VERSION "ZCUD_CANFD3"

NS_ :

BS_:

BU_: ASDM ETC HVFM SRS3 SUM XCM ZCUD ZCUT

BO_ 85 ZcudZCUDCANFD3Fr01: 64 ZCUD
 SG_ EscSt_UB : 192|1@0+ (1,0) [0|1] "" Vector__XXX
 SG_ EscStChks : 191|8@0+ (1,0) [0|255] "Unitless" Vector__XXX
 SG_ EscStCntr : 199|4@0+ (1,0) [0|15] "Unitless" Vector__XXX
 SG_ EscStEscSt : 195|3@0+ (1,0) [0|7] "" Vector__XXX
 SG_ GearLvrIndcn : 43|3@0+ (1,0) [0|7] "" Vector__XXX
 SG_ GearLvrIndcn_UB : 40|1@0+ (1,0) [0|1] "" Vector__XXX
 SG_ GVMCPrpsnTqDistReq_UB : 475|1@0+ (1,0) [0|1] "" XCM
 SG_ GVMCPrpsnTqDistReqChks : 471|8@0+ (1,0) [0|255] "Unitless" XCM
 SG_ GVMCPrpsnTqDistReqCntr : 479|4@0+ (1,0) [0|15] "Unitless" XCM
 SG_ GVMCPrpsnTqDistReqCtrlMod : 456|1@0+ (1,0) [0|1] "" XCM
 SG_ GVMCPrpsnTqDistReqDistReq : 455|15@0+ (0.00390625,0) [0|100] "%" XCM
 SG_ GVMCSteerWhlAgReqFrnt_UB : 276|1@0+ (1,0) [0|1] "" Vector__XXX
 SG_ GVMCSteerWhlAgReqFrntChks : 258|8@0+ (1,0) [0|255] "Unitless" Vector__XXX
 SG_ GVMCSteerWhlAgReqFrntCntr : 266|4@0+ (1,0) [0|15] "Unitless" Vector__XXX
 SG_ GVMCSteerWhlAgReqFrntSteerWhlAgCtrl : 239|15@0- (9.765625E-4,0) [-14.5|14.5] "rad" Vector__XXX
 SG_ GVMCSteerWhlAgReqFrntSteerWhlCtrlSts : 278|2@0+ (1,0) [0|3] "" Vector__XXX
 SG_ GVMCSteerWhlAgReqFrntSteerWhlTqCtrl : 240|14@0- (0.00390625,0) [-30|30] "NewtonMeter" Vector__XXX
 SG_ GVMCVehCtrlrSts_UB : 363|1@0+ (1,0) [0|1] "" XCM
 SG_ GVMCVehCtrlrStsChks : 351|8@0+ (1,0) [0|255] "Unitless" XCM
 SG_ GVMCVehCtrlrStsCntr : 367|4@0+ (1,0) [0|15] "Unitless" XCM
 SG_ GVMCVehCtrlrStsCtrlrSts : 359|8@0+ (1,0) [0|255] "" XCM
 SG_ GVMCVehVAct_UB : 125|1@0+ (1,0) [0|1] "" XCM
 SG_ GVMCVehVActLatAct : 95|16@0+ (0.00391,-30) [-30|34.05753] "m/s" XCM
 SG_ GVMCVehVActLgtAct : 111|16@0+ (0.00391,-30) [-30|34.05753] "m/s" XCM
 SG_ GVMCVehVActQf : 127|2@0+ (1,0) [0|3] "" XCM
 SG_ GVMCVehYawRateTar : 287|32@0+ (1,-10) [-10|10] "rad/s" XCM
 SG_ GVMCVehYawRateTar_UB : 123|1@0+ (1,0) [0|1] "" XCM
 SG_ GVMCYawRateCOGAct_UB : 181|1@0+ (1,0) [0|1] "" XCM
 SG_ GVMCYawRateCOGActAct : 167|16@0+ (2.4E-4,-6) [-6|9.7284] "rad/s" XCM
 SG_ GVMCYawRateCOGActQf : 183|2@0+ (1,0) [0|3] "" XCM
 SG_ LatCtrlReqSafe_UB : 336|1@0+ (1,0) [0|1] "" Vector__XXX
 SG_ LatCtrlReqSafeChks : 321|8@0+ (1,0) [0|255] "Unitless" Vector__XXX
 SG_ LatCtrlReqSafeCntr : 329|4@0+ (1,0) [0|15] "Unitless" Vector__XXX
 SG_ LatCtrlReqSafeLatCtrlModReq : 341|4@0+ (1,0) [0|15] "" Vector__XXX
 SG_ LatCtrlReqSafeSteerTqReq : 319|14@0- (0.00390625,0) [-30|30] "NewtonMeter" Vector__XXX
 SG_ LatCtrlReqSafeSteerWhlHptcWarnReq : 337|1@0+ (1,0) [0|1] "" Vector__XXX
 SG_ SteerWhlSnsr_UB : 44|1@0+ (1,0) [0|1] "" Vector__XXX
 SG_ SteerWhlSnsrAg : 7|15@0- (9.765625E-4,0) [-14.5|14.5] "rad" Vector__XXX
 SG_ SteerWhlSnsrAgSpd : 8|14@0- (0.0078125,0) [-50|50] "rad/s" Vector__XXX
 SG_ SteerWhlSnsrChks : 26|8@0+ (1,0) [0|255] "Unitless" Vector__XXX
 SG_ SteerWhlSnsrCntr : 34|4@0+ (1,0) [0|15] "Unitless" Vector__XXX
 SG_ SteerWhlSnsrQf : 46|2@0+ (1,0) [0|3] "" Vector__XXX
 SG_ VehModMngtGlbSafe1_UB : 80|1@0+ (1,0) [0|1] "" HVFM,SUM
 SG_ VehModMngtGlbSafe1CarModSts1 : 87|3@0+ (1,0) [0|7] "" HVFM,SUM
 SG_ VehModMngtGlbSafe1CarModSubtypWdCarModSubtyp : 84|3@0+ (1,0) [0|7] "Unitless" HVFM,SUM
 SG_ VehModMngtGlbSafe1Chks : 55|8@0+ (1,0) [0|255] "Unitless" HVFM,SUM
 SG_ VehModMngtGlbSafe1Cntr : 63|4@0+ (1,0) [0|15] "Unitless" HVFM,SUM
 SG_ VehModMngtGlbSafe1EgyLvlElecMai : 59|4@0+ (1,0) [0|15] "Unitless" HVFM,SUM
 SG_ VehModMngtGlbSafe1EgyLvlElecSubtyp : 71|4@0+ (1,0) [0|15] "Unitless" HVFM,SUM
 SG_ VehModMngtGlbSafe1FltEgyCnsWdSts : 81|1@0+ (1,0) [0|1] "" HVFM,SUM
 SG_ VehModMngtGlbSafe1PwrLvlElecMai : 67|4@0+ (1,0) [0|15] "Unitless" HVFM,SUM
 SG_ VehModMngtGlbSafe1PwrLvlElecSubtyp : 79|4@0+ (1,0) [0|15] "Unitless" HVFM,SUM
 SG_ VehModMngtGlbSafe1UsgModSts : 75|4@0+ (1,0) [0|15] "" HVFM,SUM
 SG_ VehMtnSt_UB : 208|1@0+ (1,0) [0|1] "" ZCUT
 SG_ VehMtnStChks : 207|8@0+ (1,0) [0|255] "Unitless" ZCUT
 SG_ VehMtnStCntr : 215|4@0+ (1,0) [0|15] "Unitless" ZCUT
 SG_ VehMtnStVehMtnSt : 211|3@0+ (1,0) [0|7] "" ZCUT
 SG_ VehSpdLgt_UB : 154|1@0+ (1,0) [0|1] "" HVFM,SUM,ZCUT
 SG_ VehSpdLgtA : 135|15@0+ (0.00391,0) [0|125.0027] "m/s" HVFM,SUM,ZCUT
 SG_ VehSpdLgtChks : 136|8@0+ (1,0) [0|255] "Unitless" HVFM,SUM,ZCUT
 SG_ VehSpdLgtCntr : 144|4@0+ (1,0) [0|15] "Unitless" HVFM,SUM,ZCUT
 SG_ VehSpdLgtQf : 156|2@0+ (1,0) [0|3] "" HVFM,SUM,ZCUT
 SG_ WhlFastSpdSafe_UB : 442|1@0+ (1,0) [0|1] "" Vector__XXX
 SG_ WhlFastSpdSafeA : 423|15@0+ (0.00391,0) [0|125.0027] "m/s" Vector__XXX
 SG_ WhlFastSpdSafeChks : 424|8@0+ (1,0) [0|255] "Unitless" Vector__XXX
 SG_ WhlFastSpdSafeCntr : 432|4@0+ (1,0) [0|15] "Unitless" Vector__XXX
 SG_ WhlFastSpdSafeQF : 444|2@0+ (1,0) [0|3] "" Vector__XXX
 SG_ WhlRotToothCntr_UB : 411|1@0+ (1,0) [0|1] "" Vector__XXX
 SG_ WhlRotToothCntrChks : 375|8@0+ (1,0) [0|255] "Unitless" Vector__XXX
 SG_ WhlRotToothCntrCntr : 415|4@0+ (1,0) [0|15] "Unitless" Vector__XXX
 SG_ WhlRotToothCntrFrntLe : 383|8@0+ (1,0) [0|255] "Unitless" Vector__XXX
 SG_ WhlRotToothCntrFrntRi : 391|8@0+ (1,0) [0|255] "Unitless" Vector__XXX
 SG_ WhlRotToothCntrReLe : 399|8@0+ (1,0) [0|255] "Unitless" Vector__XXX
 SG_ WhlRotToothCntrReRi : 407|8@0+ (1,0) [0|255] "Unitless" Vector__XXX
 SG_ YawRateReqdByDrvr : 223|16@0- (2.44140625E-4,0) [-5|5] "rad/s" Vector__XXX
 SG_ YawRateReqdByDrvr_UB : 124|1@0+ (1,0) [0|1] "" Vector__XXX

BO_ 339 ZcudZCUDCANFD3Fr02: 64 ZCUD
 SG_ DrvrGearShiftDirReq1_UB : 46|1@0+ (1,0) [0|1] "" Vector__XXX
 SG_ DrvrGearShiftDirReq1Chks : 31|8@0+ (1,0) [0|255] "Unitless" Vector__XXX
 SG_ DrvrGearShiftDirReq1Cntr : 39|4@0+ (1,0) [0|15] "Unitless" Vector__XXX
 SG_ DrvrGearShiftDirReq1DwnDwnTipAut : 35|1@0+ (1,0) [0|1] "" Vector__XXX
 SG_ DrvrGearShiftDirReq1DwnTipAut : 34|1@0+ (1,0) [0|1] "" Vector__XXX
 SG_ DrvrGearShiftDirReq1PosnAut : 33|1@0+ (1,0) [0|1] "" Vector__XXX
 SG_ DrvrGearShiftDirReq1UpTipAut : 32|1@0+ (1,0) [0|1] "" Vector__XXX
 SG_ DrvrGearShiftDirReq1UpUpTipAut : 47|1@0+ (1,0) [0|1] "" Vector__XXX
 SG_ DrvrGearShiftDirReq2_UB : 60|1@0+ (1,0) [0|1] "" Vector__XXX
 SG_ DrvrGearShiftDirReq2Chks : 45|8@0+ (1,0) [0|255] "Unitless" Vector__XXX
 SG_ DrvrGearShiftDirReq2Cntr : 53|4@0+ (1,0) [0|15] "Unitless" Vector__XXX
 SG_ DrvrGearShiftDirReq2DwnDwnTipAut : 49|1@0+ (1,0) [0|1] "" Vector__XXX
 SG_ DrvrGearShiftDirReq2DwnTipAut : 48|1@0+ (1,0) [0|1] "" Vector__XXX
 SG_ DrvrGearShiftDirReq2PosnAut : 63|1@0+ (1,0) [0|1] "" Vector__XXX
 SG_ DrvrGearShiftDirReq2UpTipAut : 62|1@0+ (1,0) [0|1] "" Vector__XXX
 SG_ DrvrGearShiftDirReq2UpUpTipAut : 61|1@0+ (1,0) [0|1] "" Vector__XXX
 SG_ RWASteerLockReq_UB : 189|1@0+ (1,0) [0|1] "" Vector__XXX
 SG_ RWASteerLockReqCommand : 191|2@0+ (1,0) [0|3] "" Vector__XXX
 SG_ RWASteerLockReqSteerLockDataReq0 : 135|8@0+ (1,0) [0|255] "Unitless" Vector__XXX
 SG_ RWASteerLockReqSteerLockDataReq1 : 143|8@0+ (1,0) [0|255] "Unitless" Vector__XXX
 SG_ RWASteerLockReqSteerLockDataReq2 : 151|8@0+ (1,0) [0|255] "Unitless" Vector__XXX
 SG_ RWASteerLockReqSteerLockDataReq3 : 159|8@0+ (1,0) [0|255] "Unitless" Vector__XXX
 SG_ RWASteerLockReqSteerLockDataReq4 : 167|8@0+ (1,0) [0|255] "Unitless" Vector__XXX
 SG_ RWASteerLockReqSteerLockDataReq5 : 175|8@0+ (1,0) [0|255] "Unitless" Vector__XXX
 SG_ RWASteerLockReqSteerLockDataReq6 : 183|8@0+ (1,0) [0|255] "Unitless" Vector__XXX
 SG_ SteerEmergCtrlSwt : 127|1@0+ (1,0) [0|1] "" Vector__XXX
 SG_ SteerEmergCtrlSwt_UB : 126|1@0+ (1,0) [0|1] "" Vector__XXX
 SG_ SteerRatModReq : 101|5@0+ (1,0) [0|31] "" Vector__XXX
 SG_ SteerRatModReq_UB : 96|1@0+ (1,0) [0|1] "" Vector__XXX
 SG_ SteerSetg_UB : 80|1@0+ (1,0) [0|1] "" Vector__XXX
 SG_ SteerSetgPen : 74|4@0+ (1,0) [0|15] "" Vector__XXX
 SG_ SteerSetgSteerAsscLvl : 86|3@0+ (1,0) [0|7] "" Vector__XXX
 SG_ SteerSetgSteerMod : 83|3@0+ (1,0) [0|7] "" Vector__XXX
 SG_ SuspCmprSpd : 95|9@0+ (1,0) [0|511] "rpm" SUM
 SG_ SuspCmprSpd_UB : 102|1@0+ (1,0) [0|1] "" SUM
 SG_ SuspDistbnVlvCtrlSts_UB : 113|1@0+ (1,0) [0|1] "" SUM
 SG_ SuspDistbnVlvCtrlStsChks : 11|8@0+ (1,0) [0|255] "Unitless" SUM
 SG_ SuspDistbnVlvCtrlStsCntr : 19|4@0+ (1,0) [0|15] "Unitless" SUM
 SG_ SuspDistbnVlvCtrlStsSuspDistbnVlvCtrlSts : 7|12@0+ (1,0) [0|4095] "Unitless" SUM
 SG_ SuspStfnVlvCtrlSts_UB : 122|1@0+ (1,0) [0|1] "" SUM
 SG_ SuspStfnVlvCtrlStsFL : 111|2@0+ (1,0) [0|3] "" SUM
 SG_ SuspStfnVlvCtrlStsFR : 109|2@0+ (1,0) [0|3] "" SUM
 SG_ SuspStfnVlvCtrlStsRL : 107|2@0+ (1,0) [0|3] "" SUM
 SG_ SuspStfnVlvCtrlStsRR : 105|2@0+ (1,0) [0|3] "" SUM
 SG_ ZCAirSuspCtrlSts_UB : 201|1@0+ (1,0) [0|1] "" SUM
 SG_ ZCAirSuspCtrlStsChks : 199|8@0+ (1,0) [0|255] "Unitless" SUM
 SG_ ZCAirSuspCtrlStsCntr : 207|4@0+ (1,0) [0|15] "Unitless" SUM
 SG_ ZCAirSuspCtrlStsZCAirSuspCtrlSts : 203|2@0+ (1,0) [0|3] "" SUM

BO_ 289 ZcudZCUDCANFD3Fr03: 64 ZCUD
 SG_ BBWPullOverReq : 67|1@0+ (1,0) [0|1] "" ASDM
 SG_ BBWPullOverReq_UB : 66|1@0+ (1,0) [0|1] "" ASDM
 SG_ BrkPedlPsd_UB : 68|1@0+ (1,0) [0|1] "" Vector__XXX
 SG_ BrkPedlPsdBrkPedlNotPsdSafe : 49|1@0+ (1,0) [0|1] "" Vector__XXX
 SG_ BrkPedlPsdBrkPedlPsd : 48|1@0+ (1,0) [0|1] "" Vector__XXX
 SG_ BrkPedlPsdChks : 47|8@0+ (1,0) [0|255] "Unitless" Vector__XXX
 SG_ BrkPedlPsdCntr : 55|4@0+ (1,0) [0|15] "Unitless" Vector__XXX
 SG_ BrkPedlPsdQf : 51|2@0+ (1,0) [0|3] "" Vector__XXX
 SG_ ChassisObstclCrsModIncn : 34|2@0+ (1,0) [0|3] "" ZCUT
 SG_ ChassisObstclCrsModIncn_UB : 32|1@0+ (1,0) [0|1] "" ZCUT
 SG_ HeiLimModIncn : 71|2@0+ (1,0) [0|3] "" ZCUT
 SG_ HeiLimModIncn_UB : 69|1@0+ (1,0) [0|1] "" ZCUT
 SG_ PTALgtLimnlnd : 79|12@0+ (0.01,-12) [-12|12] "m/s^2" ASDM
 SG_ PTALgtLimnlnd_UB : 83|1@0+ (1,0) [0|1] "" ASDM

BO_ 1173 ZcudZCUDCANFD3Fr05: 64 ZCUD
 SG_ BkpOfDstTrvld : 63|21@0+ (1,0) [0|2000000] "km" HVFM,SUM
 SG_ BkpOfDstTrvld_UB : 74|1@0+ (1,0) [0|1] "" HVFM,SUM
 SG_ CarTiGlb : 7|32@0+ (0.1,0) [0|429496729.5] "s" HVFM,SUM
 SG_ CarTiGlb_UB : 39|1@0+ (1,0) [0|1] "" HVFM,SUM
 SG_ TiAndDateIndcn_UB : 73|1@0+ (1,0) [0|1] "" HVFM,SUM
 SG_ TiAndDateIndcnDataValid : 175|1@0+ (1,0) [0|1] "" HVFM,SUM
 SG_ TiAndDateIndcnDay : 196|5@0+ (1,0) [1|31] "Days" HVFM,SUM
 SG_ TiAndDateIndcnHr1 : 204|5@0+ (1,0) [0|23] "hours" HVFM,SUM
 SG_ TiAndDateIndcnMins1 : 181|6@0+ (1,0) [0|59] "Mins" HVFM,SUM
 SG_ TiAndDateIndcnMth1 : 211|4@0+ (1,0) [1|12] "Month" HVFM,SUM
 SG_ TiAndDateIndcnSec1 : 189|6@0+ (1,0) [0|59] "s" HVFM,SUM
 SG_ TiAndDateIndcnYr1 : 174|7@0+ (1,0) [0|99] "Year" HVFM,SUM
 SG_ VehBattU_UB : 229|1@0+ (1,0) [0|1] "" HVFM,SUM
 SG_ VehBattUSysU : 223|8@0+ (0.1,0) [0|25] "Volt" HVFM,SUM
 SG_ VehBattUSysUQf : 231|2@0+ (1,0) [0|3] "" HVFM,SUM

BO_ 569 ZcudZCUDCANFD3Fr06: 64 ZCUD
 SG_ BattIRaw : 95|16@0+ (0.015625,-512) [-512|511.984375] "A" Vector__XXX
 SG_ BattIRaw_UB : 128|1@0+ (1,0) [0|1] "" Vector__XXX
 SG_ BattRemainTimeToEmpty : 111|15@0+ (0.1,0) [0|3076.7] "Mins" Vector__XXX
 SG_ BattRemainTimeToEmpty_UB : 112|1@0+ (1,0) [0|1] "" Vector__XXX
 SG_ DrvModReq : 127|5@0+ (1,0) [0|31] "" Vector__XXX
 SG_ DrvModReq_UB : 122|1@0+ (1,0) [0|1] "" Vector__XXX
 SG_ DrvrSeatSnsrSts : 143|2@0+ (1,0) [0|3] "" Vector__XXX
 SG_ DrvrSeatSnsrSts_UB : 141|1@0+ (1,0) [0|1] "" Vector__XXX
 SG_ DrvrSeatSts : 140|2@0+ (1,0) [0|3] "" Vector__XXX
 SG_ DrvrSeatSts_UB : 138|1@0+ (1,0) [0|1] "" Vector__XXX
 SG_ IAMSMod : 121|1@0+ (1,0) [0|1] "" ZCUT
 SG_ IAMSMod_UB : 120|1@0+ (1,0) [0|1] "" ZCUT
 SG_ LockgCenSts_UB : 152|1@0+ (1,0) [0|1] "" Vector__XXX
 SG_ LockgCenStsLockSt : 155|2@0+ (1,0) [0|3] "" Vector__XXX
 SG_ LockgCenStsTrigSrc : 159|4@0+ (1,0) [0|15] "" Vector__XXX
 SG_ LockgCenStsUpdEve : 153|1@0+ (1,0) [0|1] "" Vector__XXX
 SG_ PtTqAtWhlFrntAct_UB : 56|1@0+ (1,0) [0|1] "" Vector__XXX
 SG_ PtTqAtWhlFrntActChks : 55|8@0+ (1,0) [0|255] "Unitless" Vector__XXX
 SG_ PtTqAtWhlFrntActCntr : 63|4@0+ (1,0) [0|15] "Unitless" Vector__XXX
 SG_ PtTqAtWhlFrntActPtTqAtAxleFrntAct : 7|16@0- (1,0) [-20000|20000] "NewtonMeter" Vector__XXX
 SG_ PtTqAtWhlFrntActPtTqAtWhlFrntLeAct : 23|16@0- (1,0) [-20000|20000] "NewtonMeter" Vector__XXX
 SG_ PtTqAtWhlFrntActPtTqAtWhlFrntRiAct : 39|16@0- (1,0) [-20000|20000] "NewtonMeter" Vector__XXX
 SG_ PtTqAtWhlFrntActPtTqAtWhlsFrntQly : 59|3@0+ (1,0) [0|7] "" Vector__XXX
 SG_ PVMCSteerAst : 135|3@0+ (1,0) [0|7] "" Vector__XXX
 SG_ PVMCSteerAst_UB : 132|1@0+ (1,0) [0|1] "" Vector__XXX

BO_ 625 ZcudZCUDCANFD3Fr07: 64 ZCUD
 SG_ AmbTRaw_UB : 18|1@0+ (1,0) [0|1] "" Vector__XXX
 SG_ AmbTRawAmbTVal : 15|11@0+ (0.1,-70) [-70|134.7] "degC" Vector__XXX
 SG_ AmbTRawQly : 20|2@0+ (1,0) [0|3] "" Vector__XXX
 SG_ DstEstimdToEmptyForDrvgElec : 31|11@0+ (1,0) [0|2047] "KiloMtr" ASDM
 SG_ DstEstimdToEmptyForDrvgElec_UB : 36|1@0+ (1,0) [0|1] "" ASDM
 SG_ DstEstimdToEmptyForDrvgElecPredTyp2 : 35|11@0+ (1,0) [0|2047] "KiloMtr" ASDM
 SG_ DstEstimdToEmptyForDrvgElecPredTyp2_UB : 40|1@0+ (1,0) [0|1] "" ASDM
 SG_ DstEstimdToEmptyForDynElec : 55|11@0+ (1,0) [0|2047] "KiloMtr" ASDM
 SG_ DstEstimdToEmptyForDynElec_UB : 60|1@0+ (1,0) [0|1] "" ASDM
 SG_ DstToEmptyIndcdDstToEmpty1 : 71|13@0+ (1,0) [0|8191] "KiloMtr" ASDM
 SG_ DstToEmptyIndcdDstToEmpty1_UB : 74|1@0+ (1,0) [0|1] "" ASDM
 SG_ DstToEmptyIndcdDstToEmpty2 : 87|13@0+ (1,0) [0|8191] "KiloMtr" ASDM
 SG_ DstToEmptyIndcdDstToEmpty2_UB : 90|1@0+ (1,0) [0|1] "" ASDM
 SG_ DstToEmptyIndcdDstToEmpty3 : 103|13@0+ (1,0) [0|8191] "KiloMtr" ASDM
 SG_ DstToEmptyIndcdDstToEmpty3_UB : 106|1@0+ (1,0) [0|1] "" ASDM

BO_ 131 ZcudZCUDCANFD3Fr08: 16 ZCUD
 SG_ DPAAgReqGroup1_UB : 97|1@0+ (1,0) [0|1] "" XCM
 SG_ DPAAgReqGroup1Chks : 93|8@0+ (1,0) [0|255] "Unitless" XCM
 SG_ DPAAgReqGroup1Cntr : 101|4@0+ (1,0) [0|15] "Unitless" XCM
 SG_ DPAAgReqGroup1RtonAgReq : 55|14@0+ (0.05,-360) [-360|459.15] "Deg" XCM
 SG_ DPAAgReqGroup1TrgtAg : 57|14@0+ (0.05,-360) [-360|459.15] "Deg" XCM
 SG_ DPAAgReqGroup1VehAtaRtonlAg : 75|14@0+ (0.05,-360) [-360|459.15] "Deg" XCM
 SG_ DPAAgReqGroup_UB : 96|1@0+ (1,0) [0|1] "" XCM
 SG_ DPAAgReqGroupChks : 47|8@0+ (1,0) [0|255] "Unitless" XCM
 SG_ DPAAgReqGroupCntr : 35|4@0+ (1,0) [0|15] "Unitless" XCM
 SG_ DPAAgReqGroupRtonAgReq : 7|12@0+ (0.1,0) [0|360] "Deg" XCM
 SG_ DPAAgReqGroupTrgtAg : 11|12@0+ (0.1,0) [0|360] "Deg" XCM
 SG_ DPAAgReqGroupVehAtaRtonlAg : 31|12@0+ (0.1,0) [0|360] "Deg" XCM

BO_ 102 ZcudZCUDCANFD3Fr09: 64 ZCUD
 SG_ AbsCtrlActv_UB : 138|1@0+ (1,0) [0|1] "" ZCUT
 SG_ AbsCtrlActvChks : 135|8@0+ (1,0) [0|255] "Unitless" ZCUT
 SG_ AbsCtrlActvCntr : 143|4@0+ (1,0) [0|15] "Unitless" ZCUT
 SG_ AbsCtrlActvCtrlSts1 : 139|1@0+ (1,0) [0|1] "" ZCUT
 SG_ BrkTracCtrlActv : 66|1@0+ (1,0) [0|1] "" Vector__XXX
 SG_ BrkTracCtrlActv_UB : 65|1@0+ (1,0) [0|1] "" Vector__XXX
 SG_ GVMCPrpsnTqDistbnReqAtAxleRe_UB : 328|1@0+ (1,0) [0|1] "" XCM
 SG_ GVMCPrpsnTqDistbnReqAtAxleReChks : 325|8@0+ (1,0) [0|255] "Unitless" XCM
 SG_ GVMCPrpsnTqDistbnReqAtAxleReCntr : 333|4@0+ (1,0) [0|15] "Unitless" XCM
 SG_ GVMCPrpsnTqDistbnReqAtAxleReCtrlMod : 329|1@0+ (1,0) [0|1] "" XCM
 SG_ GVMCPrpsnTqDistbnReqAtAxleReDistReq : 311|18@0+ (0.01,-1000) [-1000|1621.43] "%" XCM
 SG_ GVMCSuspDampgCtrlReq_UB : 67|1@0+ (1,0) [0|1] "" ZCUT
 SG_ GVMCSuspDampgCtrlReqGVMCDampgCtrlReqFL : 7|16@0- (1,0) [-20000|20000] "N" ZCUT
 SG_ GVMCSuspDampgCtrlReqGVMCDampgCtrlReqFR : 23|16@0- (1,0) [-20000|20000] "N" ZCUT
 SG_ GVMCSuspDampgCtrlReqGVMCDampgCtrlReqRL : 39|16@0- (1,0) [-20000|20000] "N" ZCUT
 SG_ GVMCSuspDampgCtrlReqGVMCDampgCtrlReqRR : 55|16@0- (1,0) [-20000|20000] "N" ZCUT
 SG_ GVMCSuspDampgCtrlReqGVMCSuspDampgCtrlMod : 71|2@0+ (1,0) [0|3] "" ZCUT
 SG_ GVMCSuspDampgCtrlReqGVMCSuspDampgModReq : 69|2@0+ (1,0) [0|3] "" ZCUT
 SG_ PVMCSuspHeiCtrlReq_UB : 406|1@0+ (1,0) [0|1] "" ZCUT
 SG_ PVMCSuspHeiCtrlReqGVMCSuspPosnCtrlMod : 392|2@0+ (1,0) [0|3] "" ZCUT
 SG_ PVMCSuspHeiCtrlReqGVMCSuspPosnFLReq : 343|15@0- (6.2E-5,0) [-0.999998|1.00006] "m" ZCUT
 SG_ PVMCSuspHeiCtrlReqGVMCSuspPosnFRReq : 344|15@0- (6.2E-5,0) [-0.999998|1.00006] "m" ZCUT
 SG_ PVMCSuspHeiCtrlReqGVMCSuspPosnModReq : 395|3@0+ (1,0) [0|7] "" ZCUT
 SG_ PVMCSuspHeiCtrlReqGVMCSuspPosnRLReq : 361|15@0- (6.2E-5,0) [-0.999998|1.00006] "m" ZCUT
 SG_ PVMCSuspHeiCtrlReqGVMCSuspPosnRRReq : 378|15@0- (6.2E-5,0) [-0.999998|1.00006] "m" ZCUT
 SG_ PVMCVehCtrlSts2_UB : 124|1@0+ (1,0) [0|1] "" XCM,ZCUT
 SG_ PVMCVehCtrlSts2ActrTarFctSts : 83|3@0+ (1,0) [0|7] "" XCM,ZCUT
 SG_ PVMCVehCtrlSts2BbWBackUpFctSts : 97|3@0+ (1,0) [0|7] "" XCM,ZCUT
 SG_ PVMCVehCtrlSts2BrkDiscClngFctSts : 107|3@0+ (1,0) [0|7] "" XCM,ZCUT
 SG_ PVMCVehCtrlSts2BrkTqDeltaFctSts : 114|3@0+ (1,0) [0|7] "" XCM,ZCUT
 SG_ PVMCVehCtrlSts2Chks : 79|8@0+ (1,0) [0|255] "Unitless" XCM,ZCUT
 SG_ PVMCVehCtrlSts2Cntr : 87|4@0+ (1,0) [0|15] "Unitless" XCM,ZCUT
 SG_ PVMCVehCtrlSts2CrabMovgFctSts : 80|3@0+ (1,0) [0|7] "" XCM,ZCUT
 SG_ PVMCVehCtrlSts2DecelReqActrSts : 90|3@0+ (1,0) [0|7] "" XCM,ZCUT
 SG_ PVMCVehCtrlSts2FloatingDrvgFctSts : 103|3@0+ (1,0) [0|7] "" XCM,ZCUT
 SG_ PVMCVehCtrlSts2LowSpdStrFctSts : 100|3@0+ (1,0) [0|7] "" XCM,ZCUT
 SG_ PVMCVehCtrlSts2SbWBackUpLatFctSts : 93|3@0+ (1,0) [0|7] "" XCM,ZCUT
 SG_ PVMCVehCtrlSts2SbWBackUpLgtFctSts : 104|3@0+ (1,0) [0|7] "" XCM,ZCUT
 SG_ PVMCVehCtrlSts2TankTurnFctSts : 117|3@0+ (1,0) [0|7] "" XCM,ZCUT
 SG_ PVMCVehCtrlSts2VDSWFctSts : 110|3@0+ (1,0) [0|7] "" XCM,ZCUT
 SG_ PVMCVehCtrlSts2ViolentModFctSts : 127|3@0+ (1,0) [0|7] "" XCM,ZCUT
 SG_ VehArbtSpdMax : 247|8@0+ (0.4,0) [0|102] "m/s" ASDM
 SG_ VehArbtSpdMax_UB : 64|1@0+ (1,0) [0|1] "" ASDM
 SG_ VehSpdLimSrc : 255|4@0+ (1,0) [0|15] "" ASDM
 SG_ VehSpdLimSrc_UB : 251|1@0+ (1,0) [0|1] "" ASDM
 SG_ WhlSpdCircumlFrnt_UB : 185|1@0+ (1,0) [0|1] "" Vector__XXX
 SG_ WhlSpdCircumlFrntChks : 169|8@0+ (1,0) [0|255] "Unitless" Vector__XXX
 SG_ WhlSpdCircumlFrntCntr : 177|4@0+ (1,0) [0|15] "Unitless" Vector__XXX
 SG_ WhlSpdCircumlFrntLe : 151|15@0+ (0.00391,0) [0|125.0027] "m/s" Vector__XXX
 SG_ WhlSpdCircumlFrntLeQf : 189|2@0+ (1,0) [0|3] "" Vector__XXX
 SG_ WhlSpdCircumlFrntRiQf : 187|2@0+ (1,0) [0|3] "" Vector__XXX
 SG_ WhlSpdCircumlFrntWhlSpdCircumlFrntRi : 152|15@0+ (0.00391,0) [0|125.0027] "m/s" Vector__XXX
 SG_ WhlSpdCircumlRe_UB : 233|1@0+ (1,0) [0|1] "" Vector__XXX
 SG_ WhlSpdCircumlReChks : 217|8@0+ (1,0) [0|255] "Unitless" Vector__XXX
 SG_ WhlSpdCircumlReCntr : 225|4@0+ (1,0) [0|15] "Unitless" Vector__XXX
 SG_ WhlSpdCircumlReLe : 199|15@0+ (0.00391,0) [0|125.0027] "m/s" Vector__XXX
 SG_ WhlSpdCircumlReLeQf : 237|2@0+ (1,0) [0|3] "" Vector__XXX
 SG_ WhlSpdCircumlReRi : 200|15@0+ (0.00391,0) [0|125.0027] "m/s" Vector__XXX
 SG_ WhlSpdCircumlReRiQf : 235|2@0+ (1,0) [0|3] "" Vector__XXX

BO_ 549 ZcudZCUDCANFD3Fr10: 64 ZCUD
 SG_ VehCfgPrm_UB : 363|1@0+ (1,0) [0|1] "" HVFM,SUM
 SG_ VehCfgPrmBlkIDBytePosn1 : 7|8@0+ (1,0) [0|255] "Unitless" HVFM,SUM
 SG_ VehCfgPrmCCPBytePosn2 : 15|8@0+ (1,0) [0|255] "Unitless" HVFM,SUM
 SG_ VehCfgPrmCCPBytePosn3 : 23|8@0+ (1,0) [0|255] "Unitless" HVFM,SUM
 SG_ VehCfgPrmCCPBytePosn4 : 31|8@0+ (1,0) [0|255] "Unitless" HVFM,SUM
 SG_ VehCfgPrmCCPBytePosn5 : 39|8@0+ (1,0) [0|255] "Unitless" HVFM,SUM
 SG_ VehCfgPrmCCPBytePosn6 : 47|8@0+ (1,0) [0|255] "Unitless" HVFM,SUM
 SG_ VehCfgPrmCCPBytePosn7 : 55|8@0+ (1,0) [0|255] "Unitless" HVFM,SUM
 SG_ VehCfgPrmCCPBytePosn8 : 63|8@0+ (1,0) [0|255] "Unitless" HVFM,SUM
 SG_ VehCfgPrmExt2_UB : 361|1@0+ (1,0) [0|1] "" HVFM,SUM
 SG_ VehCfgPrmExt2BlkIDBytePosn1 : 135|8@0+ (1,0) [0|255] "Unitless" HVFM,SUM
 SG_ VehCfgPrmExt2CCPBytePosn2 : 143|8@0+ (1,0) [0|255] "Unitless" HVFM,SUM
 SG_ VehCfgPrmExt2CCPBytePosn3 : 151|8@0+ (1,0) [0|255] "Unitless" HVFM,SUM
 SG_ VehCfgPrmExt2CCPBytePosn4 : 159|8@0+ (1,0) [0|255] "Unitless" HVFM,SUM
 SG_ VehCfgPrmExt2CCPBytePosn5 : 167|8@0+ (1,0) [0|255] "Unitless" HVFM,SUM
 SG_ VehCfgPrmExt2CCPBytePosn6 : 175|8@0+ (1,0) [0|255] "Unitless" HVFM,SUM
 SG_ VehCfgPrmExt2CCPBytePosn7 : 183|8@0+ (1,0) [0|255] "Unitless" HVFM,SUM
 SG_ VehCfgPrmExt2CCPBytePosn8 : 191|8@0+ (1,0) [0|255] "Unitless" HVFM,SUM
 SG_ VehCfgPrmExt_UB : 362|1@0+ (1,0) [0|1] "" HVFM,SUM
 SG_ VehCfgPrmExtBlkIDBytePosn1 : 71|8@0+ (1,0) [0|255] "Unitless" HVFM,SUM
 SG_ VehCfgPrmExtCCPBytePosn2 : 79|8@0+ (1,0) [0|255] "Unitless" HVFM,SUM
 SG_ VehCfgPrmExtCCPBytePosn3 : 87|8@0+ (1,0) [0|255] "Unitless" HVFM,SUM
 SG_ VehCfgPrmExtCCPBytePosn4 : 95|8@0+ (1,0) [0|255] "Unitless" HVFM,SUM
 SG_ VehCfgPrmExtCCPBytePosn5 : 103|8@0+ (1,0) [0|255] "Unitless" HVFM,SUM
 SG_ VehCfgPrmExtCCPBytePosn6 : 111|8@0+ (1,0) [0|255] "Unitless" HVFM,SUM
 SG_ VehCfgPrmExtCCPBytePosn7 : 119|8@0+ (1,0) [0|255] "Unitless" HVFM,SUM
 SG_ VehCfgPrmExtCCPBytePosn8 : 127|8@0+ (1,0) [0|255] "Unitless" HVFM,SUM

BO_ 752 ZcudZCUDCANFD3Fr12: 64 ZCUD
 SG_ CmptmtTFrnt_UB : 9|1@0+ (1,0) [0|1] "" Vector__XXX
 SG_ CmptmtTFrntCmptmtTFrnt : 7|11@0+ (0.1,-60) [-60|125] "degC" Vector__XXX
 SG_ CmptmtTFrntFanForCmptmtTRunng : 10|1@0+ (1,0) [0|1] "" Vector__XXX
 SG_ CmptmtTFrntQf : 12|2@0+ (1,0) [0|3] "" Vector__XXX
 SG_ LiBattInPWLock : 23|1@0+ (1,0) [0|1] "" Vector__XXX
 SG_ LiBattInPWLock_UB : 22|1@0+ (1,0) [0|1] "" Vector__XXX
 SG_ RlyPwrDistbnCmd1WdIgnRlyCmd : 31|1@0+ (1,0) [0|1] "" Vector__XXX
 SG_ RlyPwrDistbnCmd1WdIgnRlyCmd_UB : 30|1@0+ (1,0) [0|1] "" Vector__XXX
 SG_ ULoWarnLvPwrErr_UB : 43|1@0+ (1,0) [0|1] "" Vector__XXX
 SG_ ULoWarnLvPwrErrChks : 29|8@0+ (1,0) [0|255] "Unitless" Vector__XXX
 SG_ ULoWarnLvPwrErrCntr : 37|4@0+ (1,0) [0|15] "Unitless" Vector__XXX
 SG_ ULoWarnLvPwrErrLVPwrSplyErrSts : 33|4@0+ (1,0) [0|15] "" Vector__XXX
 SG_ ULoWarnLvPwrErrULoWarn : 45|2@0+ (1,0) [0|3] "" Vector__XXX

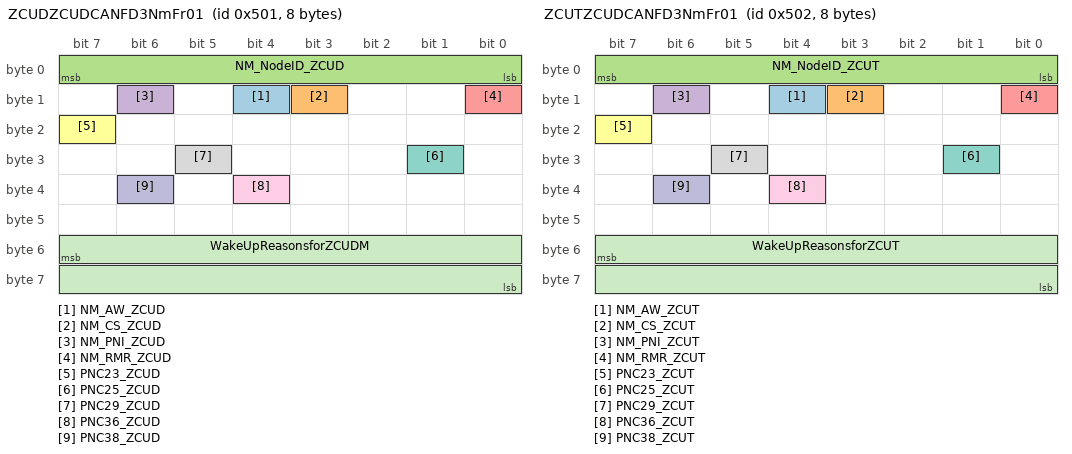
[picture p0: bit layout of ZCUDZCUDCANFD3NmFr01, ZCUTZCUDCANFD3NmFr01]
BO_ 1281 ZCUDZCUDCANFD3NmFr01: 8 ZCUD
 SG_ NM_AW_ZCUD : 12|1@0+ (1,0) [0|0] "" XCM
 SG_ NM_CS_ZCUD : 11|1@0+ (1,0) [0|0] "" XCM
 SG_ NM_NodeID_ZCUD : 7|8@0+ (1,0) [0|0] "" XCM
 SG_ NM_PNI_ZCUD : 14|1@0+ (1,0) [0|0] "" XCM
 SG_ NM_RMR_ZCUD : 8|1@0+ (1,0) [0|0] "" XCM
 SG_ PNC23_ZCUD : 23|1@0+ (1,0) [0|0] "" XCM
 SG_ PNC25_ZCUD : 25|1@0+ (1,0) [0|0] "" XCM
 SG_ PNC29_ZCUD : 29|1@0+ (1,0) [0|0] "" XCM
 SG_ PNC36_ZCUD : 36|1@0+ (1,0) [0|0] "" XCM
 SG_ PNC38_ZCUD : 38|1@0+ (1,0) [0|0] "" XCM
 SG_ WakeUpReasonsforZCUDM : 55|16@0+ (1,0) [0|65535] "" Vector__XXX

BO_ 1345 ZcudZCUDCANFD3VFCVectorFr: 8 ZCUD
 SG_ VFCVectorZCUDMBlockID : 7|2@0+ (1,0) [0|3] "Unitless" Vector__XXX
 SG_ VFCVectorZCUDMVFCid0 : 5|1@0+ (1,0) [0|1] "" Vector__XXX
 SG_ VFCVectorZCUDMVFCid1 : 4|1@0+ (1,0) [0|1] "" Vector__XXX
 SG_ VFCVectorZCUDMVFCid10 : 11|1@0+ (1,0) [0|1] "" Vector__XXX
 SG_ VFCVectorZCUDMVFCid11 : 10|1@0+ (1,0) [0|1] "" Vector__XXX
 SG_ VFCVectorZCUDMVFCid12 : 9|1@0+ (1,0) [0|1] "" Vector__XXX
 SG_ VFCVectorZCUDMVFCid13 : 8|1@0+ (1,0) [0|1] "" Vector__XXX
 SG_ VFCVectorZCUDMVFCid14 : 23|1@0+ (1,0) [0|1] "" Vector__XXX
 SG_ VFCVectorZCUDMVFCid15 : 22|1@0+ (1,0) [0|1] "" Vector__XXX
 SG_ VFCVectorZCUDMVFCid16 : 21|1@0+ (1,0) [0|1] "" Vector__XXX
 SG_ VFCVectorZCUDMVFCid17 : 20|1@0+ (1,0) [0|1] "" Vector__XXX
 SG_ VFCVectorZCUDMVFCid18 : 19|1@0+ (1,0) [0|1] "" Vector__XXX
 SG_ VFCVectorZCUDMVFCid19 : 18|1@0+ (1,0) [0|1] "" Vector__XXX
 SG_ VFCVectorZCUDMVFCid2 : 3|1@0+ (1,0) [0|1] "" Vector__XXX
 SG_ VFCVectorZCUDMVFCid20 : 17|1@0+ (1,0) [0|1] "" Vector__XXX
 SG_ VFCVectorZCUDMVFCid21 : 16|1@0+ (1,0) [0|1] "" Vector__XXX
 SG_ VFCVectorZCUDMVFCid22 : 31|1@0+ (1,0) [0|1] "" Vector__XXX
 SG_ VFCVectorZCUDMVFCid23 : 30|1@0+ (1,0) [0|1] "" Vector__XXX
 SG_ VFCVectorZCUDMVFCid24 : 29|1@0+ (1,0) [0|1] "" Vector__XXX
 SG_ VFCVectorZCUDMVFCid25 : 28|1@0+ (1,0) [0|1] "" Vector__XXX
 SG_ VFCVectorZCUDMVFCid26 : 27|1@0+ (1,0) [0|1] "" Vector__XXX
 SG_ VFCVectorZCUDMVFCid27 : 26|1@0+ (1,0) [0|1] "" Vector__XXX
 SG_ VFCVectorZCUDMVFCid28 : 25|1@0+ (1,0) [0|1] "" Vector__XXX
 SG_ VFCVectorZCUDMVFCid29 : 24|1@0+ (1,0) [0|1] "" Vector__XXX
 SG_ VFCVectorZCUDMVFCid3 : 2|1@0+ (1,0) [0|1] "" Vector__XXX
 SG_ VFCVectorZCUDMVFCid30 : 39|1@0+ (1,0) [0|1] "" Vector__XXX
 SG_ VFCVectorZCUDMVFCid31 : 38|1@0+ (1,0) [0|1] "" Vector__XXX
 SG_ VFCVectorZCUDMVFCid32 : 37|1@0+ (1,0) [0|1] "" Vector__XXX
 SG_ VFCVectorZCUDMVFCid33 : 36|1@0+ (1,0) [0|1] "" Vector__XXX
 SG_ VFCVectorZCUDMVFCid34 : 35|1@0+ (1,0) [0|1] "" Vector__XXX
 SG_ VFCVectorZCUDMVFCid35 : 34|1@0+ (1,0) [0|1] "" Vector__XXX
 SG_ VFCVectorZCUDMVFCid36 : 33|1@0+ (1,0) [0|1] "" Vector__XXX
 SG_ VFCVectorZCUDMVFCid37 : 32|1@0+ (1,0) [0|1] "" Vector__XXX
 SG_ VFCVectorZCUDMVFCid38 : 47|1@0+ (1,0) [0|1] "" Vector__XXX
 SG_ VFCVectorZCUDMVFCid39 : 46|1@0+ (1,0) [0|1] "" Vector__XXX
 SG_ VFCVectorZCUDMVFCid4 : 1|1@0+ (1,0) [0|1] "" Vector__XXX
 SG_ VFCVectorZCUDMVFCid40 : 45|1@0+ (1,0) [0|1] "" Vector__XXX
 SG_ VFCVectorZCUDMVFCid41 : 44|1@0+ (1,0) [0|1] "" Vector__XXX
 SG_ VFCVectorZCUDMVFCid42 : 43|1@0+ (1,0) [0|1] "" Vector__XXX
 SG_ VFCVectorZCUDMVFCid43 : 42|1@0+ (1,0) [0|1] "" Vector__XXX
 SG_ VFCVectorZCUDMVFCid44 : 41|1@0+ (1,0) [0|1] "" Vector__XXX
 SG_ VFCVectorZCUDMVFCid45 : 40|1@0+ (1,0) [0|1] "" Vector__XXX
 SG_ VFCVectorZCUDMVFCid46 : 55|1@0+ (1,0) [0|1] "" Vector__XXX
 SG_ VFCVectorZCUDMVFCid47 : 54|1@0+ (1,0) [0|1] "" Vector__XXX
 SG_ VFCVectorZCUDMVFCid48 : 53|1@0+ (1,0) [0|1] "" Vector__XXX
 SG_ VFCVectorZCUDMVFCid49 : 52|1@0+ (1,0) [0|1] "" Vector__XXX
 SG_ VFCVectorZCUDMVFCid5 : 0|1@0+ (1,0) [0|1] "" Vector__XXX
 SG_ VFCVectorZCUDMVFCid50 : 51|1@0+ (1,0) [0|1] "" Vector__XXX
 SG_ VFCVectorZCUDMVFCid51 : 50|1@0+ (1,0) [0|1] "" Vector__XXX
 SG_ VFCVectorZCUDMVFCid52 : 49|1@0+ (1,0) [0|1] "" Vector__XXX
 SG_ VFCVectorZCUDMVFCid53 : 48|1@0+ (1,0) [0|1] "" Vector__XXX
 SG_ VFCVectorZCUDMVFCid54 : 63|1@0+ (1,0) [0|1] "" Vector__XXX
 SG_ VFCVectorZCUDMVFCid55 : 62|1@0+ (1,0) [0|1] "" Vector__XXX
 SG_ VFCVectorZCUDMVFCid56 : 61|1@0+ (1,0) [0|1] "" Vector__XXX
 SG_ VFCVectorZCUDMVFCid57 : 60|1@0+ (1,0) [0|1] "" Vector__XXX
 SG_ VFCVectorZCUDMVFCid58 : 59|1@0+ (1,0) [0|1] "" Vector__XXX
 SG_ VFCVectorZCUDMVFCid59 : 58|1@0+ (1,0) [0|1] "" Vector__XXX
 SG_ VFCVectorZCUDMVFCid6 : 15|1@0+ (1,0) [0|1] "" Vector__XXX
 SG_ VFCVectorZCUDMVFCid60 : 57|1@0+ (1,0) [0|1] "" Vector__XXX
 SG_ VFCVectorZCUDMVFCid61 : 56|1@0+ (1,0) [0|1] "" Vector__XXX
 SG_ VFCVectorZCUDMVFCid7 : 14|1@0+ (1,0) [0|1] "" Vector__XXX
 SG_ VFCVectorZCUDMVFCid8 : 13|1@0+ (1,0) [0|1] "" Vector__XXX
 SG_ VFCVectorZCUDMVFCid9 : 12|1@0+ (1,0) [0|1] "" Vector__XXX

BO_ 535 ZCUTZCUDCANFD3Fr01: 64 ZCUT
 SG_ CDCModlndcnForFAS : 7|3@0+ (1,0) [0|7] "" ZCUD
 SG_ CDCModlndcnForFAS_UB : 4|1@0+ (1,0) [0|1] "" ZCUD
 SG_ FASActFAry_UB : 42|1@0+ (1,0) [0|1] "" XCM
 SG_ FASActFAryFL : 71|16@0- (1,0) [-32768|32767] "N" XCM
 SG_ FASActFAryFR : 87|16@0- (1,0) [-32768|32767] "N" XCM
 SG_ FASActFAryRL : 103|16@0- (1,0) [-32768|32767] "N" XCM
 SG_ FASActFAryRR : 119|16@0- (1,0) [-32768|32767] "N" XCM
 SG_ FASChassisObstclCrsModIncn : 3|2@0+ (1,0) [0|3] "" ZCUD
 SG_ FASChassisObstclCrsModIncn_UB : 1|1@0+ (1,0) [0|1] "" ZCUD
 SG_ FASDrvModPrsnlAdjmt_UB : 141|1@0+ (1,0) [0|1] "" ZCUD
 SG_ FASDrvModPrsnlAdjmtDamprCmftSts : 135|1@0+ (1,0) [0|1] "" ZCUD
 SG_ FASDrvModPrsnlAdjmtDamprHardSts : 134|1@0+ (1,0) [0|1] "" ZCUD
 SG_ FASDrvModPrsnlAdjmtDamprMedSts : 133|1@0+ (1,0) [0|1] "" ZCUD
 SG_ FASDrvModPrsnlAdjmtDamprSts_Resv1 : 132|1@0+ (1,0) [0|1] "" ZCUD
 SG_ FASDrvModPrsnlAdjmtDamprSts_Resv2 : 131|1@0+ (1,0) [0|1] "" ZCUD
 SG_ FASDrvModPrsnlAdjmtSuspLvlHL1Sts : 130|1@0+ (1,0) [0|1] "" ZCUD
 SG_ FASDrvModPrsnlAdjmtSuspLvlHL2Sts : 129|1@0+ (1,0) [0|1] "" ZCUD
 SG_ FASDrvModPrsnlAdjmtSuspLvlLL1Sts : 128|1@0+ (1,0) [0|1] "" ZCUD
 SG_ FASDrvModPrsnlAdjmtSuspLvlLL2Sts : 143|1@0+ (1,0) [0|1] "" ZCUD
 SG_ FASDrvModPrsnlAdjmtSuspLvlNRHSts : 142|1@0+ (1,0) [0|1] "" ZCUD
 SG_ FASEasyLoadModlndcn : 15|3@0+ (1,0) [0|7] "" ZCUD
 SG_ FASEasyLoadModlndcn_UB : 12|1@0+ (1,0) [0|1] "" ZCUD
 SG_ FASHeiLimModIncn : 11|2@0+ (1,0) [0|3] "" ZCUD
 SG_ FASHeiLimModIncn_UB : 9|1@0+ (1,0) [0|1] "" ZCUD
 SG_ FASLvlgDirMovmtindcr : 23|2@0+ (1,0) [0|3] "" ZCUD
 SG_ FASLvlgDirMovmtindcr_UB : 21|1@0+ (1,0) [0|1] "" ZCUD
 SG_ FASLvlgFctAvl : 17|1@0+ (1,0) [0|1] "" ZCUD
 SG_ FASLvlgFctAvl_UB : 16|1@0+ (1,0) [0|1] "" ZCUD
 SG_ FASLvlgFctSts : 20|2@0+ (1,0) [0|3] "" ZCUD
 SG_ FASLvlgFctSts_UB : 18|1@0+ (1,0) [0|1] "" ZCUD
 SG_ FullActvSuspFailrSts_UB : 46|1@0+ (1,0) [0|1] "" ZCUD
 SG_ FullActvSuspFailrStsSuspFailrSts : 35|3@0+ (1,0) [0|7] "" ZCUD
 SG_ FullActvSuspFailrStsSuspFailrStsChks : 31|8@0+ (1,0) [0|255] "Unitless" ZCUD
 SG_ FullActvSuspFailrStsSuspFailrStsCntr : 39|4@0+ (1,0) [0|15] "Unitless" ZCUD
 SG_ FullActvSuspFailrStsSuspFailrStsTypQf : 32|2@0+ (1,0) [0|3] "" ZCUD
 SG_ FullActvSuspHeilvlindcn : 45|3@0+ (1,0) [0|7] "" ZCUD
 SG_ FullActvSuspHeilvlindcn_UB : 8|1@0+ (1,0) [0|1] "" ZCUD
 SG_ FullActvSuspStabyCritFailrDetd_UB : 0|1@0+ (1,0) [0|1] "" ZCUD
 SG_ FullActvSuspStabyCritFailrDetdChks : 55|8@0+ (1,0) [0|255] "Unitless" ZCUD
 SG_ FullActvSuspStabyCritFailrDetdCntr : 63|4@0+ (1,0) [0|15] "Unitless" ZCUD
 SG_ FullActvSuspStabyCritFailrDetdSts : 59|1@0+ (1,0) [0|1] "" ZCUD

BO_ 101 ZCUTZCUDCANFD3Fr02: 64 ZCUT
 SG_ FASBodyHei : 7|15@0- (6.2E-5,0) [-0.999998|1.00006] "m" ZCUD
 SG_ FASBodyHei_UB : 8|1@0+ (1,0) [0|1] "" ZCUD
 SG_ FullActvSuspPosnVertLe_UB : 96|1@0+ (1,0) [0|1] "" ZCUD
 SG_ FullActvSuspPosnVertLeChks : 71|8@0+ (1,0) [0|255] "Unitless" ZCUD
 SG_ FullActvSuspPosnVertLeFrnt : 79|15@0- (6.2E-5,0) [-0.999998|1.00006] "m" ZCUD
 SG_ FullActvSuspPosnVertLeFrntQf : 59|2@0+ (1,0) [0|3] "" ZCUD
 SG_ FullActvSuspPosnVertLeRe : 95|15@0- (6.2E-5,0) [-0.999998|1.00006] "m" ZCUD
 SG_ FullActvSuspPosnVertLeReQf : 57|2@0+ (1,0) [0|3] "" ZCUD
 SG_ FullActvSuspPosnVertRi_UB : 23|1@0+ (1,0) [0|1] "" ZCUD
 SG_ FullActvSuspPosnVertRiChks : 39|8@0+ (1,0) [0|255] "Unitless" ZCUD
 SG_ FullActvSuspPosnVertRiFrnt : 22|15@0- (6.2E-5,0) [-0.999998|1.00006] "m" ZCUD
 SG_ FullActvSuspPosnVertRiFrntQf : 63|2@0+ (1,0) [0|3] "" ZCUD
 SG_ FullActvSuspPosnVertRiRe : 47|15@0- (6.2E-5,0) [-0.999998|1.00006] "m" ZCUD
 SG_ FullActvSuspPosnVertRiReQf : 61|2@0+ (1,0) [0|3] "" ZCUD
 SG_ ZCUTForceMaxFrntLe : 111|16@0- (1,0) [-20000|20000] "N" ZCUD
 SG_ ZCUTForceMaxFrntLe_UB : 232|1@0+ (1,0) [0|1] "" ZCUD
 SG_ ZCUTForceMaxFrntRi : 127|16@0- (1,0) [-20000|20000] "N" ZCUD
 SG_ ZCUTForceMaxFrntRi_UB : 233|1@0+ (1,0) [0|1] "" ZCUD
 SG_ ZCUTForceMaxReLe : 143|16@0- (1,0) [-20000|20000] "N" ZCUD
 SG_ ZCUTForceMaxReLe_UB : 234|1@0+ (1,0) [0|1] "" ZCUD
 SG_ ZCUTForceMaxReRi : 159|16@0- (1,0) [-20000|20000] "N" ZCUD
 SG_ ZCUTForceMaxReRi_UB : 235|1@0+ (1,0) [0|1] "" ZCUD
 SG_ ZCUTForceRealFrntLe : 175|16@0- (1,0) [-20000|20000] "N" ZCUD
 SG_ ZCUTForceRealFrntLe_UB : 236|1@0+ (1,0) [0|1] "" ZCUD
 SG_ ZCUTForceRealFrntRi : 191|16@0- (1,0) [-20000|20000] "N" ZCUD
 SG_ ZCUTForceRealFrntRi_UB : 237|1@0+ (1,0) [0|1] "" ZCUD
 SG_ ZCUTForceRealReLe : 207|16@0- (1,0) [-20000|20000] "N" ZCUD
 SG_ ZCUTForceRealReLe_UB : 238|1@0+ (1,0) [0|1] "" ZCUD
 SG_ ZCUTForceRealReRi : 223|16@0- (1,0) [-20000|20000] "N" ZCUD
 SG_ ZCUTForceRealReRi_UB : 241|1@0+ (1,0) [0|1] "" ZCUD
 SG_ ZCUTToVMCAvl : 239|1@0+ (1,0) [0|1] "" ZCUD
 SG_ ZCUTToVMCAvl_UB : 240|1@0+ (1,0) [0|1] "" ZCUD

BO_ 266 ZCUTZCUDCANFD3Fr03: 64 ZCUT
 SG_ FasCritPwrReq : 7|1@0+ (1,0) [0|1] "" XCM
 SG_ FasCritPwrReq_UB : 6|1@0+ (1,0) [0|1] "" XCM
 SG_ FasPwrAct : 141|9@0+ (100,0) [0|51100] "W" XCM
 SG_ FasPwrAct_UB : 148|1@0+ (1,0) [0|1] "" XCM
 SG_ FasPwrReq : 147|9@0+ (100,0) [0|51100] "W" XCM
 SG_ FasPwrReq_UB : 154|1@0+ (1,0) [0|1] "" XCM

BO_ 1282 ZCUTZCUDCANFD3NmFr01: 8 ZCUT
 SG_ NM_AW_ZCUT : 12|1@0+ (1,0) [0|0] "" ZCUD
 SG_ NM_CS_ZCUT : 11|1@0+ (1,0) [0|0] "" ZCUD
 SG_ NM_NodeID_ZCUT : 7|8@0+ (1,0) [0|0] "" ZCUD
 SG_ NM_PNI_ZCUT : 14|1@0+ (1,0) [0|0] "" ZCUD
 SG_ NM_RMR_ZCUT : 8|1@0+ (1,0) [0|0] "" ZCUD
 SG_ PNC23_ZCUT : 23|1@0+ (1,0) [0|0] "" ZCUD
 SG_ PNC25_ZCUT : 25|1@0+ (1,0) [0|0] "" ZCUD
 SG_ PNC29_ZCUT : 29|1@0+ (1,0) [0|0] "" ZCUD
 SG_ PNC36_ZCUT : 36|1@0+ (1,0) [0|0] "" ZCUD
 SG_ PNC38_ZCUT : 38|1@0+ (1,0) [0|0] "" ZCUD
 SG_ WakeUpReasonsforZCUT : 55|16@0+ (1,0) [0|65535] "" Vector__XXX

BO_ 1346 ZcutZCUDCANFD3VFCVectorFr: 8 ZCUT
 SG_ VFCVectorZCUTBlockID : 7|2@0+ (1,0) [0|3] "Unitless" Vector__XXX
 SG_ VFCVectorZCUTVFCid0 : 5|1@0+ (1,0) [0|1] "" Vector__XXX
 SG_ VFCVectorZCUTVFCid1 : 4|1@0+ (1,0) [0|1] "" Vector__XXX
 SG_ VFCVectorZCUTVFCid10 : 11|1@0+ (1,0) [0|1] "" Vector__XXX
 SG_ VFCVectorZCUTVFCid11 : 10|1@0+ (1,0) [0|1] "" Vector__XXX
 SG_ VFCVectorZCUTVFCid12 : 9|1@0+ (1,0) [0|1] "" Vector__XXX
 SG_ VFCVectorZCUTVFCid13 : 8|1@0+ (1,0) [0|1] "" Vector__XXX
 SG_ VFCVectorZCUTVFCid14 : 23|1@0+ (1,0) [0|1] "" Vector__XXX
 SG_ VFCVectorZCUTVFCid15 : 22|1@0+ (1,0) [0|1] "" Vector__XXX
 SG_ VFCVectorZCUTVFCid16 : 21|1@0+ (1,0) [0|1] "" Vector__XXX
 SG_ VFCVectorZCUTVFCid17 : 20|1@0+ (1,0) [0|1] "" Vector__XXX
 SG_ VFCVectorZCUTVFCid18 : 19|1@0+ (1,0) [0|1] "" Vector__XXX
 SG_ VFCVectorZCUTVFCid19 : 18|1@0+ (1,0) [0|1] "" Vector__XXX
 SG_ VFCVectorZCUTVFCid2 : 3|1@0+ (1,0) [0|1] "" Vector__XXX
 SG_ VFCVectorZCUTVFCid20 : 17|1@0+ (1,0) [0|1] "" Vector__XXX
 SG_ VFCVectorZCUTVFCid21 : 16|1@0+ (1,0) [0|1] "" Vector__XXX
 SG_ VFCVectorZCUTVFCid22 : 31|1@0+ (1,0) [0|1] "" Vector__XXX
 SG_ VFCVectorZCUTVFCid23 : 30|1@0+ (1,0) [0|1] "" Vector__XXX
 SG_ VFCVectorZCUTVFCid24 : 29|1@0+ (1,0) [0|1] "" Vector__XXX
 SG_ VFCVectorZCUTVFCid25 : 28|1@0+ (1,0) [0|1] "" Vector__XXX
 SG_ VFCVectorZCUTVFCid26 : 27|1@0+ (1,0) [0|1] "" Vector__XXX
 SG_ VFCVectorZCUTVFCid27 : 26|1@0+ (1,0) [0|1] "" Vector__XXX
 SG_ VFCVectorZCUTVFCid28 : 25|1@0+ (1,0) [0|1] "" Vector__XXX
 SG_ VFCVectorZCUTVFCid29 : 24|1@0+ (1,0) [0|1] "" Vector__XXX
 SG_ VFCVectorZCUTVFCid3 : 2|1@0+ (1,0) [0|1] "" Vector__XXX
 SG_ VFCVectorZCUTVFCid30 : 39|1@0+ (1,0) [0|1] "" Vector__XXX
 SG_ VFCVectorZCUTVFCid31 : 38|1@0+ (1,0) [0|1] "" Vector__XXX
 SG_ VFCVectorZCUTVFCid32 : 37|1@0+ (1,0) [0|1] "" Vector__XXX
 SG_ VFCVectorZCUTVFCid33 : 36|1@0+ (1,0) [0|1] "" Vector__XXX
 SG_ VFCVectorZCUTVFCid34 : 35|1@0+ (1,0) [0|1] "" Vector__XXX
 SG_ VFCVectorZCUTVFCid35 : 34|1@0+ (1,0) [0|1] "" Vector__XXX
 SG_ VFCVectorZCUTVFCid36 : 33|1@0+ (1,0) [0|1] "" Vector__XXX
 SG_ VFCVectorZCUTVFCid37 : 32|1@0+ (1,0) [0|1] "" Vector__XXX
 SG_ VFCVectorZCUTVFCid38 : 47|1@0+ (1,0) [0|1] "" Vector__XXX
 SG_ VFCVectorZCUTVFCid39 : 46|1@0+ (1,0) [0|1] "" Vector__XXX
 SG_ VFCVectorZCUTVFCid4 : 1|1@0+ (1,0) [0|1] "" Vector__XXX
 SG_ VFCVectorZCUTVFCid40 : 45|1@0+ (1,0) [0|1] "" Vector__XXX
 SG_ VFCVectorZCUTVFCid41 : 44|1@0+ (1,0) [0|1] "" Vector__XXX
 SG_ VFCVectorZCUTVFCid42 : 43|1@0+ (1,0) [0|1] "" Vector__XXX
 SG_ VFCVectorZCUTVFCid43 : 42|1@0+ (1,0) [0|1] "" Vector__XXX
 SG_ VFCVectorZCUTVFCid44 : 41|1@0+ (1,0) [0|1] "" Vector__XXX
 SG_ VFCVectorZCUTVFCid45 : 40|1@0+ (1,0) [0|1] "" Vector__XXX
 SG_ VFCVectorZCUTVFCid46 : 55|1@0+ (1,0) [0|1] "" Vector__XXX
 SG_ VFCVectorZCUTVFCid47 : 54|1@0+ (1,0) [0|1] "" Vector__XXX
 SG_ VFCVectorZCUTVFCid48 : 53|1@0+ (1,0) [0|1] "" Vector__XXX
 SG_ VFCVectorZCUTVFCid49 : 52|1@0+ (1,0) [0|1] "" Vector__XXX
 SG_ VFCVectorZCUTVFCid5 : 0|1@0+ (1,0) [0|1] "" Vector__XXX
 SG_ VFCVectorZCUTVFCid50 : 51|1@0+ (1,0) [0|1] "" Vector__XXX
 SG_ VFCVectorZCUTVFCid51 : 50|1@0+ (1,0) [0|1] "" Vector__XXX
 SG_ VFCVectorZCUTVFCid52 : 49|1@0+ (1,0) [0|1] "" Vector__XXX
 SG_ VFCVectorZCUTVFCid53 : 48|1@0+ (1,0) [0|1] "" Vector__XXX
 SG_ VFCVectorZCUTVFCid54 : 63|1@0+ (1,0) [0|1] "" Vector__XXX
 SG_ VFCVectorZCUTVFCid55 : 62|1@0+ (1,0) [0|1] "" Vector__XXX
 SG_ VFCVectorZCUTVFCid56 : 61|1@0+ (1,0) [0|1] "" Vector__XXX
 SG_ VFCVectorZCUTVFCid57 : 60|1@0+ (1,0) [0|1] "" Vector__XXX
 SG_ VFCVectorZCUTVFCid58 : 59|1@0+ (1,0) [0|1] "" Vector__XXX
 SG_ VFCVectorZCUTVFCid59 : 58|1@0+ (1,0) [0|1] "" Vector__XXX
 SG_ VFCVectorZCUTVFCid6 : 15|1@0+ (1,0) [0|1] "" Vector__XXX
 SG_ VFCVectorZCUTVFCid60 : 57|1@0+ (1,0) [0|1] "" Vector__XXX
 SG_ VFCVectorZCUTVFCid61 : 56|1@0+ (1,0) [0|1] "" Vector__XXX
 SG_ VFCVectorZCUTVFCid7 : 14|1@0+ (1,0) [0|1] "" Vector__XXX
 SG_ VFCVectorZCUTVFCid8 : 13|1@0+ (1,0) [0|1] "" Vector__XXX
 SG_ VFCVectorZCUTVFCid9 : 12|1@0+ (1,0) [0|1] "" Vector__XXX

CM_ SG_ 85 EscStChks "Information on activation/ deactivation of Electronic Stability Control (ESC) Checksum for Esc state";
CM_ SG_ 85 EscStCntr "Information on activation/ deactivation of Electronic Stability Control (ESC) Counter for Esc state";
CM_ SG_ 85 EscStEscSt "Information on activation/ deactivation of Electronic Stability Control (ESC) Esc state information for Esc ON, Esc OFF or Esc Sport";
CM_ SG_ 85 GearLvrIndcn "Gear lever indication (drivetrain position) to the driver. If drivetrain position is not possible to decide signal is set to undefined. Valid for automatic vehicles.
";
CM_ SG_ 85 GVMCPrpsnTqDistReqChks "GVMC front and rear axle propulsion torque distribution request chks";
CM_ SG_ 85 GVMCPrpsnTqDistReqCntr "GVMC front and rear axle propulsion torque distribution request cntr";
CM_ SG_ 85 GVMCPrpsnTqDistReqCtrlMod "Front and rear torque distribution control mode";
CM_ SG_ 85 GVMCPrpsnTqDistReqDistReq "GVMC front and rear axle propulsion torque distribution request";
CM_ SG_ 85 GVMCSteerWhlAgReqFrntChks "check sum";
CM_ SG_ 85 GVMCSteerWhlAgReqFrntCntr "rolling conunter";
CM_ SG_ 85 GVMCSteerWhlAgReqFrntSteerWhlAgCtrl "steer angle control";
CM_ SG_ 85 GVMCSteerWhlAgReqFrntSteerWhlCtrlSts "steer control status";
CM_ SG_ 85 GVMCSteerWhlAgReqFrntSteerWhlTqCtrl "steer torque control";
CM_ SG_ 85 GVMCVehCtrlrStsChks "GVMC vehicle controler Status Chks";
CM_ SG_ 85 GVMCVehCtrlrStsCntr "GVMC vehicle controler Status Cntr";
CM_ SG_ 85 GVMCVehCtrlrStsCtrlrSts "GVMC vehicle control status";
CM_ SG_ 85 GVMCVehVActLatAct "GVMC vehicle lateral vilocity act";
CM_ SG_ 85 GVMCVehVActLgtAct "GVMC vehicle longitudinal vilocity act";
CM_ SG_ 85 GVMCVehVActQf "GVMC vehicle vilocity act QF";
CM_ SG_ 85 GVMCVehYawRateTar "vehicle yawrate target";
CM_ SG_ 85 GVMCYawRateCOGActAct "GVMC vehicle  yawrate COG act";
CM_ SG_ 85 GVMCYawRateCOGActQf "GVMC vehicle  yawrate COG act QF";
CM_ SG_ 85 LatCtrlReqSafeChks "Lateral Control Mode Request Chks";
CM_ SG_ 85 LatCtrlReqSafeCntr "Lateral Control Mode Request Cntr";
CM_ SG_ 85 LatCtrlReqSafeLatCtrlModReq "Lateral Control Mode Request";
CM_ SG_ 85 LatCtrlReqSafeSteerTqReq "Steering Torque Request";
CM_ SG_ 85 LatCtrlReqSafeSteerWhlHptcWarnReq "Steering Wheel Haptic Warning Request";
CM_ SG_ 85 SteerWhlSnsrAg "Actual steering wheel angle from the actual centre position of the steering wheel. ";
CM_ SG_ 85 SteerWhlSnsrAgSpd "Actual steering wheel angle from the actual centre position of the steering wheel. Steering angle speed with steering wheel rotation direction.  ";
CM_ SG_ 85 SteerWhlSnsrChks "Checksum for steering wheel sensor data.";
CM_ SG_ 85 SteerWhlSnsrCntr "Counter value for steering wheel sensor data.";
CM_ SG_ 85 SteerWhlSnsrQf "Qf for steering wheel sensor information";
CM_ SG_ 85 VehModMngtGlbSafe1CarModSts1 "CarMode Status";
CM_ SG_ 85 VehModMngtGlbSafe1CarModSubtypWdCarModSubtyp "CarMode substate status";
CM_ SG_ 85 VehModMngtGlbSafe1Chks "Checksum";
CM_ SG_ 85 VehModMngtGlbSafe1Cntr "Counter";
CM_ SG_ 85 VehModMngtGlbSafe1EgyLvlElecMai "Main energy level in the vehicle.";
CM_ SG_ 85 VehModMngtGlbSafe1EgyLvlElecSubtyp "Substate of the energy level in the vehicle.";
CM_ SG_ 85 VehModMngtGlbSafe1FltEgyCnsWdSts "High quiescent current detected by CEM via BMS.";
CM_ SG_ 85 VehModMngtGlbSafe1PwrLvlElecMai "Main Power level in the vehicle.";
CM_ SG_ 85 VehModMngtGlbSafe1PwrLvlElecSubtyp "Substate of the power level in the vehicle.";
CM_ SG_ 85 VehModMngtGlbSafe1UsgModSts "UsageMode Status";
CM_ SG_ 85 VehMtnStChks "Vehicle motion state information based on wheel speed sensors. Provides information about vehicle stand still and vehicle rolling direction. Checksum for vehicle motion state";
CM_ SG_ 85 VehMtnStCntr "Vehicle motion state information based on wheel speed sensors. Provides information about vehicle stand still and vehicle rolling direction. Counter for vehicle motion state";
CM_ SG_ 85 VehMtnStVehMtnSt "Vehicle motion state information based on wheel speed sensors. Provides information about vehicle stand still and vehicle rolling direction. Vehicle motion state";
CM_ SG_ 85 VehSpdLgtA "Vehicle speed longitudinal based on wheel speed sensors and longitudinal acceleration.";
CM_ SG_ 85 VehSpdLgtChks "Checksum";
CM_ SG_ 85 VehSpdLgtCntr "Counter";
CM_ SG_ 85 VehSpdLgtQf "Quality factor for vehicle speed as measured by wheel speed sensors and longitudinal acceleration.";
CM_ SG_ 85 WhlFastSpdSafeA "Vehicle speed longitudinal based on wheel speed sensors and longitudinal acceleration.";
CM_ SG_ 85 WhlFastSpdSafeChks "checksum";
CM_ SG_ 85 WhlFastSpdSafeCntr "counter";
CM_ SG_ 85 WhlFastSpdSafeQF "Quality factor for vehicle speed as measured by wheel speed sensors and longitudinal acceleration.";
CM_ SG_ 85 WhlRotToothCntrChks "check sum";
CM_ SG_ 85 WhlRotToothCntrCntr "counter";
CM_ SG_ 85 WhlRotToothCntrFrntLe "Wheel rotation ticks for each individual wheel. Wheel rotation impuls counter front left. For one complete wheel revolution the counter will increase by 96 (with 48 magnetic pole-pairs).";
CM_ SG_ 85 WhlRotToothCntrFrntRi "Wheel rotation ticks for each individual wheel. Wheel rotation impuls counter front right. For one complete wheel revolution the counter will increase by 96 (with 48 magnetic pole-pairs).";
CM_ SG_ 85 WhlRotToothCntrReLe "Wheel rotation ticks for each individual wheel. Wheel rotation impuls counter rear left. For one complete wheel revolution the counter will increase by 96 (with 48 magnetic pole-pairs).";
CM_ SG_ 85 WhlRotToothCntrReRi "Wheel rotation ticks for each individual wheel. Wheel rotation impuls counter rear right. For one complete wheel revolution the counter will increase by 96 (with 48 magnetic pole-pairs).";
CM_ SG_ 85 YawRateReqdByDrvr "When the vehicle is making a left turn this signal is supposed to show positive numbers. Unfiltered and offset compensated plausibility check";
CM_ SG_ 339 DrvrGearShiftDirReq1Chks "8 bit checksum";
CM_ SG_ 339 DrvrGearShiftDirReq1Cntr "4 bit counter used in checksum calculation. N=E (modulo 16)";
CM_ SG_ 339 DrvrGearShiftDirReq1DwnDwnTipAut "Gear shifter downdown tip in automatic gate";
CM_ SG_ 339 DrvrGearShiftDirReq1DwnTipAut "Gear shifter down tip in automatic gate";
CM_ SG_ 339 DrvrGearShiftDirReq1PosnAut "Gear shifter in automatic gate position";
CM_ SG_ 339 DrvrGearShiftDirReq1UpTipAut "Gear shifter up tip in automatic gate";
CM_ SG_ 339 DrvrGearShiftDirReq1UpUpTipAut "Gear shifter upup tip in automatic gate";
CM_ SG_ 339 DrvrGearShiftDirReq2Chks "8 bit checksum";
CM_ SG_ 339 DrvrGearShiftDirReq2Cntr "4 bit counter used in checksum calculation. N=E (modulo 16)";
CM_ SG_ 339 DrvrGearShiftDirReq2DwnDwnTipAut "Gear shifter downdown tip in automatic gate";
CM_ SG_ 339 DrvrGearShiftDirReq2DwnTipAut "Gear shifter down tip in automatic gate";
CM_ SG_ 339 DrvrGearShiftDirReq2PosnAut "Gear shifter in automatic gate position";
CM_ SG_ 339 DrvrGearShiftDirReq2UpTipAut "Gear shifter up tip in automatic gate";
CM_ SG_ 339 DrvrGearShiftDirReq2UpUpTipAut "Gear shifter upup tip in automatic gate";
CM_ SG_ 339 RWASteerLockReqCommand "Command to lock or unlock RWA";
CM_ SG_ 339 RWASteerLockReqSteerLockDataReq0 "7 bytes response ";
CM_ SG_ 339 RWASteerLockReqSteerLockDataReq1 "7 bytes response ";
CM_ SG_ 339 RWASteerLockReqSteerLockDataReq2 "7 bytes response ";
CM_ SG_ 339 RWASteerLockReqSteerLockDataReq3 "7 bytes response ";
CM_ SG_ 339 RWASteerLockReqSteerLockDataReq4 "7 bytes response ";
CM_ SG_ 339 RWASteerLockReqSteerLockDataReq5 "7 bytes response ";
CM_ SG_ 339 RWASteerLockReqSteerLockDataReq6 "7 bytes response ";
CM_ SG_ 339 SteerEmergCtrlSwt "Emergency Steering Column Replacement Switch";
CM_ SG_ 339 SteerRatModReq "change settings for Steering ratio";
CM_ SG_ 339 SteerSetgPen "IdPen";
CM_ SG_ 339 SteerSetgSteerAsscLvl "Steer Assistance Level";
CM_ SG_ 339 SteerSetgSteerMod "Steer Mode";
CM_ SG_ 339 SuspCmprSpd "Compressor speed";
CM_ SG_ 339 SuspDistbnVlvCtrlStsChks "checksum";
CM_ SG_ 339 SuspDistbnVlvCtrlStsCntr "conter";
CM_ SG_ 339 SuspDistbnVlvCtrlStsSuspDistbnVlvCtrlSts "valve status";
CM_ SG_ 339 SuspStfnVlvCtrlStsFL "suspension stiffness";
CM_ SG_ 339 SuspStfnVlvCtrlStsFR "suspension stiffness";
CM_ SG_ 339 SuspStfnVlvCtrlStsRL "suspension stiffness";
CM_ SG_ 339 SuspStfnVlvCtrlStsRR "suspension stiffness";
CM_ SG_ 339 ZCAirSuspCtrlStsChks "checksum";
CM_ SG_ 339 ZCAirSuspCtrlStsCntr "conter";
CM_ SG_ 339 ZCAirSuspCtrlStsZCAirSuspCtrlSts "control status";
CM_ SG_ 289 BBWPullOverReq "BBW Pull Over Request";
CM_ SG_ 289 BrkPedlPsdBrkPedlNotPsdSafe "Set to 1 if brake pedal is not pressed, otherwise 0";
CM_ SG_ 289 BrkPedlPsdBrkPedlPsd "Set to 1 if brake pedal is pressed, otherwise 0";
CM_ SG_ 289 BrkPedlPsdChks "Checksum";
CM_ SG_ 289 BrkPedlPsdCntr "Counter";
CM_ SG_ 289 BrkPedlPsdQf "Quality factor";
CM_ SG_ 289 ChassisObstclCrsModIncn "chassis obstacle crossing function mode indication";
CM_ SG_ 289 HeiLimModIncn "height limit active adjust function mode indication";
CM_ SG_ 289 PTALgtLimnlnd "The acceleration of power torque conversion";
CM_ SG_ 1173 BkpOfDstTrvld "total traveled distance.";
CM_ SG_ 1173 CarTiGlb "Presents a tiime value that shall be used by all ECUs to time-stamp diagnsotic trouble codes (DTC) according to the requirements for Global DTC snapshot data.";
CM_ SG_ 1173 TiAndDateIndcnDataValid "Current time (Hr, Min and Sec) and date (Year, Months and days) data for indication. See requirement for more information about the signals. Signal qualifier, No means values should be ignored.";
CM_ SG_ 1173 TiAndDateIndcnDay "Current time (Hr, Min and Sec) and date (Year, Months and days) data for indication. See requirement for more information about the signals. Day";
CM_ SG_ 1173 TiAndDateIndcnHr1 "Current time (Hr, Min and Sec) and date (Year, Months and days) data for indication. See requirement for more information about the signals. Hour";
CM_ SG_ 1173 TiAndDateIndcnMins1 "Current time (Hr, Min and Sec) and date (Year, Months and days) data for indication. See requirement for more information about the signals. Minutes";
CM_ SG_ 1173 TiAndDateIndcnMth1 "Current time (Hr, Min and Sec) and date (Year, Months and days) data for indication. See requirement for more information about the signals. Month, 1-12";
CM_ SG_ 1173 TiAndDateIndcnSec1 "Current time (Hr, Min and Sec) and date (Year, Months and days) data for indication. See requirement for more information about the signals. Seconds";
CM_ SG_ 1173 TiAndDateIndcnYr1 "Current time (Hr, Min and Sec) and date (Year, Months and days) data for indication. See requirement for more information about the signals. Year, 0-99";
CM_ SG_ 1173 VehBattUSysU "Vehicle System Voltage At 12V side";
CM_ SG_ 1173 VehBattUSysUQf "Present vehicle voltage measured by CEM with QF";
CM_ SG_ 569 BattIRaw "Battery Current From BMS";
CM_ SG_ 569 BattRemainTimeToEmpty "Battery remaining discharge time";
CM_ SG_ 569 DrvModReq "Drive mode";
CM_ SG_ 569 DrvrSeatSnsrSts "Informs if there is a fault on the driver seat sensor is detected through electrical measurements, or plausibility judgement. NotOk means sensor is judged as faulty. Di means that the sensor is not configured.";
CM_ SG_ 569 DrvrSeatSts "Describes if an occupant is detected in the driver seat.";
CM_ SG_ 569 IAMSMod "Intelligen tAnti Motion Sickness Mode";
CM_ SG_ 569 LockgCenStsLockSt "Signal LockgCenSts provides central locking status to other subsystems.
Signal is a record with three items
- LockSt (Lock State)
- TrigSrc (Trig Source)
- UpdEve (Will be set to TRUE during one second at each new central locking or unlocking event)";
CM_ SG_ 569 LockgCenStsTrigSrc "Signal LockgCenSts provides central locking status to other subsystems.
Signal is a record with three items
- LockSt (Lock State)
- TrigSrc (Trig Source)
- UpdEve (Will be set to TRUE during one second at each new central locking or unlocking event)";
CM_ SG_ 569 LockgCenStsUpdEve "Signal LockgCenSts provides central locking status to other subsystems.
Signal is a record with three items
- LockSt (Lock State)
- TrigSrc (Trig Source)
- UpdEve (Will be set to TRUE during one second at each new central locking or unlocking event)";
CM_ SG_ 569 PtTqAtWhlFrntActChks "checksum";
CM_ SG_ 569 PtTqAtWhlFrntActCntr "counter";
CM_ SG_ 569 PtTqAtWhlFrntActPtTqAtAxleFrntAct "Actual torque delivered by the powertrain to the front axle";
CM_ SG_ 569 PtTqAtWhlFrntActPtTqAtWhlFrntLeAct "Actual torque delivered by the powertrain to the front left wheel.";
CM_ SG_ 569 PtTqAtWhlFrntActPtTqAtWhlFrntRiAct "Actual torque delivered by the powertrain to the front right wheel.";
CM_ SG_ 569 PtTqAtWhlFrntActPtTqAtWhlsFrntQly "quality factor";
CM_ SG_ 569 PVMCSteerAst "PVMC Steering assist";
CM_ SG_ 625 AmbTRawAmbTVal "Unfiltered ambient temp raw data in deg C. Ambient temp value";
CM_ SG_ 625 AmbTRawQly "Unfiltered ambient temp raw data in deg C. Quality Factor of the ambient temp";
CM_ SG_ 625 DstEstimdToEmptyForDrvgElec "DstEstimdToEmptyForDrvgElec";
CM_ SG_ 625 DstEstimdToEmptyForDrvgElecPredTyp2 "DstEstimdToEmptyForDrvgElecPredTyp2";
CM_ SG_ 625 DstEstimdToEmptyForDynElec "DstEstimdToEmptyForDrvgElecWLTC";
CM_ SG_ 625 DstToEmptyIndcdDstToEmpty1 "Indicated distance to Empty (D.T.E.) with indicated unit Distance To Empty";
CM_ SG_ 625 DstToEmptyIndcdDstToEmpty2 "Indicated standard distance to Empty.(SDTE)

This value is equal to the amount of fuel left in the tank divided by the declared fuel consumption";
CM_ SG_ 625 DstToEmptyIndcdDstToEmpty3 "Indicated dynamic distance to Empty.";
CM_ SG_ 131 DPAAgReqGroup1Chks "CRC";
CM_ SG_ 131 DPAAgReqGroup1Cntr "conuter";
CM_ SG_ 131 DPAAgReqGroup1RtonAgReq "DPA Rotation Angle request";
CM_ SG_ 131 DPAAgReqGroup1TrgtAg "DPA Target Angle";
CM_ SG_ 131 DPAAgReqGroup1VehAtaRtonlAg "Actual rotation Angle of the vehicle";
CM_ SG_ 131 DPAAgReqGroupChks "CRC,to check the signal,For E2E Protection";
CM_ SG_ 131 DPAAgReqGroupCntr "counter,For E2E Protection";
CM_ SG_ 131 DPAAgReqGroupRtonAgReq "DPA Rotation Angle request";
CM_ SG_ 131 DPAAgReqGroupTrgtAg "DPA Target Angle";
CM_ SG_ 131 DPAAgReqGroupVehAtaRtonlAg "Actual rotation Angle of the vehicle";
CM_ SG_ 102 AbsCtrlActvChks "checksum";
CM_ SG_ 102 AbsCtrlActvCntr "counter";
CM_ SG_ 102 AbsCtrlActvCtrlSts1 "Anti Blocking Systems (ABS) control is active (at least one wheel)
0 = No wheel is in Anti Blocking Systems (ABS) control
1 = At least one wheel is in Anti Blocking Systems (ABS) control";
CM_ SG_ 102 BrkTracCtrlActv "Indicates InCtrl if brake traction control (TC) is active on at least one wheel.";
CM_ SG_ 102 GVMCPrpsnTqDistbnReqAtAxleReChks "checksum";
CM_ SG_ 102 GVMCPrpsnTqDistbnReqAtAxleReCntr "counter";
CM_ SG_ 102 GVMCPrpsnTqDistbnReqAtAxleReCtrlMod "control mode";
CM_ SG_ 102 GVMCPrpsnTqDistbnReqAtAxleReDistReq "distribution request";
CM_ SG_ 102 GVMCSuspDampgCtrlReqGVMCDampgCtrlReqFL "GVMC Suspension damping control request front left";
CM_ SG_ 102 GVMCSuspDampgCtrlReqGVMCDampgCtrlReqFR "GVMC Suspension damping control request front right";
CM_ SG_ 102 GVMCSuspDampgCtrlReqGVMCDampgCtrlReqRL "GVMC Suspension damping control request rear left";
CM_ SG_ 102 GVMCSuspDampgCtrlReqGVMCDampgCtrlReqRR "GVMC Suspension damping control request rear right";
CM_ SG_ 102 GVMCSuspDampgCtrlReqGVMCSuspDampgCtrlMod "GVMC suspension damping control mode";
CM_ SG_ 102 GVMCSuspDampgCtrlReqGVMCSuspDampgModReq "GVMC suspension damping mode request";
CM_ SG_ 102 PVMCSuspHeiCtrlReqGVMCSuspPosnCtrlMod "GVMC suspension height control mode";
CM_ SG_ 102 PVMCSuspHeiCtrlReqGVMCSuspPosnFLReq "GVMC supension height request FL";
CM_ SG_ 102 PVMCSuspHeiCtrlReqGVMCSuspPosnFRReq "GVMC supension height request FR";
CM_ SG_ 102 PVMCSuspHeiCtrlReqGVMCSuspPosnModReq "GVMC suspension height mode request";
CM_ SG_ 102 PVMCSuspHeiCtrlReqGVMCSuspPosnRLReq "GVMC supension height request RL";
CM_ SG_ 102 PVMCSuspHeiCtrlReqGVMCSuspPosnRRReq "GVMC supension height request RR";
CM_ SG_ 102 PVMCVehCtrlSts2ActrTarFctSts "actuator target funtion status";
CM_ SG_ 102 PVMCVehCtrlSts2BbWBackUpFctSts "Bbw back up funtion status";
CM_ SG_ 102 PVMCVehCtrlSts2BrkDiscClngFctSts "brake disc cleaning funtion status";
CM_ SG_ 102 PVMCVehCtrlSts2BrkTqDeltaFctSts "brake torque delta function status";
CM_ SG_ 102 PVMCVehCtrlSts2Chks "checksum";
CM_ SG_ 102 PVMCVehCtrlSts2Cntr "rollingcounter";
CM_ SG_ 102 PVMCVehCtrlSts2CrabMovgFctSts "crab move function status";
CM_ SG_ 102 PVMCVehCtrlSts2DecelReqActrSts "deceleration request actuator status";
CM_ SG_ 102 PVMCVehCtrlSts2FloatingDrvgFctSts "floating drive funtion status";
CM_ SG_ 102 PVMCVehCtrlSts2LowSpdStrFctSts "low speed function status";
CM_ SG_ 102 PVMCVehCtrlSts2SbWBackUpLatFctSts "sbw lateral back up funtion status";
CM_ SG_ 102 PVMCVehCtrlSts2SbWBackUpLgtFctSts "sbw longitudinal back up funtion status";
CM_ SG_ 102 PVMCVehCtrlSts2TankTurnFctSts "tank turn funtion status";
CM_ SG_ 102 PVMCVehCtrlSts2VDSWFctSts "VDSW funtion status";
CM_ SG_ 102 PVMCVehCtrlSts2ViolentModFctSts "violent mode funtion status";
CM_ SG_ 102 VehArbtSpdMax "Speed limit request after arbitration";
CM_ SG_ 102 VehSpdLimSrc "Speed limit request source";
CM_ SG_ 102 WhlSpdCircumlFrntChks "Individual wheel speed from front wheel speed sensors. Checksum";
CM_ SG_ 102 WhlSpdCircumlFrntCntr "Individual wheel speed from front wheel speed sensors. Counter";
CM_ SG_ 102 WhlSpdCircumlFrntLe "Individual wheel speed from front wheel speed sensors. Wheel speed from front left wheel speed sensor using nominal value of wheel radius.";
CM_ SG_ 102 WhlSpdCircumlFrntLeQf "Individual wheel speed from front wheel speed sensors. Qf for wheel speed sensor";
CM_ SG_ 102 WhlSpdCircumlFrntRiQf "Individual wheel speed from front wheel speed sensors. Qf for wheel speed sensor";
CM_ SG_ 102 WhlSpdCircumlFrntWhlSpdCircumlFrntRi "Individual wheel speed from front wheel speed sensors. Wheel speed from front right wheel speed sensor using nominal value of wheel radius";
CM_ SG_ 102 WhlSpdCircumlReChks "Individual wheel speed from rear wheel speed sensors. Checksum";
CM_ SG_ 102 WhlSpdCircumlReCntr "Individual wheel speed from rear wheel speed sensors. Counter";
CM_ SG_ 102 WhlSpdCircumlReLe "Individual wheel speed from rear wheel speed sensors. Wheel speed from rear left wheel speed sensor using nominal value of wheel radius.";
CM_ SG_ 102 WhlSpdCircumlReLeQf "Individual wheel speed from rear wheel speed sensors. Qf for wheel speed sensor";
CM_ SG_ 102 WhlSpdCircumlReRi "Individual wheel speed from rear wheel speed sensors. Wheel speed from rear right wheel speed sensor using nominal value of wheel radius.";
CM_ SG_ 102 WhlSpdCircumlReRiQf "Individual wheel speed from rear wheel speed sensors. Qf for wheel speed sensor";
CM_ SG_ 549 VehCfgPrmBlkIDBytePosn1 "signal block counter.";
CM_ SG_ 549 VehCfgPrmCCPBytePosn2 " (BlockID-1)*7 + 1. ";
CM_ SG_ 549 VehCfgPrmCCPBytePosn3 " (BlockID-1)*7 + 2. ";
CM_ SG_ 549 VehCfgPrmCCPBytePosn4 " (BlockID-1)*7 + 3. ";
CM_ SG_ 549 VehCfgPrmCCPBytePosn5 " (BlockID-1)*7 + 4. ";
CM_ SG_ 549 VehCfgPrmCCPBytePosn6 " (BlockID-1)*7 + 5. ";
CM_ SG_ 549 VehCfgPrmCCPBytePosn7 " (BlockID-1)*7 + 6. ";
CM_ SG_ 549 VehCfgPrmCCPBytePosn8 " (BlockID-1)*7 + 7. ";
CM_ SG_ 549 VehCfgPrmExt2BlkIDBytePosn1 "CarConfigExtended2 BlockID";
CM_ SG_ 549 VehCfgPrmExt2CCPBytePosn2 "CarConfigExtended2 BytePos2";
CM_ SG_ 549 VehCfgPrmExt2CCPBytePosn3 "CarConfigExtended2 BytePos3";
CM_ SG_ 549 VehCfgPrmExt2CCPBytePosn4 "CarConfigExtended2 BytePos4";
CM_ SG_ 549 VehCfgPrmExt2CCPBytePosn5 "CarConfigExtended2 BytePos5";
CM_ SG_ 549 VehCfgPrmExt2CCPBytePosn6 "CarConfigExtended2 BytePos6";
CM_ SG_ 549 VehCfgPrmExt2CCPBytePosn7 "CarConfigExtended2 BytePos7";
CM_ SG_ 549 VehCfgPrmExt2CCPBytePosn8 "CarConfigExtended2 BytePos8";
CM_ SG_ 549 VehCfgPrmExtBlkIDBytePosn1 "CarConfigExtended BlockID";
CM_ SG_ 549 VehCfgPrmExtCCPBytePosn2 "CarConfigExtended BytePos2";
CM_ SG_ 549 VehCfgPrmExtCCPBytePosn3 "CarConfigExtended BytePos3";
CM_ SG_ 549 VehCfgPrmExtCCPBytePosn4 "CarConfigExtended BytePos4";
CM_ SG_ 549 VehCfgPrmExtCCPBytePosn5 "CarConfigExtended BytePos5";
CM_ SG_ 549 VehCfgPrmExtCCPBytePosn6 "CarConfigExtended BytePos6";
CM_ SG_ 549 VehCfgPrmExtCCPBytePosn7 "CarConfigExtended BytePos7";
CM_ SG_ 549 VehCfgPrmExtCCPBytePosn8 "CarConfigExtended BytePos8";
CM_ SG_ 752 CmptmtTFrntCmptmtTFrnt "Measured temperature in compartment. ";
CM_ SG_ 752 CmptmtTFrntFanForCmptmtTRunng "Fan for component temperature requirement.";
CM_ SG_ 752 CmptmtTFrntQf "Component temperature sensor signal quality.";
CM_ SG_ 752 LiBattInPWLock "Li-ion battery power locking enable signal
When BMS2 sends BattFltStsPrim=15,set LiBattInPWLock=1, indicating that the Li-ion battery power is about to be locked, and LiBattInPWLock=0, indicating that the lithium battery power is not locked.

";
CM_ SG_ 752 RlyPwrDistbnCmd1WdIgnRlyCmd "Ignition relay status";
CM_ SG_ 752 ULoWarnLvPwrErrChks "Checksum";
CM_ SG_ 752 ULoWarnLvPwrErrCntr "Counter";
CM_ SG_ 752 ULoWarnLvPwrErrLVPwrSplyErrSts "Low voltage power supply error status";
CM_ SG_ 752 ULoWarnLvPwrErrULoWarn "ULoWarn for LVEEM";
CM_ SG_ 1281 WakeUpReasonsforZCUDM "WakeUpReasons";
CM_ SG_ 1345 VFCVectorZCUDMBlockID "BlockID";
CM_ SG_ 1345 VFCVectorZCUDMVFCid0 "SettingsComfort";
CM_ SG_ 1345 VFCVectorZCUDMVFCid1 "ParkingDrivingClimatization";
CM_ SG_ 1345 VFCVectorZCUDMVFCid10 "ExteriorLighting";
CM_ SG_ 1345 VFCVectorZCUDMVFCid11 "VFC11";
CM_ SG_ 1345 VFCVectorZCUDMVFCid12 "Alarm";
CM_ SG_ 1345 VFCVectorZCUDMVFCid13 "VFC13";
CM_ SG_ 1345 VFCVectorZCUDMVFCid14 "InteriorLighting";
CM_ SG_ 1345 VFCVectorZCUDMVFCid15 "VFC15";
CM_ SG_ 1345 VFCVectorZCUDMVFCid16 "Locking";
CM_ SG_ 1345 VFCVectorZCUDMVFCid17 "RemoteKeyFunctionality";
CM_ SG_ 1345 VFCVectorZCUDMVFCid18 "PropulsionStart";
CM_ SG_ 1345 VFCVectorZCUDMVFCid19 "VFC19";
CM_ SG_ 1345 VFCVectorZCUDMVFCid2 "PostClimatisation";
CM_ SG_ 1345 VFCVectorZCUDMVFCid20 "VFC20";
CM_ SG_ 1345 VFCVectorZCUDMVFCid21 "PowerClosures";
CM_ SG_ 1345 VFCVectorZCUDMVFCid22 "VehicleDriving";
CM_ SG_ 1345 VFCVectorZCUDMVFCid23 "VFC23";
CM_ SG_ 1345 VFCVectorZCUDMVFCid24 "SettingsProfile";
CM_ SG_ 1345 VFCVectorZCUDMVFCid25 "SeatComfortFunctions";
CM_ SG_ 1345 VFCVectorZCUDMVFCid26 "Brake";
CM_ SG_ 1345 VFCVectorZCUDMVFCid27 "InfotainmentPoll";
CM_ SG_ 1345 VFCVectorZCUDMVFCid28 "HVEnergyStorage";
CM_ SG_ 1345 VFCVectorZCUDMVFCid29 "VFC29";
CM_ SG_ 1345 VFCVectorZCUDMVFCid3 "PowertrainParkingClimatization";
CM_ SG_ 1345 VFCVectorZCUDMVFCid30 "TelematicsConnectivity";
CM_ SG_ 1345 VFCVectorZCUDMVFCid31 "VFC31";
CM_ SG_ 1345 VFCVectorZCUDMVFCid32 "VFC32";
CM_ SG_ 1345 VFCVectorZCUDMVFCid33 "Diagnostics";
CM_ SG_ 1345 VFCVectorZCUDMVFCid34 "VehicleModeManagement";
CM_ SG_ 1345 VFCVectorZCUDMVFCid35 "TrailerCaravanFunctions";
CM_ SG_ 1345 VFCVectorZCUDMVFCid36 "Immobilizer";
CM_ SG_ 1345 VFCVectorZCUDMVFCid37 "Windows";
CM_ SG_ 1345 VFCVectorZCUDMVFCid38 "Visibility";
CM_ SG_ 1345 VFCVectorZCUDMVFCid39 "VFC39";
CM_ SG_ 1345 VFCVectorZCUDMVFCid4 "VFC4";
CM_ SG_ 1345 VFCVectorZCUDMVFCid40 "VFC40";
CM_ SG_ 1345 VFCVectorZCUDMVFCid41 "InfotainmentPush";
CM_ SG_ 1345 VFCVectorZCUDMVFCid42 "ChargingHV";
CM_ SG_ 1345 VFCVectorZCUDMVFCid43 "BodyPreClimatisation";
CM_ SG_ 1345 VFCVectorZCUDMVFCid44 "Crash";
CM_ SG_ 1345 VFCVectorZCUDMVFCid45 "GlobalShortDuration";
CM_ SG_ 1345 VFCVectorZCUDMVFCid46 "ExteriorLightsHazard";
CM_ SG_ 1345 VFCVectorZCUDMVFCid47 "VFC47";
CM_ SG_ 1345 VFCVectorZCUDMVFCid48 "DoorOpenWarning";
CM_ SG_ 1345 VFCVectorZCUDMVFCid49 "ChargingLVInit";
CM_ SG_ 1345 VFCVectorZCUDMVFCid5 "VFC5";
CM_ SG_ 1345 VFCVectorZCUDMVFCid50 "VFC50";
CM_ SG_ 1345 VFCVectorZCUDMVFCid51 "VFC51";
CM_ SG_ 1345 VFCVectorZCUDMVFCid52 "HVBatteryThermalEventWarning";
CM_ SG_ 1345 VFCVectorZCUDMVFCid53 "VisualAssist";
CM_ SG_ 1345 VFCVectorZCUDMVFCid54 "PassiveSafety";
CM_ SG_ 1345 VFCVectorZCUDMVFCid55 "LifeDetection";
CM_ SG_ 1345 VFCVectorZCUDMVFCid56 "BackboneFlexray";
CM_ SG_ 1345 VFCVectorZCUDMVFCid57 "Functionmarket";
CM_ SG_ 1345 VFCVectorZCUDMVFCid58 "VFCid58";
CM_ SG_ 1345 VFCVectorZCUDMVFCid59 "VFCid59";
CM_ SG_ 1345 VFCVectorZCUDMVFCid6 "SettingsVehicle";
CM_ SG_ 1345 VFCVectorZCUDMVFCid60 "VFCid60";
CM_ SG_ 1345 VFCVectorZCUDMVFCid61 "VFCid61";
CM_ SG_ 1345 VFCVectorZCUDMVFCid7 "VFC7";
CM_ SG_ 1345 VFCVectorZCUDMVFCid8 "VFC8";
CM_ SG_ 1345 VFCVectorZCUDMVFCid9 "IPWakeup";
CM_ SG_ 535 CDCModlndcnForFAS "CDC mode status";
CM_ SG_ 535 FASActFAryFL "FL active force";
CM_ SG_ 535 FASActFAryFR "FR active force";
CM_ SG_ 535 FASActFAryRL "RL active force";
CM_ SG_ 535 FASActFAryRR "RR active force";
CM_ SG_ 535 FASChassisObstclCrsModIncn "chassis obstacle crossing function mode indication";
CM_ SG_ 535 FASDrvModPrsnlAdjmtDamprCmftSts "can the current setting be selected";
CM_ SG_ 535 FASDrvModPrsnlAdjmtDamprHardSts "can the current setting be selected";
CM_ SG_ 535 FASDrvModPrsnlAdjmtDamprMedSts "can the current setting be selected";
CM_ SG_ 535 FASDrvModPrsnlAdjmtDamprSts_Resv1 "can the current setting be selected";
CM_ SG_ 535 FASDrvModPrsnlAdjmtDamprSts_Resv2 "can the current setting be selected";
CM_ SG_ 535 FASDrvModPrsnlAdjmtSuspLvlHL1Sts "can the current setting be selected";
CM_ SG_ 535 FASDrvModPrsnlAdjmtSuspLvlHL2Sts "can the current setting be selected";
CM_ SG_ 535 FASDrvModPrsnlAdjmtSuspLvlLL1Sts "can the current setting be selected";
CM_ SG_ 535 FASDrvModPrsnlAdjmtSuspLvlLL2Sts "can the current setting be selected";
CM_ SG_ 535 FASDrvModPrsnlAdjmtSuspLvlNRHSts "can the current setting be selected";
CM_ SG_ 535 FASEasyLoadModlndcn "Easy Load Mold Indication";
CM_ SG_ 535 FASHeiLimModIncn "height limit active adjust function mode indication.";
CM_ SG_ 535 FASLvlgDirMovmtindcr "This signal is used for indicating the movement direction in the air suspension during its change.";
CM_ SG_ 535 FASLvlgFctAvl "One KeyLeveling function availability";
CM_ SG_ 535 FASLvlgFctSts "One KeyLeveling function staus";
CM_ SG_ 535 FullActvSuspFailrStsSuspFailrSts "This DATA-Element is used by the air suspension to inform that a severe error is present in the system, Error type.";
CM_ SG_ 535 FullActvSuspFailrStsSuspFailrStsChks "This DATA-Element is used by the air suspension to inform that a severe error is present in the system,Checksum";
CM_ SG_ 535 FullActvSuspFailrStsSuspFailrStsCntr "This DATA-Element is used by the air suspension to inform that a severe error is present in the system,Counter";
CM_ SG_ 535 FullActvSuspFailrStsSuspFailrStsTypQf "This DATA-Element is used by the air suspension to inform that a severe error is present in the system,Quality Factor";
CM_ SG_ 535 FullActvSuspHeilvlindcn "This signal specifies which height the body has reached.";
CM_ SG_ 535 FullActvSuspStabyCritFailrDetdChks "This DATA-Element is used to inform that a stability problem has occur in the wheel suspension.Checksum";
CM_ SG_ 535 FullActvSuspStabyCritFailrDetdCntr "This DATA-Element is used to inform that a stability problem has occur in the wheel suspension.Couter";
CM_ SG_ 535 FullActvSuspStabyCritFailrDetdSts "This DATA-Element is used to inform that a stability problem has occur in the wheel suspension.";
CM_ SG_ 101 FASBodyHei "Body height is a calculated average value from the four level sensors at each wheel.";
CM_ SG_ 101 FullActvSuspPosnVertLeChks "External CAN signal to inform the right body height include both front and rear) with ASIL-A leve(A CRC is added).Checksum on height information and Qf for front and rear";
CM_ SG_ 101 FullActvSuspPosnVertLeFrnt "External CAN signal to inform the right body height include both front and rear) with ASIL-A leve(A CRC is added). Height information from left front";
CM_ SG_ 101 FullActvSuspPosnVertLeFrntQf "External CAN signal to inform the right body height include both front and rear) with ASIL-A leve(A CRC is added).Qf on height information from left front";
CM_ SG_ 101 FullActvSuspPosnVertLeRe "External CAN signal to inform the right body height include both front and rear) with ASIL-A leve(A CRC is added). Height information from left rear";
CM_ SG_ 101 FullActvSuspPosnVertLeReQf "External CAN signal to inform the right body height include both front and rear) with ASIL-A leve(A CRC is added).Qf on height information from left rear";
CM_ SG_ 101 FullActvSuspPosnVertRiChks "External CAN signal to inform the right body height include both front and rear) with ASIL-A leve(A CRC is added).Checksum on height information and Qf for front and rear";
CM_ SG_ 101 FullActvSuspPosnVertRiFrnt "External CAN signal to inform the right body height include both front and rear) with ASIL-A leve(A CRC is added). Height information from right front";
CM_ SG_ 101 FullActvSuspPosnVertRiFrntQf "External CAN signal to inform the right body height include both front and rear) with ASIL-A leve(A CRC is added).Qf on height information from right front";
CM_ SG_ 101 FullActvSuspPosnVertRiRe "External CAN signal to inform the right body height include both front and rear) with ASIL-A leve(A CRC is added). Height information from right rear";
CM_ SG_ 101 FullActvSuspPosnVertRiReQf "External CAN signal to inform the right body height include both front and rear) with ASIL-A leve(A CRC is added).Qf on height information from right rear";
CM_ SG_ 101 ZCUTForceMaxFrntLe "FAS FL corner maximum damping force";
CM_ SG_ 101 ZCUTForceMaxFrntRi "FAS FR corner maximum damping force";
CM_ SG_ 101 ZCUTForceMaxReLe "FAS RL corner maximum damping force";
CM_ SG_ 101 ZCUTForceMaxReRi "FAS RR corner maximum damping force";
CM_ SG_ 101 ZCUTForceRealFrntLe "FAS FL corner current damping force";
CM_ SG_ 101 ZCUTForceRealFrntRi "FAS FR corner current damping force";
CM_ SG_ 101 ZCUTForceRealReLe "FAS RL corner current damping force";
CM_ SG_ 101 ZCUTForceRealReRi "FAS RR corner current damping force";
CM_ SG_ 101 ZCUTToVMCAvl "FAS handshake status";
CM_ SG_ 266 FasCritPwrReq "critical function power request";
CM_ SG_ 266 FasPwrAct "fas actual power feedback";
CM_ SG_ 266 FasPwrReq "normal function power request";
CM_ SG_ 1282 WakeUpReasonsforZCUT "ECUWakeupReasons";
CM_ SG_ 1346 VFCVectorZCUTBlockID "BlockID";
CM_ SG_ 1346 VFCVectorZCUTVFCid0 "SettingsComfort";
CM_ SG_ 1346 VFCVectorZCUTVFCid1 "ParkingDrivingClimatization";
CM_ SG_ 1346 VFCVectorZCUTVFCid10 "ExteriorLighting";
CM_ SG_ 1346 VFCVectorZCUTVFCid11 "VFC11";
CM_ SG_ 1346 VFCVectorZCUTVFCid12 "Alarm";
CM_ SG_ 1346 VFCVectorZCUTVFCid13 "VFC13";
CM_ SG_ 1346 VFCVectorZCUTVFCid14 "InteriorLighting";
CM_ SG_ 1346 VFCVectorZCUTVFCid15 "VFC15";
CM_ SG_ 1346 VFCVectorZCUTVFCid16 "Locking";
CM_ SG_ 1346 VFCVectorZCUTVFCid17 "RemoteKeyFunctionality";
CM_ SG_ 1346 VFCVectorZCUTVFCid18 "PropulsionStart";
CM_ SG_ 1346 VFCVectorZCUTVFCid19 "VFC19";
CM_ SG_ 1346 VFCVectorZCUTVFCid2 "PostClimatisation";
CM_ SG_ 1346 VFCVectorZCUTVFCid20 "VFC20";
CM_ SG_ 1346 VFCVectorZCUTVFCid21 "PowerClosures";
CM_ SG_ 1346 VFCVectorZCUTVFCid22 "VehicleDriving";
CM_ SG_ 1346 VFCVectorZCUTVFCid23 "VFC23";
CM_ SG_ 1346 VFCVectorZCUTVFCid24 "SettingsProfile";
CM_ SG_ 1346 VFCVectorZCUTVFCid25 "SeatComfortFunctions";
CM_ SG_ 1346 VFCVectorZCUTVFCid26 "Brake";
CM_ SG_ 1346 VFCVectorZCUTVFCid27 "InfotainmentPoll";
CM_ SG_ 1346 VFCVectorZCUTVFCid28 "HVEnergyStorage";
CM_ SG_ 1346 VFCVectorZCUTVFCid29 "VFC29";
CM_ SG_ 1346 VFCVectorZCUTVFCid3 "PowertrainParkingClimatization";
CM_ SG_ 1346 VFCVectorZCUTVFCid30 "TelematicsConnectivity";
CM_ SG_ 1346 VFCVectorZCUTVFCid31 "VFC31";
CM_ SG_ 1346 VFCVectorZCUTVFCid32 "VFC32";
CM_ SG_ 1346 VFCVectorZCUTVFCid33 "Diagnostics";
CM_ SG_ 1346 VFCVectorZCUTVFCid34 "VehicleModeManagement";
CM_ SG_ 1346 VFCVectorZCUTVFCid35 "TrailerCaravanFunctions";
CM_ SG_ 1346 VFCVectorZCUTVFCid36 "Immobilizer";
CM_ SG_ 1346 VFCVectorZCUTVFCid37 "Windows";
CM_ SG_ 1346 VFCVectorZCUTVFCid38 "Visibility";
CM_ SG_ 1346 VFCVectorZCUTVFCid39 "VFC39";
CM_ SG_ 1346 VFCVectorZCUTVFCid4 "VFC4";
CM_ SG_ 1346 VFCVectorZCUTVFCid40 "VFC40";
CM_ SG_ 1346 VFCVectorZCUTVFCid41 "InfotainmentPush";
CM_ SG_ 1346 VFCVectorZCUTVFCid42 "ChargingHV";
CM_ SG_ 1346 VFCVectorZCUTVFCid43 "BodyPreClimatisation";
CM_ SG_ 1346 VFCVectorZCUTVFCid44 "Crash";
CM_ SG_ 1346 VFCVectorZCUTVFCid45 "GlobalShortDuration";
CM_ SG_ 1346 VFCVectorZCUTVFCid46 "ExteriorLightsHazard";
CM_ SG_ 1346 VFCVectorZCUTVFCid47 "VFC47";
CM_ SG_ 1346 VFCVectorZCUTVFCid48 "DoorOpenWarning";
CM_ SG_ 1346 VFCVectorZCUTVFCid49 "ChargingLVInit";
CM_ SG_ 1346 VFCVectorZCUTVFCid5 "VFC5";
CM_ SG_ 1346 VFCVectorZCUTVFCid50 "VFC50";
CM_ SG_ 1346 VFCVectorZCUTVFCid51 "VFC51";
CM_ SG_ 1346 VFCVectorZCUTVFCid52 "HVBatteryThermalEventWarning";
CM_ SG_ 1346 VFCVectorZCUTVFCid53 "VisualAssist";
CM_ SG_ 1346 VFCVectorZCUTVFCid54 "PassiveSafety";
CM_ SG_ 1346 VFCVectorZCUTVFCid55 "LifeDetection";
CM_ SG_ 1346 VFCVectorZCUTVFCid56 "BackboneFlexray";
CM_ SG_ 1346 VFCVectorZCUTVFCid57 "Functionmarket";
CM_ SG_ 1346 VFCVectorZCUTVFCid58 "VFCid58";
CM_ SG_ 1346 VFCVectorZCUTVFCid59 "VFCid59";
CM_ SG_ 1346 VFCVectorZCUTVFCid6 "SettingsVehicle";
CM_ SG_ 1346 VFCVectorZCUTVFCid60 "VFCid60";
CM_ SG_ 1346 VFCVectorZCUTVFCid61 "VFCid61";
CM_ SG_ 1346 VFCVectorZCUTVFCid7 "VFC7";
CM_ SG_ 1346 VFCVectorZCUTVFCid8 "VFC8";
CM_ SG_ 1346 VFCVectorZCUTVFCid9 "IPWakeup";
BA_DEF_ BO_ "NmAsrMessage" ENUM "No","Yes";
BA_DEF_ BO_ "GenMsgStartDelayTime" INT 0 65536;
BA_DEF_ BO_ "GenMsgSendType" ENUM "cyclic","spontaneous","not-used","not-used","not-used","cyclicAndSpontaneous","not-used","cyclicIfActive","NoMsgSendType";
BA_DEF_ BO_ "GenMsgILSupport" ENUM "No","Yes";
BA_DEF_ BO_ "GenMsgDelayTime" INT 0 65536;
BA_DEF_ BO_ "GenMsgCycleTime" INT 0 65536;
BA_DEF_ BO_ "CANFD_BRS" ENUM "0","1";
BA_DEF_ BO_ "VFrameFormat" ENUM "StandardCAN","ExtendedCAN","reserved","J1939PG","reserved","reserved","reserved","reserved","reserved","reserved","reserved","reserved","reserved","reserved","StandardCAN_FD","ExtendedCAN_FD";
BA_DEF_ SG_ "GenSigStartValue" HEX 0 80000000;
BA_DEF_ SG_ "GenSigSendType" ENUM "Cyclic","OnWrite","OnWriteWithRepetition","OnChange","OnChangeWithRepetition","IfActive","IfActiveWithRepetition","NoSigSendType";
BA_DEF_ SG_ "GenSigFuncType" ENUM "NoFunction","n/a","n/a","n/a","n/a","n/a","n/a","n/a","n/a","n/a","n/a","n/a","n/a","n/a","n/a","CHK","CNTR","n/a","n/a","n/a","CNTR_AR_01","CRC_AR_01_BOTH","CRC_AR_01_ALT","CRC_AR_01_LOW","CRC_AR_01_NIBBLE","CNTR_AR_04","CRC_AR_04A","CNTR_AR_05","CRC_AR_05";
BA_DEF_ SG_ "GenSigDataID" STRING ;
BA_DEF_DEF_ "NmAsrMessage" "No";
BA_DEF_DEF_ "GenMsgStartDelayTime" 0;
BA_DEF_DEF_ "GenMsgSendType" "NoMsgSendType";
BA_DEF_DEF_ "GenMsgILSupport" "Yes";
BA_DEF_DEF_ "GenMsgDelayTime" 0;
BA_DEF_DEF_ "GenMsgCycleTime" 0;
BA_DEF_DEF_ "CANFD_BRS" "1";
BA_DEF_DEF_ "VFrameFormat" "J1939PG";
BA_DEF_DEF_ "GenSigStartValue" 0;
BA_DEF_DEF_ "GenSigSendType" "NoSigSendType";
BA_DEF_DEF_ "GenSigFuncType" "NoFunction";
BA_DEF_DEF_ "GenSigDataID" "";
BA_ "GenMsgCycleTime" BO_ 85 10;
BA_ "GenMsgSendType" BO_ 85 0;
BA_ "VFrameFormat" BO_ 85 14;
BA_ "GenMsgCycleTime" BO_ 339 50;
BA_ "GenMsgSendType" BO_ 339 0;
BA_ "VFrameFormat" BO_ 339 14;
BA_ "GenMsgCycleTime" BO_ 289 30;
BA_ "GenMsgSendType" BO_ 289 0;
BA_ "VFrameFormat" BO_ 289 14;
BA_ "GenMsgCycleTime" BO_ 1173 1000;
BA_ "GenMsgSendType" BO_ 1173 0;
BA_ "VFrameFormat" BO_ 1173 14;
BA_ "GenMsgCycleTime" BO_ 569 100;
BA_ "GenMsgSendType" BO_ 569 0;
BA_ "VFrameFormat" BO_ 569 14;
BA_ "GenMsgCycleTime" BO_ 625 200;
BA_ "GenMsgSendType" BO_ 625 0;
BA_ "VFrameFormat" BO_ 625 14;
BA_ "GenMsgDelayTime" BO_ 131 5;
BA_ "GenMsgSendType" BO_ 131 1;
BA_ "VFrameFormat" BO_ 131 14;
BA_ "GenMsgCycleTime" BO_ 102 10;
BA_ "GenMsgSendType" BO_ 102 0;
BA_ "VFrameFormat" BO_ 102 14;
BA_ "GenMsgDelayTime" BO_ 549 80;
BA_ "GenMsgSendType" BO_ 549 1;
BA_ "VFrameFormat" BO_ 549 14;
BA_ "GenMsgCycleTime" BO_ 752 150;
BA_ "GenMsgSendType" BO_ 752 0;
BA_ "VFrameFormat" BO_ 752 14;
BA_ "GenMsgDelayTime" BO_ 1281 20;
BA_ "NmAsrMessage" BO_ 1281 1;
BA_ "GenMsgILSupport" BO_ 1281 0;
BA_ "GenMsgSendType" BO_ 1281 1;
BA_ "VFrameFormat" BO_ 1281 0;
BA_ "GenMsgCycleTime" BO_ 1345 1000;
BA_ "GenMsgSendType" BO_ 1345 0;
BA_ "VFrameFormat" BO_ 1345 0;
BA_ "GenMsgCycleTime" BO_ 535 80;
BA_ "GenMsgSendType" BO_ 535 0;
BA_ "VFrameFormat" BO_ 535 14;
BA_ "GenMsgCycleTime" BO_ 101 10;
BA_ "GenMsgSendType" BO_ 101 0;
BA_ "VFrameFormat" BO_ 101 14;
BA_ "GenMsgCycleTime" BO_ 266 20;
BA_ "GenMsgSendType" BO_ 266 0;
BA_ "VFrameFormat" BO_ 266 14;
BA_ "GenMsgDelayTime" BO_ 1282 20;
BA_ "NmAsrMessage" BO_ 1282 1;
BA_ "GenMsgILSupport" BO_ 1282 0;
BA_ "GenMsgSendType" BO_ 1282 1;
BA_ "VFrameFormat" BO_ 1282 0;
BA_ "GenMsgCycleTime" BO_ 1346 1000;
BA_ "GenMsgSendType" BO_ 1346 0;
BA_ "VFrameFormat" BO_ 1346 0;
BA_ "GenSigDataID" SG_ 85 EscStChks "0x7F";
BA_ "GenSigFuncType" SG_ 85 EscStChks 15;
BA_ "GenSigSendType" SG_ 85 EscStChks 0;
BA_ "GenSigFuncType" SG_ 85 EscStCntr 16;
BA_ "GenSigSendType" SG_ 85 EscStCntr 0;
BA_ "GenSigStartValue" SG_ 85 EscStEscSt 1;
BA_ "GenSigSendType" SG_ 85 EscStEscSt 0;
BA_ "GenSigStartValue" SG_ 85 GearLvrIndcn 7;
BA_ "GenSigSendType" SG_ 85 GearLvrIndcn 0;
BA_ "GenSigDataID" SG_ 85 GVMCPrpsnTqDistReqChks "0x1A7A";
BA_ "GenSigFuncType" SG_ 85 GVMCPrpsnTqDistReqChks 15;
BA_ "GenSigSendType" SG_ 85 GVMCPrpsnTqDistReqChks 0;
BA_ "GenSigFuncType" SG_ 85 GVMCPrpsnTqDistReqCntr 16;
BA_ "GenSigSendType" SG_ 85 GVMCPrpsnTqDistReqCntr 0;
BA_ "GenSigSendType" SG_ 85 GVMCPrpsnTqDistReqCtrlMod 0;
BA_ "GenSigStartValue" SG_ 85 GVMCPrpsnTqDistReqDistReq 12800;
BA_ "GenSigSendType" SG_ 85 GVMCPrpsnTqDistReqDistReq 0;
BA_ "GenSigDataID" SG_ 85 GVMCSteerWhlAgReqFrntChks "0x1A7E";
BA_ "GenSigFuncType" SG_ 85 GVMCSteerWhlAgReqFrntChks 15;
BA_ "GenSigSendType" SG_ 85 GVMCSteerWhlAgReqFrntChks 0;
BA_ "GenSigFuncType" SG_ 85 GVMCSteerWhlAgReqFrntCntr 16;
BA_ "GenSigSendType" SG_ 85 GVMCSteerWhlAgReqFrntCntr 0;
BA_ "GenSigSendType" SG_ 85 GVMCSteerWhlAgReqFrntSteerWhlAgCtrl 0;
BA_ "GenSigSendType" SG_ 85 GVMCSteerWhlAgReqFrntSteerWhlCtrlSts 0;
BA_ "GenSigSendType" SG_ 85 GVMCSteerWhlAgReqFrntSteerWhlTqCtrl 0;
BA_ "GenSigDataID" SG_ 85 GVMCVehCtrlrStsChks "0x1A79";
BA_ "GenSigFuncType" SG_ 85 GVMCVehCtrlrStsChks 15;
BA_ "GenSigSendType" SG_ 85 GVMCVehCtrlrStsChks 0;
BA_ "GenSigFuncType" SG_ 85 GVMCVehCtrlrStsCntr 16;
BA_ "GenSigSendType" SG_ 85 GVMCVehCtrlrStsCntr 0;
BA_ "GenSigSendType" SG_ 85 GVMCVehCtrlrStsCtrlrSts 0;
BA_ "GenSigStartValue" SG_ 85 GVMCVehVActLatAct 7672.634271;
BA_ "GenSigSendType" SG_ 85 GVMCVehVActLatAct 0;
BA_ "GenSigStartValue" SG_ 85 GVMCVehVActLgtAct 7672.634271;
BA_ "GenSigSendType" SG_ 85 GVMCVehVActLgtAct 0;
BA_ "GenSigStartValue" SG_ 85 GVMCVehVActQf 1;
BA_ "GenSigSendType" SG_ 85 GVMCVehVActQf 0;
BA_ "GenSigStartValue" SG_ 85 GVMCVehYawRateTar 10;
BA_ "GenSigSendType" SG_ 85 GVMCVehYawRateTar 0;
BA_ "GenSigStartValue" SG_ 85 GVMCYawRateCOGActAct 25000;
BA_ "GenSigSendType" SG_ 85 GVMCYawRateCOGActAct 0;
BA_ "GenSigStartValue" SG_ 85 GVMCYawRateCOGActQf 1;
BA_ "GenSigSendType" SG_ 85 GVMCYawRateCOGActQf 0;
BA_ "GenSigStartValue" SG_ 85 LatCtrlReqSafeChks 255;
BA_ "GenSigDataID" SG_ 85 LatCtrlReqSafeChks "0x30";
BA_ "GenSigFuncType" SG_ 85 LatCtrlReqSafeChks 15;
BA_ "GenSigSendType" SG_ 85 LatCtrlReqSafeChks 0;
BA_ "GenSigFuncType" SG_ 85 LatCtrlReqSafeCntr 16;
BA_ "GenSigSendType" SG_ 85 LatCtrlReqSafeCntr 0;
BA_ "GenSigSendType" SG_ 85 LatCtrlReqSafeLatCtrlModReq 0;
BA_ "GenSigSendType" SG_ 85 LatCtrlReqSafeSteerTqReq 0;
BA_ "GenSigSendType" SG_ 85 LatCtrlReqSafeSteerWhlHptcWarnReq 0;
BA_ "GenSigSendType" SG_ 85 SteerWhlSnsrAg 0;
BA_ "GenSigSendType" SG_ 85 SteerWhlSnsrAgSpd 0;
BA_ "GenSigDataID" SG_ 85 SteerWhlSnsrChks "0x33";
BA_ "GenSigFuncType" SG_ 85 SteerWhlSnsrChks 15;
BA_ "GenSigSendType" SG_ 85 SteerWhlSnsrChks 0;
BA_ "GenSigFuncType" SG_ 85 SteerWhlSnsrCntr 16;
BA_ "GenSigSendType" SG_ 85 SteerWhlSnsrCntr 0;
BA_ "GenSigStartValue" SG_ 85 SteerWhlSnsrQf 1;
BA_ "GenSigSendType" SG_ 85 SteerWhlSnsrQf 0;
BA_ "GenSigSendType" SG_ 85 VehModMngtGlbSafe1CarModSts1 0;
BA_ "GenSigSendType" SG_ 85 VehModMngtGlbSafe1CarModSubtypWdCarModSubtyp 0;
BA_ "GenSigDataID" SG_ 85 VehModMngtGlbSafe1Chks "0x74";
BA_ "GenSigFuncType" SG_ 85 VehModMngtGlbSafe1Chks 15;
BA_ "GenSigSendType" SG_ 85 VehModMngtGlbSafe1Chks 0;
BA_ "GenSigFuncType" SG_ 85 VehModMngtGlbSafe1Cntr 16;
BA_ "GenSigSendType" SG_ 85 VehModMngtGlbSafe1Cntr 0;
BA_ "GenSigSendType" SG_ 85 VehModMngtGlbSafe1EgyLvlElecMai 0;
BA_ "GenSigSendType" SG_ 85 VehModMngtGlbSafe1EgyLvlElecSubtyp 0;
BA_ "GenSigSendType" SG_ 85 VehModMngtGlbSafe1FltEgyCnsWdSts 0;
BA_ "GenSigSendType" SG_ 85 VehModMngtGlbSafe1PwrLvlElecMai 0;
BA_ "GenSigSendType" SG_ 85 VehModMngtGlbSafe1PwrLvlElecSubtyp 0;
BA_ "GenSigStartValue" SG_ 85 VehModMngtGlbSafe1UsgModSts 1;
BA_ "GenSigSendType" SG_ 85 VehModMngtGlbSafe1UsgModSts 0;
BA_ "GenSigDataID" SG_ 85 VehMtnStChks "0x36";
BA_ "GenSigFuncType" SG_ 85 VehMtnStChks 15;
BA_ "GenSigSendType" SG_ 85 VehMtnStChks 0;
BA_ "GenSigFuncType" SG_ 85 VehMtnStCntr 16;
BA_ "GenSigSendType" SG_ 85 VehMtnStCntr 0;
BA_ "GenSigSendType" SG_ 85 VehMtnStVehMtnSt 0;
BA_ "GenSigSendType" SG_ 85 VehSpdLgtA 0;
BA_ "GenSigDataID" SG_ 85 VehSpdLgtChks "0x37";
BA_ "GenSigFuncType" SG_ 85 VehSpdLgtChks 15;
BA_ "GenSigSendType" SG_ 85 VehSpdLgtChks 0;
BA_ "GenSigFuncType" SG_ 85 VehSpdLgtCntr 16;
BA_ "GenSigSendType" SG_ 85 VehSpdLgtCntr 0;
BA_ "GenSigStartValue" SG_ 85 VehSpdLgtQf 1;
BA_ "GenSigSendType" SG_ 85 VehSpdLgtQf 0;
BA_ "GenSigSendType" SG_ 85 WhlFastSpdSafeA 0;
BA_ "GenSigDataID" SG_ 85 WhlFastSpdSafeChks "0x1972";
BA_ "GenSigFuncType" SG_ 85 WhlFastSpdSafeChks 15;
BA_ "GenSigSendType" SG_ 85 WhlFastSpdSafeChks 0;
BA_ "GenSigFuncType" SG_ 85 WhlFastSpdSafeCntr 16;
BA_ "GenSigSendType" SG_ 85 WhlFastSpdSafeCntr 0;
BA_ "GenSigStartValue" SG_ 85 WhlFastSpdSafeQF 1;
BA_ "GenSigSendType" SG_ 85 WhlFastSpdSafeQF 0;
BA_ "GenSigDataID" SG_ 85 WhlRotToothCntrChks "0x19C8";
BA_ "GenSigFuncType" SG_ 85 WhlRotToothCntrChks 15;
BA_ "GenSigSendType" SG_ 85 WhlRotToothCntrChks 0;
BA_ "GenSigFuncType" SG_ 85 WhlRotToothCntrCntr 16;
BA_ "GenSigSendType" SG_ 85 WhlRotToothCntrCntr 0;
BA_ "GenSigSendType" SG_ 85 WhlRotToothCntrFrntLe 0;
BA_ "GenSigSendType" SG_ 85 WhlRotToothCntrFrntRi 0;
BA_ "GenSigSendType" SG_ 85 WhlRotToothCntrReLe 0;
BA_ "GenSigSendType" SG_ 85 WhlRotToothCntrReRi 0;
BA_ "GenSigSendType" SG_ 85 YawRateReqdByDrvr 0;
BA_ "GenSigDataID" SG_ 339 DrvrGearShiftDirReq1Chks "0x39";
BA_ "GenSigFuncType" SG_ 339 DrvrGearShiftDirReq1Chks 15;
BA_ "GenSigSendType" SG_ 339 DrvrGearShiftDirReq1Chks 0;
BA_ "GenSigFuncType" SG_ 339 DrvrGearShiftDirReq1Cntr 16;
BA_ "GenSigSendType" SG_ 339 DrvrGearShiftDirReq1Cntr 0;
BA_ "GenSigSendType" SG_ 339 DrvrGearShiftDirReq1DwnDwnTipAut 0;
BA_ "GenSigSendType" SG_ 339 DrvrGearShiftDirReq1DwnTipAut 0;
BA_ "GenSigSendType" SG_ 339 DrvrGearShiftDirReq1PosnAut 0;
BA_ "GenSigSendType" SG_ 339 DrvrGearShiftDirReq1UpTipAut 0;
BA_ "GenSigSendType" SG_ 339 DrvrGearShiftDirReq1UpUpTipAut 0;
BA_ "GenSigDataID" SG_ 339 DrvrGearShiftDirReq2Chks "0x62";
BA_ "GenSigFuncType" SG_ 339 DrvrGearShiftDirReq2Chks 15;
BA_ "GenSigSendType" SG_ 339 DrvrGearShiftDirReq2Chks 0;
BA_ "GenSigFuncType" SG_ 339 DrvrGearShiftDirReq2Cntr 16;
BA_ "GenSigSendType" SG_ 339 DrvrGearShiftDirReq2Cntr 0;
BA_ "GenSigSendType" SG_ 339 DrvrGearShiftDirReq2DwnDwnTipAut 0;
BA_ "GenSigSendType" SG_ 339 DrvrGearShiftDirReq2DwnTipAut 0;
BA_ "GenSigSendType" SG_ 339 DrvrGearShiftDirReq2PosnAut 0;
BA_ "GenSigSendType" SG_ 339 DrvrGearShiftDirReq2UpTipAut 0;
BA_ "GenSigSendType" SG_ 339 DrvrGearShiftDirReq2UpUpTipAut 0;
BA_ "GenSigSendType" SG_ 339 RWASteerLockReqCommand 0;
BA_ "GenSigSendType" SG_ 339 RWASteerLockReqSteerLockDataReq0 0;
BA_ "GenSigSendType" SG_ 339 RWASteerLockReqSteerLockDataReq1 0;
BA_ "GenSigSendType" SG_ 339 RWASteerLockReqSteerLockDataReq2 0;
BA_ "GenSigSendType" SG_ 339 RWASteerLockReqSteerLockDataReq3 0;
BA_ "GenSigSendType" SG_ 339 RWASteerLockReqSteerLockDataReq4 0;
BA_ "GenSigSendType" SG_ 339 RWASteerLockReqSteerLockDataReq5 0;
BA_ "GenSigSendType" SG_ 339 RWASteerLockReqSteerLockDataReq6 0;
BA_ "GenSigSendType" SG_ 339 SteerEmergCtrlSwt 0;
BA_ "GenSigSendType" SG_ 339 SteerRatModReq 0;
BA_ "GenSigSendType" SG_ 339 SteerSetgPen 0;
BA_ "GenSigSendType" SG_ 339 SteerSetgSteerAsscLvl 0;
BA_ "GenSigSendType" SG_ 339 SteerSetgSteerMod 0;
BA_ "GenSigSendType" SG_ 339 SuspCmprSpd 0;
BA_ "GenSigDataID" SG_ 339 SuspDistbnVlvCtrlStsChks "0x26EA";
BA_ "GenSigFuncType" SG_ 339 SuspDistbnVlvCtrlStsChks 15;
BA_ "GenSigSendType" SG_ 339 SuspDistbnVlvCtrlStsChks 0;
BA_ "GenSigFuncType" SG_ 339 SuspDistbnVlvCtrlStsCntr 16;
BA_ "GenSigSendType" SG_ 339 SuspDistbnVlvCtrlStsCntr 0;
BA_ "GenSigSendType" SG_ 339 SuspDistbnVlvCtrlStsSuspDistbnVlvCtrlSts 0;
BA_ "GenSigSendType" SG_ 339 SuspStfnVlvCtrlStsFL 0;
BA_ "GenSigSendType" SG_ 339 SuspStfnVlvCtrlStsFR 0;
BA_ "GenSigSendType" SG_ 339 SuspStfnVlvCtrlStsRL 0;
BA_ "GenSigSendType" SG_ 339 SuspStfnVlvCtrlStsRR 0;
BA_ "GenSigDataID" SG_ 339 ZCAirSuspCtrlStsChks "0x26EB";
BA_ "GenSigFuncType" SG_ 339 ZCAirSuspCtrlStsChks 15;
BA_ "GenSigSendType" SG_ 339 ZCAirSuspCtrlStsChks 0;
BA_ "GenSigFuncType" SG_ 339 ZCAirSuspCtrlStsCntr 16;
BA_ "GenSigSendType" SG_ 339 ZCAirSuspCtrlStsCntr 0;
BA_ "GenSigSendType" SG_ 339 ZCAirSuspCtrlStsZCAirSuspCtrlSts 0;
BA_ "GenSigSendType" SG_ 289 BBWPullOverReq 0;
BA_ "GenSigSendType" SG_ 289 BrkPedlPsdBrkPedlNotPsdSafe 0;
BA_ "GenSigSendType" SG_ 289 BrkPedlPsdBrkPedlPsd 0;
BA_ "GenSigDataID" SG_ 289 BrkPedlPsdChks "0x38";
BA_ "GenSigFuncType" SG_ 289 BrkPedlPsdChks 15;
BA_ "GenSigSendType" SG_ 289 BrkPedlPsdChks 0;
BA_ "GenSigFuncType" SG_ 289 BrkPedlPsdCntr 16;
BA_ "GenSigSendType" SG_ 289 BrkPedlPsdCntr 0;
BA_ "GenSigSendType" SG_ 289 BrkPedlPsdQf 0;
BA_ "GenSigSendType" SG_ 289 ChassisObstclCrsModIncn 0;
BA_ "GenSigSendType" SG_ 289 HeiLimModIncn 0;
BA_ "GenSigStartValue" SG_ 289 PTALgtLimnlnd 1200;
BA_ "GenSigSendType" SG_ 289 PTALgtLimnlnd 0;
BA_ "GenSigSendType" SG_ 1173 BkpOfDstTrvld 0;
BA_ "GenSigSendType" SG_ 1173 CarTiGlb 0;
BA_ "GenSigSendType" SG_ 1173 TiAndDateIndcnDataValid 0;
BA_ "GenSigStartValue" SG_ 1173 TiAndDateIndcnDay 1;
BA_ "GenSigSendType" SG_ 1173 TiAndDateIndcnDay 0;
BA_ "GenSigSendType" SG_ 1173 TiAndDateIndcnHr1 0;
BA_ "GenSigSendType" SG_ 1173 TiAndDateIndcnMins1 0;
BA_ "GenSigStartValue" SG_ 1173 TiAndDateIndcnMth1 1;
BA_ "GenSigSendType" SG_ 1173 TiAndDateIndcnMth1 0;
BA_ "GenSigSendType" SG_ 1173 TiAndDateIndcnSec1 0;
BA_ "GenSigSendType" SG_ 1173 TiAndDateIndcnYr1 0;
BA_ "GenSigSendType" SG_ 1173 VehBattUSysU 0;
BA_ "GenSigStartValue" SG_ 1173 VehBattUSysUQf 1;
BA_ "GenSigSendType" SG_ 1173 VehBattUSysUQf 0;
BA_ "GenSigStartValue" SG_ 569 BattIRaw 32768;
BA_ "GenSigSendType" SG_ 569 BattIRaw 0;
BA_ "GenSigSendType" SG_ 569 BattRemainTimeToEmpty 0;
BA_ "GenSigSendType" SG_ 569 DrvModReq 0;
BA_ "GenSigSendType" SG_ 569 DrvrSeatSnsrSts 0;
BA_ "GenSigStartValue" SG_ 569 DrvrSeatSts 1;
BA_ "GenSigSendType" SG_ 569 DrvrSeatSts 0;
BA_ "GenSigSendType" SG_ 569 IAMSMod 0;
BA_ "GenSigSendType" SG_ 569 LockgCenStsLockSt 0;
BA_ "GenSigSendType" SG_ 569 LockgCenStsTrigSrc 0;
BA_ "GenSigSendType" SG_ 569 LockgCenStsUpdEve 0;
BA_ "GenSigDataID" SG_ 569 PtTqAtWhlFrntActChks "0x4E";
BA_ "GenSigFuncType" SG_ 569 PtTqAtWhlFrntActChks 15;
BA_ "GenSigSendType" SG_ 569 PtTqAtWhlFrntActChks 0;
BA_ "GenSigFuncType" SG_ 569 PtTqAtWhlFrntActCntr 16;
BA_ "GenSigSendType" SG_ 569 PtTqAtWhlFrntActCntr 0;
BA_ "GenSigSendType" SG_ 569 PtTqAtWhlFrntActPtTqAtAxleFrntAct 0;
BA_ "GenSigSendType" SG_ 569 PtTqAtWhlFrntActPtTqAtWhlFrntLeAct 0;
BA_ "GenSigSendType" SG_ 569 PtTqAtWhlFrntActPtTqAtWhlFrntRiAct 0;
BA_ "GenSigSendType" SG_ 569 PtTqAtWhlFrntActPtTqAtWhlsFrntQly 0;
BA_ "GenSigSendType" SG_ 569 PVMCSteerAst 0;
BA_ "GenSigStartValue" SG_ 625 AmbTRawAmbTVal 700;
BA_ "GenSigSendType" SG_ 625 AmbTRawAmbTVal 0;
BA_ "GenSigSendType" SG_ 625 AmbTRawQly 0;
BA_ "GenSigSendType" SG_ 625 DstEstimdToEmptyForDrvgElec 0;
BA_ "GenSigSendType" SG_ 625 DstEstimdToEmptyForDrvgElecPredTyp2 0;
BA_ "GenSigSendType" SG_ 625 DstEstimdToEmptyForDynElec 0;
BA_ "GenSigSendType" SG_ 625 DstToEmptyIndcdDstToEmpty1 0;
BA_ "GenSigSendType" SG_ 625 DstToEmptyIndcdDstToEmpty2 0;
BA_ "GenSigSendType" SG_ 625 DstToEmptyIndcdDstToEmpty3 0;
BA_ "GenSigStartValue" SG_ 131 DPAAgReqGroup1RtonAgReq 7200;
BA_ "GenSigStartValue" SG_ 131 DPAAgReqGroup1TrgtAg 7200;
BA_ "GenSigStartValue" SG_ 131 DPAAgReqGroup1VehAtaRtonlAg 7200;
BA_ "GenSigDataID" SG_ 131 DPAAgReqGroupChks "0xEEA";
BA_ "GenSigFuncType" SG_ 131 DPAAgReqGroupChks 15;
BA_ "GenSigFuncType" SG_ 131 DPAAgReqGroupCntr 16;
BA_ "GenSigDataID" SG_ 102 AbsCtrlActvChks "0xD06";
BA_ "GenSigFuncType" SG_ 102 AbsCtrlActvChks 15;
BA_ "GenSigSendType" SG_ 102 AbsCtrlActvChks 0;
BA_ "GenSigFuncType" SG_ 102 AbsCtrlActvCntr 16;
BA_ "GenSigSendType" SG_ 102 AbsCtrlActvCntr 0;
BA_ "GenSigSendType" SG_ 102 AbsCtrlActvCtrlSts1 0;
BA_ "GenSigSendType" SG_ 102 BrkTracCtrlActv 0;
BA_ "GenSigDataID" SG_ 102 GVMCPrpsnTqDistbnReqAtAxleReChks "0x1A7B";
BA_ "GenSigFuncType" SG_ 102 GVMCPrpsnTqDistbnReqAtAxleReChks 15;
BA_ "GenSigSendType" SG_ 102 GVMCPrpsnTqDistbnReqAtAxleReChks 0;
BA_ "GenSigFuncType" SG_ 102 GVMCPrpsnTqDistbnReqAtAxleReCntr 16;
BA_ "GenSigSendType" SG_ 102 GVMCPrpsnTqDistbnReqAtAxleReCntr 0;
BA_ "GenSigSendType" SG_ 102 GVMCPrpsnTqDistbnReqAtAxleReCtrlMod 0;
BA_ "GenSigStartValue" SG_ 102 GVMCPrpsnTqDistbnReqAtAxleReDistReq 100000;
BA_ "GenSigSendType" SG_ 102 GVMCPrpsnTqDistbnReqAtAxleReDistReq 0;
BA_ "GenSigSendType" SG_ 102 GVMCSuspDampgCtrlReqGVMCDampgCtrlReqFL 0;
BA_ "GenSigSendType" SG_ 102 GVMCSuspDampgCtrlReqGVMCDampgCtrlReqFR 0;
BA_ "GenSigSendType" SG_ 102 GVMCSuspDampgCtrlReqGVMCDampgCtrlReqRL 0;
BA_ "GenSigSendType" SG_ 102 GVMCSuspDampgCtrlReqGVMCDampgCtrlReqRR 0;
BA_ "GenSigSendType" SG_ 102 GVMCSuspDampgCtrlReqGVMCSuspDampgCtrlMod 0;
BA_ "GenSigSendType" SG_ 102 GVMCSuspDampgCtrlReqGVMCSuspDampgModReq 0;
BA_ "GenSigSendType" SG_ 102 PVMCSuspHeiCtrlReqGVMCSuspPosnCtrlMod 0;
BA_ "GenSigSendType" SG_ 102 PVMCSuspHeiCtrlReqGVMCSuspPosnFLReq 0;
BA_ "GenSigSendType" SG_ 102 PVMCSuspHeiCtrlReqGVMCSuspPosnFRReq 0;
BA_ "GenSigSendType" SG_ 102 PVMCSuspHeiCtrlReqGVMCSuspPosnModReq 0;
BA_ "GenSigSendType" SG_ 102 PVMCSuspHeiCtrlReqGVMCSuspPosnRLReq 0;
BA_ "GenSigSendType" SG_ 102 PVMCSuspHeiCtrlReqGVMCSuspPosnRRReq 0;
BA_ "GenSigSendType" SG_ 102 PVMCVehCtrlSts2ActrTarFctSts 0;
BA_ "GenSigSendType" SG_ 102 PVMCVehCtrlSts2BbWBackUpFctSts 0;
BA_ "GenSigSendType" SG_ 102 PVMCVehCtrlSts2BrkDiscClngFctSts 0;
BA_ "GenSigSendType" SG_ 102 PVMCVehCtrlSts2BrkTqDeltaFctSts 0;
BA_ "GenSigDataID" SG_ 102 PVMCVehCtrlSts2Chks "0x1ACA";
BA_ "GenSigFuncType" SG_ 102 PVMCVehCtrlSts2Chks 15;
BA_ "GenSigSendType" SG_ 102 PVMCVehCtrlSts2Chks 0;
BA_ "GenSigFuncType" SG_ 102 PVMCVehCtrlSts2Cntr 16;
BA_ "GenSigSendType" SG_ 102 PVMCVehCtrlSts2Cntr 0;
BA_ "GenSigSendType" SG_ 102 PVMCVehCtrlSts2CrabMovgFctSts 0;
BA_ "GenSigSendType" SG_ 102 PVMCVehCtrlSts2DecelReqActrSts 0;
BA_ "GenSigSendType" SG_ 102 PVMCVehCtrlSts2FloatingDrvgFctSts 0;
BA_ "GenSigSendType" SG_ 102 PVMCVehCtrlSts2LowSpdStrFctSts 0;
BA_ "GenSigSendType" SG_ 102 PVMCVehCtrlSts2SbWBackUpLatFctSts 0;
BA_ "GenSigSendType" SG_ 102 PVMCVehCtrlSts2SbWBackUpLgtFctSts 0;
BA_ "GenSigSendType" SG_ 102 PVMCVehCtrlSts2TankTurnFctSts 0;
BA_ "GenSigSendType" SG_ 102 PVMCVehCtrlSts2VDSWFctSts 0;
BA_ "GenSigSendType" SG_ 102 PVMCVehCtrlSts2ViolentModFctSts 0;
BA_ "GenSigSendType" SG_ 102 VehArbtSpdMax 0;
BA_ "GenSigSendType" SG_ 102 VehSpdLimSrc 0;
BA_ "GenSigDataID" SG_ 102 WhlSpdCircumlFrntChks "0x6F";
BA_ "GenSigFuncType" SG_ 102 WhlSpdCircumlFrntChks 15;
BA_ "GenSigSendType" SG_ 102 WhlSpdCircumlFrntChks 0;
BA_ "GenSigFuncType" SG_ 102 WhlSpdCircumlFrntCntr 16;
BA_ "GenSigSendType" SG_ 102 WhlSpdCircumlFrntCntr 0;
BA_ "GenSigSendType" SG_ 102 WhlSpdCircumlFrntLe 0;
BA_ "GenSigStartValue" SG_ 102 WhlSpdCircumlFrntLeQf 1;
BA_ "GenSigSendType" SG_ 102 WhlSpdCircumlFrntLeQf 0;
BA_ "GenSigStartValue" SG_ 102 WhlSpdCircumlFrntRiQf 1;
BA_ "GenSigSendType" SG_ 102 WhlSpdCircumlFrntRiQf 0;
BA_ "GenSigSendType" SG_ 102 WhlSpdCircumlFrntWhlSpdCircumlFrntRi 0;
BA_ "GenSigDataID" SG_ 102 WhlSpdCircumlReChks "0x7C";
BA_ "GenSigFuncType" SG_ 102 WhlSpdCircumlReChks 15;
BA_ "GenSigSendType" SG_ 102 WhlSpdCircumlReChks 0;
BA_ "GenSigFuncType" SG_ 102 WhlSpdCircumlReCntr 16;
BA_ "GenSigSendType" SG_ 102 WhlSpdCircumlReCntr 0;
BA_ "GenSigSendType" SG_ 102 WhlSpdCircumlReLe 0;
BA_ "GenSigStartValue" SG_ 102 WhlSpdCircumlReLeQf 1;
BA_ "GenSigSendType" SG_ 102 WhlSpdCircumlReLeQf 0;
BA_ "GenSigSendType" SG_ 102 WhlSpdCircumlReRi 0;
BA_ "GenSigStartValue" SG_ 102 WhlSpdCircumlReRiQf 1;
BA_ "GenSigSendType" SG_ 102 WhlSpdCircumlReRiQf 0;
BA_ "GenSigSendType" SG_ 549 VehCfgPrmBlkIDBytePosn1 1;
BA_ "GenSigSendType" SG_ 549 VehCfgPrmCCPBytePosn2 1;
BA_ "GenSigSendType" SG_ 549 VehCfgPrmCCPBytePosn3 1;
BA_ "GenSigSendType" SG_ 549 VehCfgPrmCCPBytePosn4 1;
BA_ "GenSigSendType" SG_ 549 VehCfgPrmCCPBytePosn5 1;
BA_ "GenSigSendType" SG_ 549 VehCfgPrmCCPBytePosn6 1;
BA_ "GenSigSendType" SG_ 549 VehCfgPrmCCPBytePosn7 1;
BA_ "GenSigSendType" SG_ 549 VehCfgPrmCCPBytePosn8 1;
BA_ "GenSigSendType" SG_ 549 VehCfgPrmExt2BlkIDBytePosn1 1;
BA_ "GenSigSendType" SG_ 549 VehCfgPrmExt2CCPBytePosn2 1;
BA_ "GenSigSendType" SG_ 549 VehCfgPrmExt2CCPBytePosn3 1;
BA_ "GenSigSendType" SG_ 549 VehCfgPrmExt2CCPBytePosn4 1;
BA_ "GenSigSendType" SG_ 549 VehCfgPrmExt2CCPBytePosn5 1;
BA_ "GenSigSendType" SG_ 549 VehCfgPrmExt2CCPBytePosn6 1;
BA_ "GenSigSendType" SG_ 549 VehCfgPrmExt2CCPBytePosn7 1;
BA_ "GenSigSendType" SG_ 549 VehCfgPrmExt2CCPBytePosn8 1;
BA_ "GenSigSendType" SG_ 549 VehCfgPrmExtBlkIDBytePosn1 1;
BA_ "GenSigSendType" SG_ 549 VehCfgPrmExtCCPBytePosn2 1;
BA_ "GenSigSendType" SG_ 549 VehCfgPrmExtCCPBytePosn3 1;
BA_ "GenSigSendType" SG_ 549 VehCfgPrmExtCCPBytePosn4 1;
BA_ "GenSigSendType" SG_ 549 VehCfgPrmExtCCPBytePosn5 1;
BA_ "GenSigSendType" SG_ 549 VehCfgPrmExtCCPBytePosn6 1;
BA_ "GenSigSendType" SG_ 549 VehCfgPrmExtCCPBytePosn7 1;
BA_ "GenSigSendType" SG_ 549 VehCfgPrmExtCCPBytePosn8 1;
BA_ "GenSigStartValue" SG_ 752 CmptmtTFrntCmptmtTFrnt 600;
BA_ "GenSigSendType" SG_ 752 CmptmtTFrntCmptmtTFrnt 0;
BA_ "GenSigSendType" SG_ 752 CmptmtTFrntFanForCmptmtTRunng 0;
BA_ "GenSigStartValue" SG_ 752 CmptmtTFrntQf 1;
BA_ "GenSigSendType" SG_ 752 CmptmtTFrntQf 0;
BA_ "GenSigSendType" SG_ 752 LiBattInPWLock 0;
BA_ "GenSigSendType" SG_ 752 RlyPwrDistbnCmd1WdIgnRlyCmd 0;
BA_ "GenSigDataID" SG_ 752 ULoWarnLvPwrErrChks "0x1BE1";
BA_ "GenSigFuncType" SG_ 752 ULoWarnLvPwrErrChks 15;
BA_ "GenSigSendType" SG_ 752 ULoWarnLvPwrErrChks 0;
BA_ "GenSigFuncType" SG_ 752 ULoWarnLvPwrErrCntr 16;
BA_ "GenSigSendType" SG_ 752 ULoWarnLvPwrErrCntr 0;
BA_ "GenSigSendType" SG_ 752 ULoWarnLvPwrErrLVPwrSplyErrSts 0;
BA_ "GenSigSendType" SG_ 752 ULoWarnLvPwrErrULoWarn 0;
BA_ "GenSigSendType" SG_ 1281 WakeUpReasonsforZCUDM 0;
BA_ "GenSigSendType" SG_ 1345 VFCVectorZCUDMBlockID 0;
BA_ "GenSigSendType" SG_ 1345 VFCVectorZCUDMVFCid0 0;
BA_ "GenSigSendType" SG_ 1345 VFCVectorZCUDMVFCid1 0;
BA_ "GenSigSendType" SG_ 1345 VFCVectorZCUDMVFCid10 0;
BA_ "GenSigSendType" SG_ 1345 VFCVectorZCUDMVFCid11 0;
BA_ "GenSigSendType" SG_ 1345 VFCVectorZCUDMVFCid12 0;
BA_ "GenSigSendType" SG_ 1345 VFCVectorZCUDMVFCid13 0;
BA_ "GenSigSendType" SG_ 1345 VFCVectorZCUDMVFCid14 0;
BA_ "GenSigSendType" SG_ 1345 VFCVectorZCUDMVFCid15 0;
BA_ "GenSigSendType" SG_ 1345 VFCVectorZCUDMVFCid16 0;
BA_ "GenSigSendType" SG_ 1345 VFCVectorZCUDMVFCid17 0;
BA_ "GenSigSendType" SG_ 1345 VFCVectorZCUDMVFCid18 0;
BA_ "GenSigSendType" SG_ 1345 VFCVectorZCUDMVFCid19 0;
BA_ "GenSigSendType" SG_ 1345 VFCVectorZCUDMVFCid2 0;
BA_ "GenSigSendType" SG_ 1345 VFCVectorZCUDMVFCid20 0;
BA_ "GenSigSendType" SG_ 1345 VFCVectorZCUDMVFCid21 0;
BA_ "GenSigSendType" SG_ 1345 VFCVectorZCUDMVFCid22 0;
BA_ "GenSigSendType" SG_ 1345 VFCVectorZCUDMVFCid23 0;
BA_ "GenSigSendType" SG_ 1345 VFCVectorZCUDMVFCid24 0;
BA_ "GenSigSendType" SG_ 1345 VFCVectorZCUDMVFCid25 0;
BA_ "GenSigSendType" SG_ 1345 VFCVectorZCUDMVFCid26 0;
BA_ "GenSigSendType" SG_ 1345 VFCVectorZCUDMVFCid27 0;
BA_ "GenSigSendType" SG_ 1345 VFCVectorZCUDMVFCid28 0;
BA_ "GenSigSendType" SG_ 1345 VFCVectorZCUDMVFCid29 0;
BA_ "GenSigSendType" SG_ 1345 VFCVectorZCUDMVFCid3 0;
BA_ "GenSigSendType" SG_ 1345 VFCVectorZCUDMVFCid30 0;
BA_ "GenSigSendType" SG_ 1345 VFCVectorZCUDMVFCid31 0;
BA_ "GenSigSendType" SG_ 1345 VFCVectorZCUDMVFCid32 0;
BA_ "GenSigSendType" SG_ 1345 VFCVectorZCUDMVFCid33 0;
BA_ "GenSigSendType" SG_ 1345 VFCVectorZCUDMVFCid34 0;
BA_ "GenSigSendType" SG_ 1345 VFCVectorZCUDMVFCid35 0;
BA_ "GenSigSendType" SG_ 1345 VFCVectorZCUDMVFCid36 0;
BA_ "GenSigSendType" SG_ 1345 VFCVectorZCUDMVFCid37 0;
BA_ "GenSigSendType" SG_ 1345 VFCVectorZCUDMVFCid38 0;
BA_ "GenSigSendType" SG_ 1345 VFCVectorZCUDMVFCid39 0;
BA_ "GenSigSendType" SG_ 1345 VFCVectorZCUDMVFCid4 0;
BA_ "GenSigSendType" SG_ 1345 VFCVectorZCUDMVFCid40 0;
BA_ "GenSigSendType" SG_ 1345 VFCVectorZCUDMVFCid41 0;
BA_ "GenSigSendType" SG_ 1345 VFCVectorZCUDMVFCid42 0;
BA_ "GenSigSendType" SG_ 1345 VFCVectorZCUDMVFCid43 0;
BA_ "GenSigSendType" SG_ 1345 VFCVectorZCUDMVFCid44 0;
BA_ "GenSigSendType" SG_ 1345 VFCVectorZCUDMVFCid45 0;
BA_ "GenSigSendType" SG_ 1345 VFCVectorZCUDMVFCid46 0;
BA_ "GenSigSendType" SG_ 1345 VFCVectorZCUDMVFCid47 0;
BA_ "GenSigSendType" SG_ 1345 VFCVectorZCUDMVFCid48 0;
BA_ "GenSigSendType" SG_ 1345 VFCVectorZCUDMVFCid49 0;
BA_ "GenSigSendType" SG_ 1345 VFCVectorZCUDMVFCid5 0;
BA_ "GenSigSendType" SG_ 1345 VFCVectorZCUDMVFCid50 0;
BA_ "GenSigSendType" SG_ 1345 VFCVectorZCUDMVFCid51 0;
BA_ "GenSigSendType" SG_ 1345 VFCVectorZCUDMVFCid52 0;
BA_ "GenSigSendType" SG_ 1345 VFCVectorZCUDMVFCid53 0;
BA_ "GenSigSendType" SG_ 1345 VFCVectorZCUDMVFCid54 0;
BA_ "GenSigSendType" SG_ 1345 VFCVectorZCUDMVFCid55 0;
BA_ "GenSigSendType" SG_ 1345 VFCVectorZCUDMVFCid56 0;
BA_ "GenSigSendType" SG_ 1345 VFCVectorZCUDMVFCid57 0;
BA_ "GenSigSendType" SG_ 1345 VFCVectorZCUDMVFCid58 0;
BA_ "GenSigSendType" SG_ 1345 VFCVectorZCUDMVFCid59 0;
BA_ "GenSigSendType" SG_ 1345 VFCVectorZCUDMVFCid6 0;
BA_ "GenSigSendType" SG_ 1345 VFCVectorZCUDMVFCid60 0;
BA_ "GenSigSendType" SG_ 1345 VFCVectorZCUDMVFCid61 0;
BA_ "GenSigSendType" SG_ 1345 VFCVectorZCUDMVFCid7 0;
BA_ "GenSigSendType" SG_ 1345 VFCVectorZCUDMVFCid8 0;
BA_ "GenSigSendType" SG_ 1345 VFCVectorZCUDMVFCid9 0;
BA_ "GenSigSendType" SG_ 535 CDCModlndcnForFAS 0;
BA_ "GenSigSendType" SG_ 535 FASActFAryFL 0;
BA_ "GenSigSendType" SG_ 535 FASActFAryFR 0;
BA_ "GenSigSendType" SG_ 535 FASActFAryRL 0;
BA_ "GenSigSendType" SG_ 535 FASActFAryRR 0;
BA_ "GenSigSendType" SG_ 535 FASChassisObstclCrsModIncn 0;
BA_ "GenSigSendType" SG_ 535 FASDrvModPrsnlAdjmtDamprCmftSts 0;
BA_ "GenSigSendType" SG_ 535 FASDrvModPrsnlAdjmtDamprHardSts 0;
BA_ "GenSigSendType" SG_ 535 FASDrvModPrsnlAdjmtDamprMedSts 0;
BA_ "GenSigSendType" SG_ 535 FASDrvModPrsnlAdjmtDamprSts_Resv1 0;
BA_ "GenSigSendType" SG_ 535 FASDrvModPrsnlAdjmtDamprSts_Resv2 0;
BA_ "GenSigSendType" SG_ 535 FASDrvModPrsnlAdjmtSuspLvlHL1Sts 0;
BA_ "GenSigSendType" SG_ 535 FASDrvModPrsnlAdjmtSuspLvlHL2Sts 0;
BA_ "GenSigSendType" SG_ 535 FASDrvModPrsnlAdjmtSuspLvlLL1Sts 0;
BA_ "GenSigSendType" SG_ 535 FASDrvModPrsnlAdjmtSuspLvlLL2Sts 0;
BA_ "GenSigSendType" SG_ 535 FASDrvModPrsnlAdjmtSuspLvlNRHSts 0;
BA_ "GenSigSendType" SG_ 535 FASEasyLoadModlndcn 0;
BA_ "GenSigSendType" SG_ 535 FASHeiLimModIncn 0;
BA_ "GenSigStartValue" SG_ 535 FASLvlgDirMovmtindcr 1;
BA_ "GenSigSendType" SG_ 535 FASLvlgDirMovmtindcr 0;
BA_ "GenSigStartValue" SG_ 535 FASLvlgFctAvl 1;
BA_ "GenSigSendType" SG_ 535 FASLvlgFctAvl 0;
BA_ "GenSigStartValue" SG_ 535 FASLvlgFctSts 3;
BA_ "GenSigSendType" SG_ 535 FASLvlgFctSts 0;
BA_ "GenSigSendType" SG_ 535 FullActvSuspFailrStsSuspFailrSts 0;
BA_ "GenSigSendType" SG_ 535 FullActvSuspFailrStsSuspFailrStsChks 0;
BA_ "GenSigSendType" SG_ 535 FullActvSuspFailrStsSuspFailrStsCntr 0;
BA_ "GenSigStartValue" SG_ 535 FullActvSuspFailrStsSuspFailrStsTypQf 1;
BA_ "GenSigSendType" SG_ 535 FullActvSuspFailrStsSuspFailrStsTypQf 0;
BA_ "GenSigSendType" SG_ 535 FullActvSuspHeilvlindcn 0;
BA_ "GenSigSendType" SG_ 535 FullActvSuspStabyCritFailrDetdChks 0;
BA_ "GenSigSendType" SG_ 535 FullActvSuspStabyCritFailrDetdCntr 0;
BA_ "GenSigSendType" SG_ 535 FullActvSuspStabyCritFailrDetdSts 0;
BA_ "GenSigSendType" SG_ 101 FASBodyHei 0;
BA_ "GenSigSendType" SG_ 101 FullActvSuspPosnVertLeChks 0;
BA_ "GenSigSendType" SG_ 101 FullActvSuspPosnVertLeFrnt 0;
BA_ "GenSigStartValue" SG_ 101 FullActvSuspPosnVertLeFrntQf 1;
BA_ "GenSigSendType" SG_ 101 FullActvSuspPosnVertLeFrntQf 0;
BA_ "GenSigSendType" SG_ 101 FullActvSuspPosnVertLeRe 0;
BA_ "GenSigStartValue" SG_ 101 FullActvSuspPosnVertLeReQf 1;
BA_ "GenSigSendType" SG_ 101 FullActvSuspPosnVertLeReQf 0;
BA_ "GenSigSendType" SG_ 101 FullActvSuspPosnVertRiChks 0;
BA_ "GenSigSendType" SG_ 101 FullActvSuspPosnVertRiFrnt 0;
BA_ "GenSigStartValue" SG_ 101 FullActvSuspPosnVertRiFrntQf 1;
BA_ "GenSigSendType" SG_ 101 FullActvSuspPosnVertRiFrntQf 0;
BA_ "GenSigSendType" SG_ 101 FullActvSuspPosnVertRiRe 0;
BA_ "GenSigStartValue" SG_ 101 FullActvSuspPosnVertRiReQf 1;
BA_ "GenSigSendType" SG_ 101 FullActvSuspPosnVertRiReQf 0;
BA_ "GenSigSendType" SG_ 101 ZCUTForceMaxFrntLe 0;
BA_ "GenSigSendType" SG_ 101 ZCUTForceMaxFrntRi 0;
BA_ "GenSigSendType" SG_ 101 ZCUTForceMaxReLe 0;
BA_ "GenSigSendType" SG_ 101 ZCUTForceMaxReRi 0;
BA_ "GenSigSendType" SG_ 101 ZCUTForceRealFrntLe 0;
BA_ "GenSigSendType" SG_ 101 ZCUTForceRealFrntRi 0;
BA_ "GenSigSendType" SG_ 101 ZCUTForceRealReLe 0;
BA_ "GenSigSendType" SG_ 101 ZCUTForceRealReRi 0;
BA_ "GenSigSendType" SG_ 101 ZCUTToVMCAvl 0;
BA_ "GenSigSendType" SG_ 266 FasCritPwrReq 0;
BA_ "GenSigSendType" SG_ 266 FasPwrAct 0;
BA_ "GenSigSendType" SG_ 266 FasPwrReq 0;
BA_ "GenSigSendType" SG_ 1282 WakeUpReasonsforZCUT 0;
BA_ "GenSigSendType" SG_ 1346 VFCVectorZCUTBlockID 0;
BA_ "GenSigSendType" SG_ 1346 VFCVectorZCUTVFCid0 0;
BA_ "GenSigSendType" SG_ 1346 VFCVectorZCUTVFCid1 0;
BA_ "GenSigSendType" SG_ 1346 VFCVectorZCUTVFCid10 0;
BA_ "GenSigSendType" SG_ 1346 VFCVectorZCUTVFCid11 0;
BA_ "GenSigSendType" SG_ 1346 VFCVectorZCUTVFCid12 0;
BA_ "GenSigSendType" SG_ 1346 VFCVectorZCUTVFCid13 0;
BA_ "GenSigSendType" SG_ 1346 VFCVectorZCUTVFCid14 0;
BA_ "GenSigSendType" SG_ 1346 VFCVectorZCUTVFCid15 0;
BA_ "GenSigSendType" SG_ 1346 VFCVectorZCUTVFCid16 0;
BA_ "GenSigSendType" SG_ 1346 VFCVectorZCUTVFCid17 0;
BA_ "GenSigSendType" SG_ 1346 VFCVectorZCUTVFCid18 0;
BA_ "GenSigSendType" SG_ 1346 VFCVectorZCUTVFCid19 0;
BA_ "GenSigSendType" SG_ 1346 VFCVectorZCUTVFCid2 0;
BA_ "GenSigSendType" SG_ 1346 VFCVectorZCUTVFCid20 0;
BA_ "GenSigSendType" SG_ 1346 VFCVectorZCUTVFCid21 0;
BA_ "GenSigSendType" SG_ 1346 VFCVectorZCUTVFCid22 0;
BA_ "GenSigSendType" SG_ 1346 VFCVectorZCUTVFCid23 0;
BA_ "GenSigSendType" SG_ 1346 VFCVectorZCUTVFCid24 0;
BA_ "GenSigSendType" SG_ 1346 VFCVectorZCUTVFCid25 0;
BA_ "GenSigSendType" SG_ 1346 VFCVectorZCUTVFCid26 0;
BA_ "GenSigSendType" SG_ 1346 VFCVectorZCUTVFCid27 0;
BA_ "GenSigSendType" SG_ 1346 VFCVectorZCUTVFCid28 0;
BA_ "GenSigSendType" SG_ 1346 VFCVectorZCUTVFCid29 0;
BA_ "GenSigSendType" SG_ 1346 VFCVectorZCUTVFCid3 0;
BA_ "GenSigSendType" SG_ 1346 VFCVectorZCUTVFCid30 0;
BA_ "GenSigSendType" SG_ 1346 VFCVectorZCUTVFCid31 0;
BA_ "GenSigSendType" SG_ 1346 VFCVectorZCUTVFCid32 0;
BA_ "GenSigSendType" SG_ 1346 VFCVectorZCUTVFCid33 0;
BA_ "GenSigSendType" SG_ 1346 VFCVectorZCUTVFCid34 0;
BA_ "GenSigSendType" SG_ 1346 VFCVectorZCUTVFCid35 0;
BA_ "GenSigSendType" SG_ 1346 VFCVectorZCUTVFCid36 0;
BA_ "GenSigSendType" SG_ 1346 VFCVectorZCUTVFCid37 0;
BA_ "GenSigSendType" SG_ 1346 VFCVectorZCUTVFCid38 0;
BA_ "GenSigSendType" SG_ 1346 VFCVectorZCUTVFCid39 0;
BA_ "GenSigSendType" SG_ 1346 VFCVectorZCUTVFCid4 0;
BA_ "GenSigSendType" SG_ 1346 VFCVectorZCUTVFCid40 0;
BA_ "GenSigSendType" SG_ 1346 VFCVectorZCUTVFCid41 0;
BA_ "GenSigSendType" SG_ 1346 VFCVectorZCUTVFCid42 0;
BA_ "GenSigSendType" SG_ 1346 VFCVectorZCUTVFCid43 0;
BA_ "GenSigSendType" SG_ 1346 VFCVectorZCUTVFCid44 0;
BA_ "GenSigSendType" SG_ 1346 VFCVectorZCUTVFCid45 0;
BA_ "GenSigSendType" SG_ 1346 VFCVectorZCUTVFCid46 0;
BA_ "GenSigSendType" SG_ 1346 VFCVectorZCUTVFCid47 0;
BA_ "GenSigSendType" SG_ 1346 VFCVectorZCUTVFCid48 0;
BA_ "GenSigSendType" SG_ 1346 VFCVectorZCUTVFCid49 0;
BA_ "GenSigSendType" SG_ 1346 VFCVectorZCUTVFCid5 0;
BA_ "GenSigSendType" SG_ 1346 VFCVectorZCUTVFCid50 0;
BA_ "GenSigSendType" SG_ 1346 VFCVectorZCUTVFCid51 0;
BA_ "GenSigSendType" SG_ 1346 VFCVectorZCUTVFCid52 0;
BA_ "GenSigSendType" SG_ 1346 VFCVectorZCUTVFCid53 0;
BA_ "GenSigSendType" SG_ 1346 VFCVectorZCUTVFCid54 0;
BA_ "GenSigSendType" SG_ 1346 VFCVectorZCUTVFCid55 0;
BA_ "GenSigSendType" SG_ 1346 VFCVectorZCUTVFCid56 0;
BA_ "GenSigSendType" SG_ 1346 VFCVectorZCUTVFCid57 0;
BA_ "GenSigSendType" SG_ 1346 VFCVectorZCUTVFCid58 0;
BA_ "GenSigSendType" SG_ 1346 VFCVectorZCUTVFCid59 0;
BA_ "GenSigSendType" SG_ 1346 VFCVectorZCUTVFCid6 0;
BA_ "GenSigSendType" SG_ 1346 VFCVectorZCUTVFCid60 0;
BA_ "GenSigSendType" SG_ 1346 VFCVectorZCUTVFCid61 0;
BA_ "GenSigSendType" SG_ 1346 VFCVectorZCUTVFCid7 0;
BA_ "GenSigSendType" SG_ 1346 VFCVectorZCUTVFCid8 0;
BA_ "GenSigSendType" SG_ 1346 VFCVectorZCUTVFCid9 0;
VAL_ 85 EscStEscSt 4 "EscSt1_UsrOff" 3 "EscSt1_PrmntErr" 2 "EscSt1_TmpErr" 1 "EscSt1_Ok" 0 "EscSt1_Inin";
VAL_ 85 GearLvrIndcn 7 "GearLvrIndcn2_Undefd" 6 "GearLvrIndcn2_Resd2" 5 "GearLvrIndcn2_Resd1" 4 "GearLvrIndcn2_ManModeIndcn" 3 "GearLvrIndcn2_DrvIndcn" 2 "GearLvrIndcn2_NeutIndcn" 1 "GearLvrIndcn2_RvsIndcn" 0 "GearLvrIndcn2_ParkIndcn";
VAL_ 85 GVMCPrpsnTqDistReqCtrlMod 1 "Boolean_TRUE" 0 "Boolean_FALSE";
VAL_ 85 GVMCSteerWhlAgReqFrntSteerWhlCtrlSts 3 "SteerWhlCtrlSts_Reserved" 2 "SteerWhlCtrlSts_TqRequest" 1 "SteerWhlCtrlSts_AngleRequest" 0 "SteerWhlCtrlSts_NoRequest";
VAL_ 85 GVMCVehCtrlrStsCtrlrSts 15 "GVMCVehCtrlrSts2_Resd" 14 "GVMCVehCtrlrSts2_GVMCOff" 13 "GVMCVehCtrlrSts2_EnterToBoth11And12" 12 "GVMCVehCtrlrSts2_NotAvailableForCrabMov_LowSpdStr_TankTurn" 11 "GVMCVehCtrlrSts2_NotAvailableForPilot" 10 "GVMCVehCtrlrSts2_EnterToBoth8And9DegradationStatus" 9 "GVMCVehCtrlrSts2_SuspensionDegrade" 8 "GVMCVehCtrlrSts2_VMCYawTorqueControlDegraded" 7 "GVMCVehCtrlrSts2_BrakeTorqueControlDisabledWithError" 6 "GVMCVehCtrlrSts2_TorqueDistributionDisabledWithError" 5 "GVMCVehCtrlrSts2_RWSDisabledWithError" 4 "GVMCVehCtrlrSts2_DisabledWithError" 3 "GVMCVehCtrlrSts2_RWSDisabled" 2 "GVMCVehCtrlrSts2_Disabled" 1 "GVMCVehCtrlrSts2_Enabled" 0 "GVMCVehCtrlrSts2_Init";
VAL_ 85 GVMCVehVActQf 3 "GenQf1_AccurData" 2 "GenQf1_DataAccurNotWithinSpcn" 1 "GenQf1_TmpUndefdData" 0 "GenQf1_UndefindDataAccur";
VAL_ 85 GVMCYawRateCOGActQf 3 "GenQf1_AccurData" 2 "GenQf1_DataAccurNotWithinSpcn" 1 "GenQf1_TmpUndefdData" 0 "GenQf1_UndefindDataAccur";
VAL_ 85 LatCtrlReqSafeLatCtrlModReq 15 "LatCtrlMod5_HPA" 14 "LatCtrlMod5_RPA" 13 "LatCtrlMod5_APA" 12 "LatCtrlMod5_SHWA" 11 "LatCtrlMod5_E2E" 10 "LatCtrlMod5_Reserved1" 9 "LatCtrlMod5_EmgyManvAssi" 8 "LatCtrlMod5_DsrTrlrStaby" 7 "LatCtrlMod5_DsrMueSplit" 6 "LatCtrlMod5_DsrOversteer" 5 "LatCtrlMod5_SteerAssc" 4 "LatCtrlMod5_SftyLaneKeepAid" 3 "LatCtrlMod5_EmgyLaneKeepAidForStat" 2 "LatCtrlMod5_EmgyLaneKeepAidForObjRe" 1 "LatCtrlMod5_HighWayAssist" 0 "LatCtrlMod5_NoReq";
VAL_ 85 LatCtrlReqSafeSteerWhlHptcWarnReq 1 "OnOff1_On" 0 "OnOff1_Off";
VAL_ 85 SteerWhlSnsrQf 3 "GenQf1_AccurData" 2 "GenQf1_DataAccurNotWithinSpcn" 1 "GenQf1_TmpUndefdData" 0 "GenQf1_UndefindDataAccur";
VAL_ 85 VehModMngtGlbSafe1CarModSts1 5 "CarModSts1_CarModDyno" 3 "CarModSts1_CarModCrash" 2 "CarModSts1_CarModFcy" 1 "CarModSts1_CarModTrnsp" 0 "CarModSts1_CarModNorm";
VAL_ 85 VehModMngtGlbSafe1FltEgyCnsWdSts 1 "FltEgyCns1_Flt" 0 "FltEgyCns1_NoFlt";
VAL_ 85 VehModMngtGlbSafe1UsgModSts 13 "UsgModSts1_UsgModDrvg" 11 "UsgModSts1_UsgModActv" 2 "UsgModSts1_UsgModCnvinc" 1 "UsgModSts1_UsgModInActv" 0 "UsgModSts1_UsgModAbdnd";
VAL_ 85 VehMtnStVehMtnSt 7 "VehMtnSt2_RollgBackwVal2" 6 "VehMtnSt2_RollgBackwVal1" 5 "VehMtnSt2_RollgFwdVal2" 4 "VehMtnSt2_RollgFwdVal1" 3 "VehMtnSt2_StandStillVal3" 2 "VehMtnSt2_StandStillVal2" 1 "VehMtnSt2_StandStillVal1" 0 "VehMtnSt2_Ukwn";
VAL_ 85 VehSpdLgtQf 3 "GenQf1_AccurData" 2 "GenQf1_DataAccurNotWithinSpcn" 1 "GenQf1_TmpUndefdData" 0 "GenQf1_UndefindDataAccur";
VAL_ 85 WhlFastSpdSafeQF 3 "GenQf1_AccurData" 2 "GenQf1_DataAccurNotWithinSpcn" 1 "GenQf1_TmpUndefdData" 0 "GenQf1_UndefindDataAccur";
VAL_ 339 DrvrGearShiftDirReq1DwnDwnTipAut 1 "NotActvActv1_Actv" 0 "NotActvActv1_NotActv";
VAL_ 339 DrvrGearShiftDirReq1DwnTipAut 1 "DwnTipAut1_DwnTipAutActv" 0 "DwnTipAut1_DwnTipAutNotActv";
VAL_ 339 DrvrGearShiftDirReq1PosnAut 1 "PosnAut_PosnAutActv" 0 "PosnAut_PosnAutNotActv";
VAL_ 339 DrvrGearShiftDirReq1UpTipAut 1 "UpTipAut1_UpTipAutActv" 0 "UpTipAut1_UpTipAutNotActv";
VAL_ 339 DrvrGearShiftDirReq1UpUpTipAut 1 "NotActvActv1_Actv" 0 "NotActvActv1_NotActv";
VAL_ 339 DrvrGearShiftDirReq2DwnDwnTipAut 1 "NotActvActv1_Actv" 0 "NotActvActv1_NotActv";
VAL_ 339 DrvrGearShiftDirReq2DwnTipAut 1 "DwnTipAut1_DwnTipAutActv" 0 "DwnTipAut1_DwnTipAutNotActv";
VAL_ 339 DrvrGearShiftDirReq2PosnAut 1 "PosnAut_PosnAutActv" 0 "PosnAut_PosnAutNotActv";
VAL_ 339 DrvrGearShiftDirReq2UpTipAut 1 "UpTipAut1_UpTipAutActv" 0 "UpTipAut1_UpTipAutNotActv";
VAL_ 339 DrvrGearShiftDirReq2UpUpTipAut 1 "NotActvActv1_Actv" 0 "NotActvActv1_NotActv";
VAL_ 339 RWASteerLockReqCommand 3 "SteerLockReqCmd_SteerResdCmd" 2 "SteerLockReqCmd_SteerLockCmd" 1 "SteerLockReqCmd_SteerUnlckCmd" 0 "SteerLockReqCmd_SteerIdleCmd";
VAL_ 339 SteerEmergCtrlSwt 1 "YesNo2_Yes" 0 "YesNo2_No";
VAL_ 339 SteerRatModReq 18 "SteerRatModReq_Resd" 17 "SteerRatModReq_DynoMod17" 16 "SteerRatModReq_DynoMod16" 15 "SteerRatModReq_DynoMod15" 14 "SteerRatModReq_DynoMod14" 13 "SteerRatModReq_DynoMod13" 12 "SteerRatModReq_DynoMod12" 11 "SteerRatModReq_DynoMod11" 10 "SteerRatModReq_DynoMod10" 9 "SteerRatModReq_DynoMod9" 8 "SteerRatModReq_DynoMod8" 7 "SteerRatModReq_DynoMod7" 6 "SteerRatModReq_DynoMod6" 5 "SteerRatModReq_DynoMod5" 4 "SteerRatModReq_DynoMod4" 3 "SteerRatModReq_DynoMod3" 2 "SteerRatModReq_DynoMod2" 1 "SteerRatModReq_DynoMod1" 0 "SteerRatModReq_Ukwn";
VAL_ 339 SteerSetgPen 15 "IdPen_ProfAll" 14 "IdPen_Resd14" 13 "IdPen_Prof13" 12 "IdPen_Prof12" 11 "IdPen_Prof11" 10 "IdPen_Prof10" 9 "IdPen_Prof9" 8 "IdPen_Prof8" 7 "IdPen_Prof7" 6 "IdPen_Prof6" 5 "IdPen_Prof5" 4 "IdPen_Prof4" 3 "IdPen_Prof3" 2 "IdPen_Prof2" 1 "IdPen_Prof1" 0 "IdPen_ProfUkwn";
VAL_ 339 SteerSetgSteerAsscLvl 7 "SteerAsscLvl_Resd7" 6 "SteerAsscLvl_Resd6" 5 "SteerAsscLvl_Resd5" 4 "SteerAsscLvl_Lvl4" 3 "SteerAsscLvl_Lvl3" 2 "SteerAsscLvl_Lvl2" 1 "SteerAsscLvl_Lvl1" 0 "SteerAsscLvl_Ukwn";
VAL_ 339 SteerSetgSteerMod 7 "SteerMod_Resd7" 6 "SteerMod_Resd6" 5 "SteerMod_Resd5" 4 "SteerMod_Mod4" 3 "SteerMod_Mod3" 2 "SteerMod_Mod2" 1 "SteerMod_Mod1" 0 "SteerMod_Ukwn";
VAL_ 339 SuspStfnVlvCtrlStsFL 3 "VlvCtrlSts_C1AndC2AndC3" 2 "VlvCtrlSts_C1AndC3" 1 "VlvCtrlSts_C1AndC2" 0 "VlvCtrlSts_Chmb1";
VAL_ 339 SuspStfnVlvCtrlStsFR 3 "VlvCtrlSts_C1AndC2AndC3" 2 "VlvCtrlSts_C1AndC3" 1 "VlvCtrlSts_C1AndC2" 0 "VlvCtrlSts_Chmb1";
VAL_ 339 SuspStfnVlvCtrlStsRL 3 "VlvCtrlSts_C1AndC2AndC3" 2 "VlvCtrlSts_C1AndC3" 1 "VlvCtrlSts_C1AndC2" 0 "VlvCtrlSts_Chmb1";
VAL_ 339 SuspStfnVlvCtrlStsRR 3 "VlvCtrlSts_C1AndC2AndC3" 2 "VlvCtrlSts_C1AndC3" 1 "VlvCtrlSts_C1AndC2" 0 "VlvCtrlSts_Chmb1";
VAL_ 339 ZCAirSuspCtrlStsZCAirSuspCtrlSts 3 "SuspCtrlSts_Reserve" 2 "SuspCtrlSts_No_Adjmt" 1 "SuspCtrlSts_Adjmt" 0 "SuspCtrlSts_Default";
VAL_ 289 BBWPullOverReq 1 "YesNo2_Yes" 0 "YesNo2_No";
VAL_ 289 BrkPedlPsdBrkPedlNotPsdSafe 1 "NoYes1_Yes" 0 "NoYes1_No";
VAL_ 289 BrkPedlPsdBrkPedlPsd 1 "NoYes1_Yes" 0 "NoYes1_No";
VAL_ 289 BrkPedlPsdQf 3 "GenQf1_AccurData" 2 "GenQf1_DataAccurNotWithinSpcn" 1 "GenQf1_TmpUndefdData" 0 "GenQf1_UndefindDataAccur";
VAL_ 289 ChassisObstclCrsModIncn 3 "ModIncn_OutOfRng" 2 "ModIncn_Active" 1 "ModIncn_Unactv" 0 "ModIncn_Invalid";
VAL_ 289 HeiLimModIncn 3 "ModIncn_OutOfRng" 2 "ModIncn_Active" 1 "ModIncn_Unactv" 0 "ModIncn_Invalid";
VAL_ 1173 TiAndDateIndcnDataValid 1 "NoYes1_Yes" 0 "NoYes1_No";
VAL_ 1173 VehBattUSysUQf 3 "GenQf1_AccurData" 2 "GenQf1_DataAccurNotWithinSpcn" 1 "GenQf1_TmpUndefdData" 0 "GenQf1_UndefindDataAccur";
VAL_ 569 DrvModReq 31 "DrvModReqType3_Reserved3" 30 "DrvModReqType3_Reserved2" 29 "DrvModReqType3_Reserved1" 28 "DrvModReqType3_Crossing" 27 "DrvModReqType3_4L" 26 "DrvModReqType3_4H" 25 "DrvModReqType3_Comfortablerearseats" 24 "DrvModReqType3_Allterrain" 23 "DrvModReqType3_4WD" 22 "DrvModReqType3_SportPlus" 21 "DrvModReqType3_Anti_Carsickness" 20 "DrvModReqType3_WaterWading" 19 "DrvModReqType3_Mountain" 18 "DrvModReqType3_DeepSnow" 17 "DrvModReqType3_GrassorGravel" 16 "DrvModReqType3_Slippery" 15 "DrvModReqType3_Err" 14 "DrvModReqType3_Rock" 13 "DrvModReqType3_Mud" 12 "DrvModReqType3_Sand" 11 "DrvModReqType3_Snow" 10 "DrvModReqType3_Power" 9 "DrvModReqType3_Hybrid" 8 "DrvModReqType3_Pure_EV" 7 "DrvModReqType3_Race" 6 "DrvModReqType3_Adaptive" 5 "DrvModReqType3_Offroad_CrossTerrain" 4 "DrvModReqType3_Individual" 3 "DrvModReqType3_Dynamic_Sport" 2 "DrvModReqType3_Comfort_Normal" 1 "DrvModReqType3_ECO" 0 "DrvModReqType3_Undefd";
VAL_ 569 DrvrSeatSnsrSts 3 "OkNokDi_Reserved" 2 "OkNokDi_Disabled" 1 "OkNokDi_NotOk" 0 "OkNokDi_Ok";
VAL_ 569 DrvrSeatSts 3 "OccptPresSt1_Undefd2" 2 "OccptPresSt1_OccptPrsnt" 1 "OccptPresSt1_OccptNotPrsnt" 0 "OccptPresSt1_Undefd1";
VAL_ 569 IAMSMod 1 "OnOff1_On" 0 "OnOff1_Off";
VAL_ 569 LockgCenStsLockSt 3 "LockSt3_LockLockd" 2 "LockSt3_LockTrUnlckd" 1 "LockSt3_LockUnlckd" 0 "LockSt3_LockUndefd";
VAL_ 569 LockgCenStsTrigSrc 11 "LockTrigSrc2_InsOth" 10 "LockTrigSrc2_OutsOth" 9 "LockTrigSrc2_Apprch" 8 "LockTrigSrc2_Crash" 7 "LockTrigSrc2_Telm" 6 "LockTrigSrc2_Slam" 5 "LockTrigSrc2_TmrAut" 4 "LockTrigSrc2_SpdAut" 3 "LockTrigSrc2_IntrSwt" 2 "LockTrigSrc2_Keyls" 1 "LockTrigSrc2_KeyRem" 0 "LockTrigSrc2_NoTrigSrc";
VAL_ 569 LockgCenStsUpdEve 1 "Boolean_TRUE" 0 "Boolean_FALSE";
VAL_ 569 PtTqAtWhlFrntActPtTqAtWhlsFrntQly 7 "Qly3_De7" 6 "Qly3_De6" 5 "Qly3_De5" 4 "Qly3_De4" 3 "Qly3_De3" 2 "Qly3_De2" 1 "Qly3_De1" 0 "Qly3_De0";
VAL_ 569 PVMCSteerAst 6 "CtrlModLvl2_Resd" 5 "CtrlModLvl2_Level4" 4 "CtrlModLvl2_Level3" 3 "CtrlModLvl2_Level2" 2 "CtrlModLvl2_Level1" 1 "CtrlModLvl2_Level0" 0 "CtrlModLvl2_No_Request";
VAL_ 625 AmbTRawQly 3 "GenQf1_AccurData" 2 "GenQf1_DataAccurNotWithinSpcn" 1 "GenQf1_TmpUndefdData" 0 "GenQf1_UndefindDataAccur";
VAL_ 102 AbsCtrlActvCtrlSts1 1 "CtrlSts1_InCtrl" 0 "CtrlSts1_NoCtrl";
VAL_ 102 BrkTracCtrlActv 1 "CtrlSts1_InCtrl" 0 "CtrlSts1_NoCtrl";
VAL_ 102 GVMCPrpsnTqDistbnReqAtAxleReCtrlMod 1 "Boolean_TRUE" 0 "Boolean_FALSE";
VAL_ 102 GVMCSuspDampgCtrlReqGVMCSuspDampgCtrlMod 3 "CtrlMode3_Resd" 2 "CtrlMode3_Freq" 1 "CtrlMode3_LvlReq" 0 "CtrlMode3_NoReq";
VAL_ 102 GVMCSuspDampgCtrlReqGVMCSuspDampgModReq 3 "SuspDampgModReq_Hard" 2 "SuspDampgModReq_Med" 1 "SuspDampgModReq_Soft" 0 "SuspDampgModReq_NoReq";
VAL_ 102 PVMCSuspHeiCtrlReqGVMCSuspPosnCtrlMod 3 "CtrlSts3_Resd" 2 "CtrlSts3_HeiReq" 1 "CtrlSts3_LvlReq" 0 "CtrlSts3_NoReq";
VAL_ 102 PVMCSuspHeiCtrlReqGVMCSuspPosnModReq 7 "SuspPosnModReq_Lo3" 6 "SuspPosnModReq_Lo2" 5 "SuspPosnModReq_Lo1" 4 "SuspPosnModReq_Norm" 3 "SuspPosnModReq_Hi1" 2 "SuspPosnModReq_Hi2" 1 "SuspPosnModReq_Hi3" 0 "SuspPosnModReq_NoReq";
VAL_ 102 PVMCVehCtrlSts2ActrTarFctSts 7 "FctSts_Resd2" 6 "FctSts_Resd1" 5 "FctSts_Fault" 4 "FctSts_Disabled" 3 "FctSts_Inhibited" 2 "FctSts_Active" 1 "FctSts_Enabled" 0 "FctSts_Init";
VAL_ 102 PVMCVehCtrlSts2BbWBackUpFctSts 7 "FctSts_Resd2" 6 "FctSts_Resd1" 5 "FctSts_Fault" 4 "FctSts_Disabled" 3 "FctSts_Inhibited" 2 "FctSts_Active" 1 "FctSts_Enabled" 0 "FctSts_Init";
VAL_ 102 PVMCVehCtrlSts2BrkDiscClngFctSts 7 "FctSts_Resd2" 6 "FctSts_Resd1" 5 "FctSts_Fault" 4 "FctSts_Disabled" 3 "FctSts_Inhibited" 2 "FctSts_Active" 1 "FctSts_Enabled" 0 "FctSts_Init";
VAL_ 102 PVMCVehCtrlSts2BrkTqDeltaFctSts 7 "FctSts_Resd2" 6 "FctSts_Resd1" 5 "FctSts_Fault" 4 "FctSts_Disabled" 3 "FctSts_Inhibited" 2 "FctSts_Active" 1 "FctSts_Enabled" 0 "FctSts_Init";
VAL_ 102 PVMCVehCtrlSts2CrabMovgFctSts 7 "FctSts_Resd2" 6 "FctSts_Resd1" 5 "FctSts_Fault" 4 "FctSts_Disabled" 3 "FctSts_Inhibited" 2 "FctSts_Active" 1 "FctSts_Enabled" 0 "FctSts_Init";
VAL_ 102 PVMCVehCtrlSts2DecelReqActrSts 7 "FctSts_Resd2" 6 "FctSts_Resd1" 5 "FctSts_Fault" 4 "FctSts_Disabled" 3 "FctSts_Inhibited" 2 "FctSts_Active" 1 "FctSts_Enabled" 0 "FctSts_Init";
VAL_ 102 PVMCVehCtrlSts2FloatingDrvgFctSts 7 "FctSts_Resd2" 6 "FctSts_Resd1" 5 "FctSts_Fault" 4 "FctSts_Disabled" 3 "FctSts_Inhibited" 2 "FctSts_Active" 1 "FctSts_Enabled" 0 "FctSts_Init";
VAL_ 102 PVMCVehCtrlSts2LowSpdStrFctSts 7 "FctSts_Resd2" 6 "FctSts_Resd1" 5 "FctSts_Fault" 4 "FctSts_Disabled" 3 "FctSts_Inhibited" 2 "FctSts_Active" 1 "FctSts_Enabled" 0 "FctSts_Init";
VAL_ 102 PVMCVehCtrlSts2SbWBackUpLatFctSts 7 "FctSts_Resd2" 6 "FctSts_Resd1" 5 "FctSts_Fault" 4 "FctSts_Disabled" 3 "FctSts_Inhibited" 2 "FctSts_Active" 1 "FctSts_Enabled" 0 "FctSts_Init";
VAL_ 102 PVMCVehCtrlSts2SbWBackUpLgtFctSts 7 "FctSts_Resd2" 6 "FctSts_Resd1" 5 "FctSts_Fault" 4 "FctSts_Disabled" 3 "FctSts_Inhibited" 2 "FctSts_Active" 1 "FctSts_Enabled" 0 "FctSts_Init";
VAL_ 102 PVMCVehCtrlSts2TankTurnFctSts 7 "FctSts_Resd2" 6 "FctSts_Resd1" 5 "FctSts_Fault" 4 "FctSts_Disabled" 3 "FctSts_Inhibited" 2 "FctSts_Active" 1 "FctSts_Enabled" 0 "FctSts_Init";
VAL_ 102 PVMCVehCtrlSts2VDSWFctSts 7 "FctSts_Resd2" 6 "FctSts_Resd1" 5 "FctSts_Fault" 4 "FctSts_Disabled" 3 "FctSts_Inhibited" 2 "FctSts_Active" 1 "FctSts_Enabled" 0 "FctSts_Init";
VAL_ 102 PVMCVehCtrlSts2ViolentModFctSts 7 "FctSts_Resd2" 6 "FctSts_Resd1" 5 "FctSts_Fault" 4 "FctSts_Disabled" 3 "FctSts_Inhibited" 2 "FctSts_Active" 1 "FctSts_Enabled" 0 "FctSts_Init";
VAL_ 102 VehSpdLimSrc 15 "SpdLimSrc_ICCLimit4" 14 "SpdLimSrc_ICCLimit3" 13 "SpdLimSrc_ICCLimit2" 12 "SpdLimSrc_ICCLimit1" 11 "SpdLimSrc_Src_Reserved4" 10 "SpdLimSrc_Src_Reserved3" 9 "SpdLimSrc_Src_Reserved2" 8 "SpdLimSrc_Src_Reserved1" 7 "SpdLimSrc_ECOModLimit" 6 "SpdLimSrc_DigKeyLimit" 5 "SpdLimSrc_ASLOrASVLSpdLimit" 4 "SpdLimSrc_StrangerModLimit" 3 "SpdLimSrc_MntnModLimit" 2 "SpdLimSrc_CCP43Limit" 1 "SpdLimSrc_PtLimit" 0 "SpdLimSrc_NoLimit";
VAL_ 102 WhlSpdCircumlFrntLeQf 3 "GenQf1_AccurData" 2 "GenQf1_DataAccurNotWithinSpcn" 1 "GenQf1_TmpUndefdData" 0 "GenQf1_UndefindDataAccur";
VAL_ 102 WhlSpdCircumlFrntRiQf 3 "GenQf1_AccurData" 2 "GenQf1_DataAccurNotWithinSpcn" 1 "GenQf1_TmpUndefdData" 0 "GenQf1_UndefindDataAccur";
VAL_ 102 WhlSpdCircumlReLeQf 3 "GenQf1_AccurData" 2 "GenQf1_DataAccurNotWithinSpcn" 1 "GenQf1_TmpUndefdData" 0 "GenQf1_UndefindDataAccur";
VAL_ 102 WhlSpdCircumlReRiQf 3 "GenQf1_AccurData" 2 "GenQf1_DataAccurNotWithinSpcn" 1 "GenQf1_TmpUndefdData" 0 "GenQf1_UndefindDataAccur";
VAL_ 752 CmptmtTFrntFanForCmptmtTRunng 1 "Flg1_Set" 0 "Flg1_Rst";
VAL_ 752 CmptmtTFrntQf 3 "CmptmtTFrntQf_SnsrDataOk" 2 "CmptmtTFrntQf_SnsrDataNotOk" 1 "CmptmtTFrntQf_FanNotRunning" 0 "CmptmtTFrntQf_SnsrDataUndefd";
VAL_ 752 LiBattInPWLock 1 "OnOff1_On" 0 "OnOff1_Off";
VAL_ 752 RlyPwrDistbnCmd1WdIgnRlyCmd 1 "OnOff1_On" 0 "OnOff1_Off";
VAL_ 752 ULoWarnLvPwrErrLVPwrSplyErrSts 15 "PwrSplyErrSts_E2EFault" 14 "PwrSplyErrSts_SpprtBattFltChrgn" 13 "PwrSplyErrSts_AltFltCom" 12 "PwrSplyErrSts_AltFltT" 11 "PwrSplyErrSts_AltFltElec" 10 "PwrSplyErrSts_AltFltMecl" 9 "PwrSplyErrSts_SupCptrHwFlt" 8 "PwrSplyErrSts_LatentFairDCDC" 7 "PwrSplyErrSts_FltElecDcDc" 6 "PwrSplyErrSts_FltComDcDc" 5 "PwrSplyErrSts_BattSnsrHwFlt" 4 "PwrSplyErrSts_BattSnsrComFlt" 3 "PwrSplyErrSts_BattRlyFlt" 2 "PwrSplyErrSts_UloDurgdrvg" 1 "PwrSplyErrSts_UhiDurgDrvg" 0 "PwrSplyErrSts_SysOk";
VAL_ 752 ULoWarnLvPwrErrULoWarn 3 "ULoWarn_ULoDcDc" 2 "ULoWarn_ULoPrmnt" 1 "ULoWarn_ULoTmp" 0 "ULoWarn_UOk";
VAL_ 1281 WakeUpReasonsforZCUDM 741 "WakeupReasons_871868" 740 "WakeupReasons_871957" 739 "WakeupReasons_871729" 738 "WakeupReasons_700779" 737 "WakeupReasons_839414" 736 "WakeupReasons_675025" 735 "WakeupReasons_671146" 734 "WakeupReasons_1031929" 733 "WakeupReasons_1033548" 732 "WakeupReasons_1033537" 731 "WakeupReasons_1033479" 730 "WakeupReasons_1030765" 729 "WakeupReasons_1028674" 728 "WakeupReasons_1033567" 727 "WakeupReasons_1033543" 726 "WakeupReasons_1033549" 725 "WakeupReasons_1033554" 724 "WakeupReasons_1033563" 723 "WakeupReasons_1033558" 722 "WakeupReasons_1029384" 721 "WakeupReasons_1029383" 720 "WakeupReasons_1029382" 719 "WakeupReasons_1032619" 718 "WakeupReasons_1024928" 717 "WakeupReasons_1033547" 716 "WakeupReasons_1033541" 715 "WakeupReasons_1033562" 714 "WakeupReasons_1033564" 713 "WakeupReasons_986765" 712 "WakeupReasons_1026103" 711 "WakeupReasons_1030764" 710 "WakeupReasons_1030941" 709 "WakeupReasons_1033556" 708 "WakeupReasons_1033539" 707 "WakeupReasons_1033534" 706 "WakeupReasons_1032477" 705 "WakeupReasons_1031280" 704 "WakeupReasons_1033542" 703 "WakeupReasons_1033632" 702 "WakeupReasons_1033533" 701 "WakeupReasons_1029166" 700 "WakeupReasons_1033538" 699 "WakeupReasons_1031789" 698 "WakeupReasons_1033552" 697 "WakeupReasons_1033553" 696 "WakeupReasons_1033559" 695 "WakeupReasons_1033544" 694 "WakeupReasons_1033561" 693 "WakeupReasons_1031029" 692 "WakeupReasons_1030360" 691 "WakeupReasons_1030761" 690 "WakeupReasons_1033550" 689 "WakeupReasons_1032579" 688 "WakeupReasons_1033557" 687 "WakeupReasons_1031936" 686 "WakeupReasons_1033566" 685 "WakeupReasons_1033551" 684 "WakeupReasons_1033540" 683 "WakeupReasons_1030760" 682 "WakeupReasons_1029735" 681 "WakeupReasons_1033565" 680 "WakeupReasons_852370" 679 "WakeupReasons_1033555" 678 "WakeupReasons_1033546" 677 "WakeupReasons_1032743" 676 "WakeupReasons_1032791" 675 "WakeupReasons_1033569" 674 "WakeupReasons_1031030" 673 "WakeupReasons_1028778" 672 "WakeupReasons_1030759" 671 "WakeupReasons_1031907" 670 "WakeupReasons_1033560" 669 "WakeupReasons_1031288" 668 "WakeupReasons_1030302" 667 "WakeupReasons_1031765" 666 "WakeupReasons_1031990" 665 "WakeupReasons_1028729" 664 "WakeupReasons_1030362" 663 "WakeupReasons_1030361" 662 "WakeupReasons_1030297" 661 "WakeupReasons_1030293" 660 "WakeupReasons_527345" 659 "WakeupReasons_988154" 658 "WakeupReasons_533580" 657 "WakeupReasons_533581" 656 "WakeupReasons_533576" 655 "WakeupReasons_1030255" 654 "WakeupReasons_527348" 653 "WakeupReasons_533578" 652 "WakeupReasons_527347" 651 "WakeupReasons_527346" 650 "WakeupReasons_ADCUReserve" 649 "WakeupReasons_885767" 648 "WakeupReasons_909025" 647 "WakeupReasons_909026" 646 "WakeupReasons_858177" 645 "WakeupReasons_858169" 644 "WakeupReasons_858152" 643 "WakeupReasons_973575" 642 "WakeupReason_973574" 641 "WakeupReason_987405" 640 "WakeupReason_858187" 639 "WakeupReason_988826" 638 "WakeupReason_988821" 637 "WakeupReason_987485" 636 "WakeupReason_908128" 635 "WakeupReason_908115" 634 "WakeupReason_856234" 633 "WakeupReason_856224" 632 "WakeupReason_858189" 631 "WakeupReason_858188" 630 "WakeupReason_872056" 629 "WakeupReason_870276" 628 "WakeupReason_858191" 627 "WakeupReason_847054" 626 "WakeupReason_856465" 625 "WakeupReason_872253" 624 "WakeupReason_855003" 623 "WakeupReason_855002" 622 "WakeupReason_854947" 621 "WakeupReason_855134" 620 "WakeupReason_854839" 619 "WakeupReason_854999" 618 "WakeupReason_855029" 617 "WakeupReason_714340" 616 "WakeupReason_852947" 615 "WakeupReason_852944" 614 "WakeupReason_852646" 613 "WakeupReason_852537" 612 "WakeupReason_852388" 611 "WakeupReason_852385" 610 "WakeupReason_852298" 609 "WakeupReason_852273" 608 "WakeupReason_852248" 607 "WakeupReason_852219" 606 "WakeupReason_852218" 605 "WakeupReason_852215" 604 "WakeupReason_852200" 603 "WakeupReason_852195" 602 "WakeupReason_852194" 601 "WakeupReason_852184" 600 "WakeupReason_852180" 599 "WakeupReason_852050" 598 "WakeupReason_852010" 597 "WakeupReason_851743" 596 "WakeupReason_851482" 595 "WakeupReason_702420" 594 "WakeupReason_667533" 593 "WakeupReason_645735" 592 "WakeupReason_362462" 591 "WakeupReason_361474" 590 "WakeupReason_361441" 589 "WakeupReason_846002" 588 "WakeupReason_845930" 587 "WakeupReason_842273" 586 "WakeupReason_846372" 585 "WakeupReason_675489" 584 "WakeupReason_675452" 583 "WakeupReason_298032" 582 "WakeupReason_322113" 581 "WakeupReason_320145" 580 "WakeupReason_841275" 579 "WakeupReason_839787" 578 "WakeupReason_839181" 577 "WakeupReason_714677" 576 "WakeupReason_840035" 566 "WakeupReason_839458" 565 "WakeupReason_837760" 564 "WakeupReason_702903" 563 "WakeupReason_837962" 562 "WakeupReason_703140" 561 "WakeupReason_837833" 560 "WakeupReason_839705" 559 "WakeupReason_839473" 558 "WakeupReason_838116" 557 "WakeupReason_717832" 556 "WakeupReason_714697" 555 "WakeupReason_714799" 554 "WakeupReason_714806" 553 "WakeupReason_709196" 552 "WakeupReason_710893" 551 "WakeupReason_708964" 550 "WakeupReason_715529" 549 "WakeupReason_714265" 548 "WakeupReason_714172" 547 "WakeupReason_713799" 546 "WakeupReason_706194" 545 "WakeupReason_713568" 544 "WakeupReason_710807" 543 "WakeupReason_714679" 542 "WakeupReason_714678" 541 "WakeupReason_715842" 540 "WakeupReason_714030" 539 "WakeupReason_710922" 538 "WakeupReason_716243" 537 "WakeupReason_713786" 536 "WakeupReason_714675" 535 "WakeupReason_702478" 534 "WakeupReason_713752" 533 "WakeupReasons_700530" 532 "WakeupReasons_698631" 531 "WakeupReasons_702452" 530 "WakeupReasons_700565" 529 "WakeupReasons_702402" 528 "WakeupReasons_702439" 527 "WakeupReasons_702448" 526 "WakeupReasons_701872" 525 "WakeupReasons_699114" 524 "WakeupReasons_702240" 523 "WakeupReasons_701270" 522 "WakeupReasons_533751" 521 "WakeupReasons_698581" 520 "WakeupReasons_698130" 519 "WakeupReasons_700130" 518 "WakeupReasons_699921" 517 "WakeupReasons_699919" 516 "WakeupReasons_700486" 515 "WakeupReasons_700782" 514 "WakeupReasons_696971" 513 "WakeupReasons_700692" 512 "WakeupReasons_698385" 511 "WakeupReasons_699922" 510 "WakeupReasons_697967" 509 "WakeupReasons_700684" 508 "WakeupReasons_644379" 507 "WakeupReasons_336435" 506 "WakeupReasons_683263" 505 "WakeupReasons_700554" 504 "WakeupReasons_691992" 503 "WakeupReasons_698129" 502 "WakeupReasons_696850" 501 "WakeupReasons_702088" 500 "WakeupReasons_696612" 499 "WakeupReasons_691994" 498 "WakeupReasons_700483" 497 "WakeupReasons_702204" 496 "WakeupReasons_700603" 495 "WakeupReasons_700215" 494 "WakeupReasons_701509" 493 "WakeupReasons_701508" 492 "WakeupReasons_700484" 491 "WakeupReasons_217907" 490 "WakeupReasons_194966" 489 "WakeupReasons_702174" 488 "WakeupReasons_697145" 487 "WakeupReasons_296931" 486 "WakeupReasons_700687" 485 "WakeupReasons_700686" 484 "WakeupReasons_698409" 483 "WakeupReasons_533750" 482 "WakeupReasons_700467" 481 "WakeupReasons_687404" 480 "WakeupReasons_681813" 479 "WakeupReasons_698288" 478 "WakeupReasons_698660" 477 "WakeupReasons_691993" 476 "WakeupReasons_700485" 475 "WakeupReasons_700425" 474 "WakeupReasons_702197" 473 "WakeupReasons_637992" 472 "WakeupReasons_698488" 471 "WakeupReasons_691991" 470 "WakeupReasons_692547" 469 "WakeupReasons_693914" 468 "WakeupReasons_693024" 467 "WakeupReasons_693005" 466 "WakeupReasons_667949" 465 "WakeupReasons_686281" 464 "WakeupReasons_680764" 463 "WakeupReasons_512384" 462 "WakeupReasons_692019" 461 "WakeupReasons_533850" 460 "WakeupReasons_533849" 459 "WakeupReasons_667188" 458 "WakeupReasons_514652" 457 "WakeupReasons_514651" 456 "WakeupReasons_112024" 455 "WakeupReasons_300690" 454 "WakeupReasons_299532" 453 "WakeupReasons_299531" 452 "WakeupReasons_299120" 451 "WakeupReasons_273516" 450 "WakeupReasons_265694" 449 "WakeupReasons_692439" 448 "WakeupReasons_354831" 447 "WakeupReasons_680765" 446 "WakeupReasons_45895" 445 "WakeupReasons_644275" 444 "WakeupReasons_351189" 443 "WakeupReasons_226570" 442 "WakeupReasons_654489" 441 "WakeupReasons_110181" 440 "WakeupReasons_226569" 439 "WakeupReasons_45896" 438 "WakeupReasons_112031" 437 "WakeupReasons_110173" 436 "WakeupReasons_677781" 435 "WakeupReasons_690939" 434 "WakeupReasons_354809" 433 "WakeupReasons_692022" 432 "WakeupReasons_690593" 431 "WakeupReasons_226571" 430 "WakeupReasons_675594" 429 "WakeupReasons_226565" 428 "WakeupReasons_692020" 427 "WakeupReasons_112035" 426 "WakeupReasons_112027" 425 "WakeupReasons_354672" 424 "WakeupReasons_168967" 423 "WakeupReasons_354674" 422 "WakeupReasons_168968" 421 "WakeupReasons_641483" 420 "WakeupReasons_641482" 419 "WakeupReasons_265698" 418 "WakeupReasons_265699" 417 "WakeupReasons_360491" 416 "WakeupReasons_357498" 415 "WakeupReasons_170290" 414 "WakeupReasons_690385" 413 "WakeupReasons_692021" 412 "WakeupReasons_91254" 411 "WakeupReasons_346654" 410 "WakeupReasons_200637" 409 "WakeupReasons_170285" 408 "WakeupReasons_265678" 407 "WakeupReasons_683934" 406 "WakeupReasons_680763" 405 "WakeupReasons_682074" 404 "WakeupReasons_682154" 403 "WakeupReasons_682152" 402 "WakeupReasons_682155" 401 "WakeupReasons_682153" 400 "WakeupReasons_682078" 399 "WakeupReasons_682076" 398 "WakeupReasons_682077" 397 "WakeupReasons_676285" 396 "WakeupReasons_681023" 395 "WakeupReasons_682023" 394 "WakeupReasons_681789" 393 "WakeupReasons_682688" 392 "WakeupReasons_682037" 391 "WakeupReasons_682032" 390 "WakeupReasons_681915" 389 "WakeupReasons_674839" 388 "WakeupReasons_682034" 387 "WakeupReasons_681711" 386 "WakeupReasons_681031" 385 "WakeupReasons_681134" 384 "WakeupReasons_670462" 383 "WakeupReasons_681028" 382 "WakeupReasons_680975" 381 "WakeupReasons_680974" 380 "WakeupReasons_668523" 379 "WakeupReasons_669822" 378 "WakeupReasons_680712" 377 "WakeupReasons_671005" 376 "WakeupReasons_177214" 375 "WakeupReasons_45655" 374 "WakeupReasons_667872" 373 "WakeupReasons_264964" 372 "WakeupReasons_262871" 371 "WakeupReasons_264691" 370 "WakeupReasons_297056" 369 "WakeupReasons_233755" 368 "WakeupReasons_145161" 367 "WakeupReasons_667842" 366 "WakeupReasons_46020" 365 "WakeupReasons_667874" 364 "WakeupReasons_667981" 363 "WakeupReasons_224211" 362 "WakeupReasons_45902" 361 "WakeupReasons_329457" 360 "WakeupReasons_88458" 359 "WakeupReasons_45900" 358 "WakeupReasons_83199" 357 "WakeupReasons_532933" 356 "WakeupReasons_532932" 355 "WakeupReasons_670942" 354 "WakeupReasons_305818" 353 "WakeupReasons_75103" 352 "WakeupReasons_667987" 351 "WakeupReasons_667983" 350 "WakeupReasons_675745" 349 "WakeupReasons_356598" 348 "WakeupReasons_128671" 347 "WakeupReasons_69216" 346 "WakeupReasons_264697" 345 "WakeupReasons_264943" 344 "WakeupReasons_197644" 343 "WakeupReasons_675564" 342 "WakeupReasons_657120" 341 "WakeupReasons_265745" 340 "WakeupReasons_657121" 339 "WakeupReasons_667982" 338 "WakeupReasons_674223" 337 "WakeupReasons_127926" 336 "WakeupReasons_127924" 335 "WakeupReasons_262872" 334 "WakeupReasons_45848" 333 "WakeupReasons_45847" 332 "WakeupReasons_45846" 331 "WakeupReasons_667869" 330 "WakeupReasons_45890" 329 "WakeupReasons_45888" 328 "WakeupReasons_670962" 327 "WakeupReasons_667973" 326 "WakeupReasons_45877" 325 "WakeupReasons_667980" 324 "WakeupReasons_45876" 323 "WakeupReasons_45871" 322 "WakeupReasons_45875" 321 "WakeupReasons_45872" 320 "WakeupReasons_45870" 319 "WakeupReasons_45869" 318 "WakeupReasons_80608" 317 "WakeupReasons_45898" 316 "WakeupReasons_45897" 315 "WakeupReasons_69679" 314 "WakeupReasons_69678" 313 "WakeupReasons_45887" 312 "WakeupReasons_263473" 311 "WakeupReasons_265131" 310 "WakeupReasons_268983" 309 "WakeupReasons_139075" 308 "WakeupReasons_200090" 307 "WakeupReasons_199714" 306 "WakeupReasons_80609" 305 "WakeupReasons_106669" 304 "WakeupReasons_675742" 303 "WakeupReasons_46017" 302 "WakeupReasons_670354" 301 "WakeupReasons_667985" 300 "WakeupReasons_670966" 299 "WakeupReasons_667871" 298 "WakeupReasons_193474" 297 "WakeupReasons_113348" 296 "WakeupReasons_532556" 295 "WakeupReasons_532555" 294 "WakeupReasons_667988" 293 "WakeupReasons_182918" 292 "WakeupReasons_311279" 291 "WakeupReasons_667848" 290 "WakeupReasons_667850" 289 "WakeupReasons_668393" 288 "WakeupReasons_668395" 287 "WakeupReasons_670753" 286 "WakeupReasons_667922" 285 "WakeupReasons_669447" 284 "WakeupReasons_670928" 283 "WakeupReasons_669465" 282 "WakeupReasons_676265" 281 "WakeupReasons_667947" 280 "WakeupReasons_667879" 279 "WakeupReasons_675837" 278 "WakeupReasons_675494" 277 "WakeupReasons_674958" 276 "WakeupReasons_675064" 275 "WakeupReasons_674953" 274 "WakeupReasons_658188" 273 "WakeupReasons_337991" 272 "WakeupReasons_197653" 271 "WakeupReasons_269140" 270 "WakeupReasons_312881" 269 "WakeupReasons_215560" 268 "WakeupReasons_269034" 267 "WakeupReasons_4471" 266 "WakeupReasons_185490" 265 "WakeupReasons_185457" 264 "WakeupReasons_198452" 263 "WakeupReasons_200683" 262 "WakeupReasons_358832" 261 "WakeupReasons_NMPDUReceived" 260 "WakeupReasons_670345" 259 "WakeupReasons_109467" 258 "WakeupReasons_109466" 257 "WakeupReasons_636801" 256 "WakeupReasons_45849" 255 "WakeupReasons_45850" 254 "WakeupReasons_45851" 253 "WakeupReasons_45852" 252 "WakeupReasons_45854" 251 "WakeupReasons_45853" 250 "WakeupReasons_45856" 249 "WakeupReasons_533872" 248 "WakeupReasons_516327" 247 "WakeupReasons_359559" 246 "WakeupReasons_241902" 245 "WakeupReasons_533372" 244 "WakeupReasons_533371" 243 "WakeupReasons_533370" 242 "WakeupReasons_315981" 241 "WakeupReasons_45858" 240 "WakeupReasons_668529" 239 "WakeupReasons_670087" 238 "WakeupReasons_668531" 237 "WakeupReasons_223920" 236 "WakeupReasons_176748" 235 "WakeupReasons_146470" 234 "WakeupReasons_112799" 233 "WakeupReasons_95949" 232 "WakeupReasons_156440" 231 "WakeupReasons_166267" 230 "WakeupReasons_101727" 229 "WakeupReasons_101728" 228 "WakeupReasons_101725" 227 "WakeupReasons_101706" 226 "WakeupReasons_659350" 225 "WakeupReasons_667820" 224 "WakeupReasons_331194" 223 "WakeupReasons_652546" 222 "WakeupReasons_224553" 221 "WakeupReasons_224552" 220 "WakeupReasons_110885" 219 "WakeupReasons_667953" 218 "WakeupReasons_667962" 217 "WakeupReasons_224550" 216 "WakeupReasons_197665" 215 "WakeupReasons_225961" 214 "WakeupReasons_198433" 213 "WakeupReasons_526438" 212 "WakeupReasons_316796" 211 "WakeupReasons_335068" 210 "WakeupReasons_535214" 209 "WakeupReasons_264726" 208 "WakeupReasons_360542" 207 "WakeupReasons_531743" 206 "WakeupReasons_226967" 205 "WakeupReasons_318382" 204 "WakeupReasons_199159" 203 "WakeupReasons_223715" 202 "WakeupReasons_643973" 201 "WakeupReasons_319401" 200 "WakeupReasons_264712" 199 "WakeupReasons_526426" 198 "WakeupReasons_533050" 197 "WakeupReasons_265937" 196 "WakeupReasons_108834" 195 "WakeupReasons_636556" 194 "WakeupReasons_655340" 193 "WakeupReasons_320895" 192 "WakeupReasons_321077" 191 "WakeupReasons_321323" 190 "WakeupReasons_321319" 189 "WakeupReasons_321057" 188 "WakeupReasons_359187" 187 "WakeupReasons_321317" 186 "WakeupReasons_355214" 185 "WakeupReasons_652361" 184 "WakeupReasons_192030" 183 "WakeupReasons_534145" 182 "WakeupReasons_526445" 181 "WakeupReasons_360299" 180 "WakeupReasons_525705" 179 "WakeupReasons_534077" 178 "WakeupReasons_359211" 177 "WakeupReasons_300681" 176 "WakeupReasons_198484" 175 "WakeupReasons_356549" 174 "WakeupReasons_360543" 173 "WakeupReasons_318342" 172 "WakeupReasons_299547" 171 "WakeupReasons_646109" 170 "WakeupReasons_645753" 169 "WakeupReasons_514502" 168 "WakeupReasons_515804" 167 "WakeupReasons_298808" 166 "WakeupReasons_265330" 165 "WakeupReasons_265328" 164 "WakeupReasons_265305" 163 "WakeupReasons_361279" 162 "WakeupReasons_361272" 161 "WakeupReasons_160596" 160 "WakeupReasons_197648" 159 "WakeupReasons_658603" 158 "WakeupReasons_322857" 157 "WakeupReasons_108810" 156 "WakeupReasons_179103" 155 "WakeupReasons_321845" 154 "WakeupReasons_340667" 153 "WakeupReasons_299117" 152 "WakeupReasons_514503" 151 "WakeupReasons_532007" 150 "WakeupReasons_337565" 149 "WakeupReasons_320631" 148 "WakeupReasons_354791" 147 "WakeupReasons_317616" 146 "WakeupReasons_644550" 145 "WakeupReasons_265232" 144 "WakeupReasons_514545" 143 "WakeupReasons_526429" 142 "WakeupReasons_265569" 141 "WakeupReasons_108841" 140 "WakeupReasons_160602" 139 "WakeupReasons_160597" 138 "WakeupReasons_264958" 137 "WakeupReasons_300682" 136 "WakeupReasons_224634" 135 "WakeupReasons_224617" 134 "WakeupReasons_220322" 133 "WakeupReasons_300427" 132 "WakeupReasons_269156" 131 "WakeupReasons_145462" 130 "WakeupReasons_145454" 129 "WakeupReasons_145419" 128 "WakeupReasons_145288" 127 "WakeupReasons_145373" 126 "WakeupReasons_145385" 125 "WakeupReasons_145362" 124 "WakeupReasons_145399" 123 "WakeupReasons_145388" 122 "WakeupReasons_145330" 121 "WakeupReasons_152774" 120 "WakeupReasons_145319" 119 "WakeupReasons_145311" 118 "WakeupReasons_106774" 117 "WakeupReasons_533044" 116 "WakeupReasons_636692" 115 "WakeupReasons_355409" 114 "WakeupReasons_133749" 113 "WakeupReasons_156412" 112 "WakeupReasons_320287" 111 "WakeupReasons_201348" 110 "WakeupReasons_264962" 109 "WakeupReasons_169884" 108 "WakeupReasons_45867" 107 "WakeupReasons_45866" 106 "WakeupReasons_659549" 105 "WakeupReasons_45864" 104 "WakeupReasons_201815" 103 "WakeupReasons_224831" 102 "WakeupReasons_222553" 101 "WakeupReasons_140678" 100 "WakeupReasons_169945" 99 "WakeupReasons_95444" 98 "WakeupReasons_145688" 97 "WakeupReasons_356190" 96 "WakeupReasons_264934" 95 "WakeupReasons_264932" 94 "WakeupReasons_152786" 93 "WakeupReasons_144970" 92 "WakeupReasons_186489" 91 "WakeupReasons_144897" 90 "WakeupReasons_199172" 89 "WakeupReasons_145707" 88 "WakeupReasons_152237" 87 "WakeupReasons_67182" 86 "WakeupReasons_338820" 85 "WakeupReasons_634710" 84 "WakeupReasons_109387" 83 "WakeupReasons_320126" 82 "WakeupReasons_109367" 81 "WakeupReasons_315364" 80 "WakeupReasons_297868" 79 "WakeupReasons_645810" 78 "WakeupReasons_634696" 77 "WakeupReasons_138997" 76 "WakeupReasons_360006" 75 "WakeupReasons_224061" 74 "WakeupReasons_68481" 73 "WakeupReasons_109364" 72 "WakeupReasons_68644" 71 "WakeupReasons_224065" 70 "WakeupReasons_119273" 69 "WakeupReasons_109382" 68 "WakeupReasons_360008" 67 "WakeupReasons_68676" 66 "WakeupReasons_645094" 65 "WakeupReasons_361509" 64 "WakeupReasons_361505" 63 "WakeupReasons_360904" 62 "WakeupReasons_355601" 61 "WakeupReasons_320277" 60 "WakeupReasons_319422" 59 "WakeupReasons_320282" 58 "WakeupReasons_169894" 57 "WakeupReasons_266860" 56 "WakeupReasons_45656" 55 "WakeupReasons_21997" 54 "WakeupReasons_225696" 53 "WakeupReasons_200156" 52 "WakeupReasons_161066" 51 "WakeupReasons_185670" 50 "WakeupReasons_197826" 49 "WakeupReasons_176921" 48 "WakeupReasons_108776" 47 "WakeupReasons_265333" 46 "WakeupReasons_100281" 45 "WakeupReasons_100278" 44 "WakeupReasons_100300" 43 "WakeupReasons_100275" 42 "WakeupReasons_100298" 41 "WakeupReasons_319139" 40 "WakeupReasons_170807" 39 "WakeupReasons_200937" 38 "WakeupReasons_182033" 37 "WakeupReasons_191050" 36 "WakeupReasons_264876" 35 "WakeupReasons_197642" 34 "WakeupReasons_170865" 33 "WakeupReasons_168966" 32 "WakeupReasons_667948" 31 "WakeupReasons_169655" 30 "WakeupReasons_667945" 29 "WakeupReasons_74188" 28 "WakeupReasons_321583" 27 "WakeupReasons_88125" 26 "WakeupReasons_88123" 25 "WakeupReasons_91253" 24 "WakeupReasons_21973" 23 "WakeupReasons_140084" 22 "WakeupReasons_45657" 21 "WakeupReasons_45659" 20 "WakeupReasons_22100" 19 "WakeupReasons_22013" 18 "WakeupReasons_22005" 17 "WakeupReasons_45794" 16 "WakeupReasons_45793" 15 "WakeupReasons_21901" 14 "WakeupReasons_658500" 13 "WakeupReasons_269739" 12 "WakeupReasons_269735" 11 "WakeupReasons_269740" 10 "WakeupReasons_22060" 9 "WakeupReasons_49446" 8 "WakeupReasons_22058" 7 "WakeupReasons_45654" 6 "WakeupReasons_264933" 5 "WakeupReasons_197643" 4 "WakeupReasons_168965" 3 "WakeupReasons_667951" 2 "WakeupReasons_169654" 1 "WakeupReasons_667950" 0 "WakeupReasons_0";
VAL_ 1345 VFCVectorZCUDMVFCid0 1 "VFCOnOff_On" 0 "VFCOnOff_Off";
VAL_ 1345 VFCVectorZCUDMVFCid1 1 "VFCOnOff_On" 0 "VFCOnOff_Off";
VAL_ 1345 VFCVectorZCUDMVFCid10 1 "VFCOnOff_On" 0 "VFCOnOff_Off";
VAL_ 1345 VFCVectorZCUDMVFCid11 1 "VFCOnOff_On" 0 "VFCOnOff_Off";
VAL_ 1345 VFCVectorZCUDMVFCid12 1 "VFCOnOff_On" 0 "VFCOnOff_Off";
VAL_ 1345 VFCVectorZCUDMVFCid13 1 "VFCOnOff_On" 0 "VFCOnOff_Off";
VAL_ 1345 VFCVectorZCUDMVFCid14 1 "VFCOnOff_On" 0 "VFCOnOff_Off";
VAL_ 1345 VFCVectorZCUDMVFCid15 1 "VFCOnOff_On" 0 "VFCOnOff_Off";
VAL_ 1345 VFCVectorZCUDMVFCid16 1 "VFCOnOff_On" 0 "VFCOnOff_Off";
VAL_ 1345 VFCVectorZCUDMVFCid17 1 "VFCOnOff_On" 0 "VFCOnOff_Off";
VAL_ 1345 VFCVectorZCUDMVFCid18 1 "VFCOnOff_On" 0 "VFCOnOff_Off";
VAL_ 1345 VFCVectorZCUDMVFCid19 1 "VFCOnOff_On" 0 "VFCOnOff_Off";
VAL_ 1345 VFCVectorZCUDMVFCid2 1 "VFCOnOff_On" 0 "VFCOnOff_Off";
VAL_ 1345 VFCVectorZCUDMVFCid20 1 "VFCOnOff_On" 0 "VFCOnOff_Off";
VAL_ 1345 VFCVectorZCUDMVFCid21 1 "VFCOnOff_On" 0 "VFCOnOff_Off";
VAL_ 1345 VFCVectorZCUDMVFCid22 1 "VFCOnOff_On" 0 "VFCOnOff_Off";
VAL_ 1345 VFCVectorZCUDMVFCid23 1 "VFCOnOff_On" 0 "VFCOnOff_Off";
VAL_ 1345 VFCVectorZCUDMVFCid24 1 "VFCOnOff_On" 0 "VFCOnOff_Off";
VAL_ 1345 VFCVectorZCUDMVFCid25 1 "VFCOnOff_On" 0 "VFCOnOff_Off";
VAL_ 1345 VFCVectorZCUDMVFCid26 1 "VFCOnOff_On" 0 "VFCOnOff_Off";
VAL_ 1345 VFCVectorZCUDMVFCid27 1 "VFCOnOff_On" 0 "VFCOnOff_Off";
VAL_ 1345 VFCVectorZCUDMVFCid28 1 "VFCOnOff_On" 0 "VFCOnOff_Off";
VAL_ 1345 VFCVectorZCUDMVFCid29 1 "VFCOnOff_On" 0 "VFCOnOff_Off";
VAL_ 1345 VFCVectorZCUDMVFCid3 1 "VFCOnOff_On" 0 "VFCOnOff_Off";
VAL_ 1345 VFCVectorZCUDMVFCid30 1 "VFCOnOff_On" 0 "VFCOnOff_Off";
VAL_ 1345 VFCVectorZCUDMVFCid31 1 "VFCOnOff_On" 0 "VFCOnOff_Off";
VAL_ 1345 VFCVectorZCUDMVFCid32 1 "VFCOnOff_On" 0 "VFCOnOff_Off";
VAL_ 1345 VFCVectorZCUDMVFCid33 1 "VFCOnOff_On" 0 "VFCOnOff_Off";
VAL_ 1345 VFCVectorZCUDMVFCid34 1 "VFCOnOff_On" 0 "VFCOnOff_Off";
VAL_ 1345 VFCVectorZCUDMVFCid35 1 "VFCOnOff_On" 0 "VFCOnOff_Off";
VAL_ 1345 VFCVectorZCUDMVFCid36 1 "VFCOnOff_On" 0 "VFCOnOff_Off";
VAL_ 1345 VFCVectorZCUDMVFCid37 1 "VFCOnOff_On" 0 "VFCOnOff_Off";
VAL_ 1345 VFCVectorZCUDMVFCid38 1 "VFCOnOff_On" 0 "VFCOnOff_Off";
VAL_ 1345 VFCVectorZCUDMVFCid39 1 "VFCOnOff_On" 0 "VFCOnOff_Off";
VAL_ 1345 VFCVectorZCUDMVFCid4 1 "VFCOnOff_On" 0 "VFCOnOff_Off";
VAL_ 1345 VFCVectorZCUDMVFCid40 1 "VFCOnOff_On" 0 "VFCOnOff_Off";
VAL_ 1345 VFCVectorZCUDMVFCid41 1 "VFCOnOff_On" 0 "VFCOnOff_Off";
VAL_ 1345 VFCVectorZCUDMVFCid42 1 "VFCOnOff_On" 0 "VFCOnOff_Off";
VAL_ 1345 VFCVectorZCUDMVFCid43 1 "VFCOnOff_On" 0 "VFCOnOff_Off";
VAL_ 1345 VFCVectorZCUDMVFCid44 1 "VFCOnOff_On" 0 "VFCOnOff_Off";
VAL_ 1345 VFCVectorZCUDMVFCid45 1 "VFCOnOff_On" 0 "VFCOnOff_Off";
VAL_ 1345 VFCVectorZCUDMVFCid46 1 "VFCOnOff_On" 0 "VFCOnOff_Off";
VAL_ 1345 VFCVectorZCUDMVFCid47 1 "VFCOnOff_On" 0 "VFCOnOff_Off";
VAL_ 1345 VFCVectorZCUDMVFCid48 1 "VFCOnOff_On" 0 "VFCOnOff_Off";
VAL_ 1345 VFCVectorZCUDMVFCid49 1 "VFCOnOff_On" 0 "VFCOnOff_Off";
VAL_ 1345 VFCVectorZCUDMVFCid5 1 "VFCOnOff_On" 0 "VFCOnOff_Off";
VAL_ 1345 VFCVectorZCUDMVFCid50 1 "VFCOnOff_On" 0 "VFCOnOff_Off";
VAL_ 1345 VFCVectorZCUDMVFCid51 1 "VFCOnOff_On" 0 "VFCOnOff_Off";
VAL_ 1345 VFCVectorZCUDMVFCid52 1 "VFCOnOff_On" 0 "VFCOnOff_Off";
VAL_ 1345 VFCVectorZCUDMVFCid53 1 "VFCOnOff_On" 0 "VFCOnOff_Off";
VAL_ 1345 VFCVectorZCUDMVFCid54 1 "VFCOnOff_On" 0 "VFCOnOff_Off";
VAL_ 1345 VFCVectorZCUDMVFCid55 1 "VFCOnOff_On" 0 "VFCOnOff_Off";
VAL_ 1345 VFCVectorZCUDMVFCid56 1 "VFCOnOff_On" 0 "VFCOnOff_Off";
VAL_ 1345 VFCVectorZCUDMVFCid57 1 "VFCOnOff_On" 0 "VFCOnOff_Off";
VAL_ 1345 VFCVectorZCUDMVFCid58 1 "VFCOnOff_On" 0 "VFCOnOff_Off";
VAL_ 1345 VFCVectorZCUDMVFCid59 1 "VFCOnOff_On" 0 "VFCOnOff_Off";
VAL_ 1345 VFCVectorZCUDMVFCid6 1 "VFCOnOff_On" 0 "VFCOnOff_Off";
VAL_ 1345 VFCVectorZCUDMVFCid60 1 "VFCOnOff_On" 0 "VFCOnOff_Off";
VAL_ 1345 VFCVectorZCUDMVFCid61 1 "VFCOnOff_On" 0 "VFCOnOff_Off";
VAL_ 1345 VFCVectorZCUDMVFCid7 1 "VFCOnOff_On" 0 "VFCOnOff_Off";
VAL_ 1345 VFCVectorZCUDMVFCid8 1 "VFCOnOff_On" 0 "VFCOnOff_Off";
VAL_ 1345 VFCVectorZCUDMVFCid9 1 "VFCOnOff_On" 0 "VFCOnOff_Off";
VAL_ 535 CDCModlndcnForFAS 7 "CDCModIndcn_Resd2" 6 "CDCModIndcn_Resd1" 5 "CDCModIndcn_Offroad" 4 "CDCModIndcn_Adv" 3 "CDCModIndcn_Norm" 2 "CDCModIndcn_Sport" 1 "CDCModIndcn_Cmf" 0 "CDCModIndcn_Ukwn";
VAL_ 535 FASChassisObstclCrsModIncn 3 "ModIncn_OutOfRng" 2 "ModIncn_Active" 1 "ModIncn_Unactv" 0 "ModIncn_Invalid";
VAL_ 535 FASDrvModPrsnlAdjmtDamprCmftSts 1 "YesNo2_Yes" 0 "YesNo2_No";
VAL_ 535 FASDrvModPrsnlAdjmtDamprHardSts 1 "YesNo2_Yes" 0 "YesNo2_No";
VAL_ 535 FASDrvModPrsnlAdjmtDamprMedSts 1 "YesNo2_Yes" 0 "YesNo2_No";
VAL_ 535 FASDrvModPrsnlAdjmtDamprSts_Resv1 1 "YesNo2_Yes" 0 "YesNo2_No";
VAL_ 535 FASDrvModPrsnlAdjmtDamprSts_Resv2 1 "YesNo2_Yes" 0 "YesNo2_No";
VAL_ 535 FASDrvModPrsnlAdjmtSuspLvlHL1Sts 1 "YesNo2_Yes" 0 "YesNo2_No";
VAL_ 535 FASDrvModPrsnlAdjmtSuspLvlHL2Sts 1 "YesNo2_Yes" 0 "YesNo2_No";
VAL_ 535 FASDrvModPrsnlAdjmtSuspLvlLL1Sts 1 "YesNo2_Yes" 0 "YesNo2_No";
VAL_ 535 FASDrvModPrsnlAdjmtSuspLvlLL2Sts 1 "YesNo2_Yes" 0 "YesNo2_No";
VAL_ 535 FASDrvModPrsnlAdjmtSuspLvlNRHSts 1 "YesNo2_Yes" 0 "YesNo2_No";
VAL_ 535 FASEasyLoadModlndcn 7 "EasyLoadMod_Resv2" 6 "EasyLoadMod_Resv1" 5 "EasyLoadMod_Pos" 4 "EasyLoadMod_Neg" 3 "EasyLoadMod_Stab" 2 "EasyLoadMod_FullyClsd" 1 "EasyLoadMod_FullyOpend" 0 "EasyLoadMod_Ukwn";
VAL_ 535 FASHeiLimModIncn 3 "ModIncn_OutOfRng" 2 "ModIncn_Active" 1 "ModIncn_Unactv" 0 "ModIncn_Invalid";
VAL_ 535 FASLvlgDirMovmtindcr 3 "TriSt1_NotUsed" 2 "TriSt1_PosSt" 1 "TriSt1_StabSt" 0 "TriSt1_NegSt";
VAL_ 535 FASLvlgFctAvl 1 "Available1_Available" 0 "Available1_NotAvailable";
VAL_ 535 FASLvlgFctSts 3 "LvlgFctSts_Functionoff" 2 "LvlgFctSts_FunctionStandby" 1 "LvlgFctSts_FunctionOn" 0 "LvlgFctSts_Default";
VAL_ 535 FullActvSuspFailrStsSuspFailrSts 7 "SuspFailrStsTyp2_VehLvlHiOrLoErr" 6 "SuspFailrStsTyp2_HiAirM" 5 "SuspFailrStsTyp2_LoAirM" 4 "SuspFailrStsTyp2_StopCritErr" 3 "SuspFailrStsTyp2_SrvRqrdErr" 2 "SuspFailrStsTyp2_CmprOvrheatd" 1 "SuspFailrStsTyp2_TrSwtConUsg" 0 "SuspFailrStsTyp2_NoErr";
VAL_ 535 FullActvSuspFailrStsSuspFailrStsTypQf 3 "GenQf1_AccurData" 2 "GenQf1_DataAccurNotWithinSpcn" 1 "GenQf1_TmpUndefdData" 0 "GenQf1_UndefindDataAccur";
VAL_ 535 FullActvSuspHeilvlindcn 4 "SuspHeiLvlCtrl_LL2" 3 "SuspHeiLvlCtrl_LL1" 2 "SuspHeiLvlCtrl_HL1" 1 "SuspHeiLvlCtrl_HL2" 0 "SuspHeiLvlCtrl_NRH";
VAL_ 535 FullActvSuspStabyCritFailrDetdSts 1 "NoYes1_Yes" 0 "NoYes1_No";
VAL_ 101 FullActvSuspPosnVertLeFrntQf 3 "GenQf1_AccurData" 2 "GenQf1_DataAccurNotWithinSpcn" 1 "GenQf1_TmpUndefdData" 0 "GenQf1_UndefindDataAccur";
VAL_ 101 FullActvSuspPosnVertLeReQf 3 "GenQf1_AccurData" 2 "GenQf1_DataAccurNotWithinSpcn" 1 "GenQf1_TmpUndefdData" 0 "GenQf1_UndefindDataAccur";
VAL_ 101 FullActvSuspPosnVertRiFrntQf 3 "GenQf1_AccurData" 2 "GenQf1_DataAccurNotWithinSpcn" 1 "GenQf1_TmpUndefdData" 0 "GenQf1_UndefindDataAccur";
VAL_ 101 FullActvSuspPosnVertRiReQf 3 "GenQf1_AccurData" 2 "GenQf1_DataAccurNotWithinSpcn" 1 "GenQf1_TmpUndefdData" 0 "GenQf1_UndefindDataAccur";
VAL_ 101 ZCUTToVMCAvl 1 "AvlSts2_Avl" 0 "AvlSts2_NotAvl";
VAL_ 266 FasCritPwrReq 1 "NoYes1_Yes" 0 "NoYes1_No";
VAL_ 1282 WakeUpReasonsforZCUT 741 "WakeupReasons_871868" 740 "WakeupReasons_871957" 739 "WakeupReasons_871729" 738 "WakeupReasons_700779" 737 "WakeupReasons_839414" 736 "WakeupReasons_675025" 735 "WakeupReasons_671146" 734 "WakeupReasons_1031929" 733 "WakeupReasons_1033548" 732 "WakeupReasons_1033537" 731 "WakeupReasons_1033479" 730 "WakeupReasons_1030765" 729 "WakeupReasons_1028674" 728 "WakeupReasons_1033567" 727 "WakeupReasons_1033543" 726 "WakeupReasons_1033549" 725 "WakeupReasons_1033554" 724 "WakeupReasons_1033563" 723 "WakeupReasons_1033558" 722 "WakeupReasons_1029384" 721 "WakeupReasons_1029383" 720 "WakeupReasons_1029382" 719 "WakeupReasons_1032619" 718 "WakeupReasons_1024928" 717 "WakeupReasons_1033547" 716 "WakeupReasons_1033541" 715 "WakeupReasons_1033562" 714 "WakeupReasons_1033564" 713 "WakeupReasons_986765" 712 "WakeupReasons_1026103" 711 "WakeupReasons_1030764" 710 "WakeupReasons_1030941" 709 "WakeupReasons_1033556" 708 "WakeupReasons_1033539" 707 "WakeupReasons_1033534" 706 "WakeupReasons_1032477" 705 "WakeupReasons_1031280" 704 "WakeupReasons_1033542" 703 "WakeupReasons_1033632" 702 "WakeupReasons_1033533" 701 "WakeupReasons_1029166" 700 "WakeupReasons_1033538" 699 "WakeupReasons_1031789" 698 "WakeupReasons_1033552" 697 "WakeupReasons_1033553" 696 "WakeupReasons_1033559" 695 "WakeupReasons_1033544" 694 "WakeupReasons_1033561" 693 "WakeupReasons_1031029" 692 "WakeupReasons_1030360" 691 "WakeupReasons_1030761" 690 "WakeupReasons_1033550" 689 "WakeupReasons_1032579" 688 "WakeupReasons_1033557" 687 "WakeupReasons_1031936" 686 "WakeupReasons_1033566" 685 "WakeupReasons_1033551" 684 "WakeupReasons_1033540" 683 "WakeupReasons_1030760" 682 "WakeupReasons_1029735" 681 "WakeupReasons_1033565" 680 "WakeupReasons_852370" 679 "WakeupReasons_1033555" 678 "WakeupReasons_1033546" 677 "WakeupReasons_1032743" 676 "WakeupReasons_1032791" 675 "WakeupReasons_1033569" 674 "WakeupReasons_1031030" 673 "WakeupReasons_1028778" 672 "WakeupReasons_1030759" 671 "WakeupReasons_1031907" 670 "WakeupReasons_1033560" 669 "WakeupReasons_1031288" 668 "WakeupReasons_1030302" 667 "WakeupReasons_1031765" 666 "WakeupReasons_1031990" 665 "WakeupReasons_1028729" 664 "WakeupReasons_1030362" 663 "WakeupReasons_1030361" 662 "WakeupReasons_1030297" 661 "WakeupReasons_1030293" 660 "WakeupReasons_527345" 659 "WakeupReasons_988154" 658 "WakeupReasons_533580" 657 "WakeupReasons_533581" 656 "WakeupReasons_533576" 655 "WakeupReasons_1030255" 654 "WakeupReasons_527348" 653 "WakeupReasons_533578" 652 "WakeupReasons_527347" 651 "WakeupReasons_527346" 650 "WakeupReasons_ADCUReserve" 649 "WakeupReasons_885767" 648 "WakeupReasons_909025" 647 "WakeupReasons_909026" 646 "WakeupReasons_858177" 645 "WakeupReasons_858169" 644 "WakeupReasons_858152" 643 "WakeupReasons_973575" 642 "WakeupReason_973574" 641 "WakeupReason_987405" 640 "WakeupReason_858187" 639 "WakeupReason_988826" 638 "WakeupReason_988821" 637 "WakeupReason_987485" 636 "WakeupReason_908128" 635 "WakeupReason_908115" 634 "WakeupReason_856234" 633 "WakeupReason_856224" 632 "WakeupReason_858189" 631 "WakeupReason_858188" 630 "WakeupReason_872056" 629 "WakeupReason_870276" 628 "WakeupReason_858191" 627 "WakeupReason_847054" 626 "WakeupReason_856465" 625 "WakeupReason_872253" 624 "WakeupReason_855003" 623 "WakeupReason_855002" 622 "WakeupReason_854947" 621 "WakeupReason_855134" 620 "WakeupReason_854839" 619 "WakeupReason_854999" 618 "WakeupReason_855029" 617 "WakeupReason_714340" 616 "WakeupReason_852947" 615 "WakeupReason_852944" 614 "WakeupReason_852646" 613 "WakeupReason_852537" 612 "WakeupReason_852388" 611 "WakeupReason_852385" 610 "WakeupReason_852298" 609 "WakeupReason_852273" 608 "WakeupReason_852248" 607 "WakeupReason_852219" 606 "WakeupReason_852218" 605 "WakeupReason_852215" 604 "WakeupReason_852200" 603 "WakeupReason_852195" 602 "WakeupReason_852194" 601 "WakeupReason_852184" 600 "WakeupReason_852180" 599 "WakeupReason_852050" 598 "WakeupReason_852010" 597 "WakeupReason_851743" 596 "WakeupReason_851482" 595 "WakeupReason_702420" 594 "WakeupReason_667533" 593 "WakeupReason_645735" 592 "WakeupReason_362462" 591 "WakeupReason_361474" 590 "WakeupReason_361441" 589 "WakeupReason_846002" 588 "WakeupReason_845930" 587 "WakeupReason_842273" 586 "WakeupReason_846372" 585 "WakeupReason_675489" 584 "WakeupReason_675452" 583 "WakeupReason_298032" 582 "WakeupReason_322113" 581 "WakeupReason_320145" 580 "WakeupReason_841275" 579 "WakeupReason_839787" 578 "WakeupReason_839181" 577 "WakeupReason_714677" 576 "WakeupReason_840035" 566 "WakeupReason_839458" 565 "WakeupReason_837760" 564 "WakeupReason_702903" 563 "WakeupReason_837962" 562 "WakeupReason_703140" 561 "WakeupReason_837833" 560 "WakeupReason_839705" 559 "WakeupReason_839473" 558 "WakeupReason_838116" 557 "WakeupReason_717832" 556 "WakeupReason_714697" 555 "WakeupReason_714799" 554 "WakeupReason_714806" 553 "WakeupReason_709196" 552 "WakeupReason_710893" 551 "WakeupReason_708964" 550 "WakeupReason_715529" 549 "WakeupReason_714265" 548 "WakeupReason_714172" 547 "WakeupReason_713799" 546 "WakeupReason_706194" 545 "WakeupReason_713568" 544 "WakeupReason_710807" 543 "WakeupReason_714679" 542 "WakeupReason_714678" 541 "WakeupReason_715842" 540 "WakeupReason_714030" 539 "WakeupReason_710922" 538 "WakeupReason_716243" 537 "WakeupReason_713786" 536 "WakeupReason_714675" 535 "WakeupReason_702478" 534 "WakeupReason_713752" 533 "WakeupReasons_700530" 532 "WakeupReasons_698631" 531 "WakeupReasons_702452" 530 "WakeupReasons_700565" 529 "WakeupReasons_702402" 528 "WakeupReasons_702439" 527 "WakeupReasons_702448" 526 "WakeupReasons_701872" 525 "WakeupReasons_699114" 524 "WakeupReasons_702240" 523 "WakeupReasons_701270" 522 "WakeupReasons_533751" 521 "WakeupReasons_698581" 520 "WakeupReasons_698130" 519 "WakeupReasons_700130" 518 "WakeupReasons_699921" 517 "WakeupReasons_699919" 516 "WakeupReasons_700486" 515 "WakeupReasons_700782" 514 "WakeupReasons_696971" 513 "WakeupReasons_700692" 512 "WakeupReasons_698385" 511 "WakeupReasons_699922" 510 "WakeupReasons_697967" 509 "WakeupReasons_700684" 508 "WakeupReasons_644379" 507 "WakeupReasons_336435" 506 "WakeupReasons_683263" 505 "WakeupReasons_700554" 504 "WakeupReasons_691992" 503 "WakeupReasons_698129" 502 "WakeupReasons_696850" 501 "WakeupReasons_702088" 500 "WakeupReasons_696612" 499 "WakeupReasons_691994" 498 "WakeupReasons_700483" 497 "WakeupReasons_702204" 496 "WakeupReasons_700603" 495 "WakeupReasons_700215" 494 "WakeupReasons_701509" 493 "WakeupReasons_701508" 492 "WakeupReasons_700484" 491 "WakeupReasons_217907" 490 "WakeupReasons_194966" 489 "WakeupReasons_702174" 488 "WakeupReasons_697145" 487 "WakeupReasons_296931" 486 "WakeupReasons_700687" 485 "WakeupReasons_700686" 484 "WakeupReasons_698409" 483 "WakeupReasons_533750" 482 "WakeupReasons_700467" 481 "WakeupReasons_687404" 480 "WakeupReasons_681813" 479 "WakeupReasons_698288" 478 "WakeupReasons_698660" 477 "WakeupReasons_691993" 476 "WakeupReasons_700485" 475 "WakeupReasons_700425" 474 "WakeupReasons_702197" 473 "WakeupReasons_637992" 472 "WakeupReasons_698488" 471 "WakeupReasons_691991" 470 "WakeupReasons_692547" 469 "WakeupReasons_693914" 468 "WakeupReasons_693024" 467 "WakeupReasons_693005" 466 "WakeupReasons_667949" 465 "WakeupReasons_686281" 464 "WakeupReasons_680764" 463 "WakeupReasons_512384" 462 "WakeupReasons_692019" 461 "WakeupReasons_533850" 460 "WakeupReasons_533849" 459 "WakeupReasons_667188" 458 "WakeupReasons_514652" 457 "WakeupReasons_514651" 456 "WakeupReasons_112024" 455 "WakeupReasons_300690" 454 "WakeupReasons_299532" 453 "WakeupReasons_299531" 452 "WakeupReasons_299120" 451 "WakeupReasons_273516" 450 "WakeupReasons_265694" 449 "WakeupReasons_692439" 448 "WakeupReasons_354831" 447 "WakeupReasons_680765" 446 "WakeupReasons_45895" 445 "WakeupReasons_644275" 444 "WakeupReasons_351189" 443 "WakeupReasons_226570" 442 "WakeupReasons_654489" 441 "WakeupReasons_110181" 440 "WakeupReasons_226569" 439 "WakeupReasons_45896" 438 "WakeupReasons_112031" 437 "WakeupReasons_110173" 436 "WakeupReasons_677781" 435 "WakeupReasons_690939" 434 "WakeupReasons_354809" 433 "WakeupReasons_692022" 432 "WakeupReasons_690593" 431 "WakeupReasons_226571" 430 "WakeupReasons_675594" 429 "WakeupReasons_226565" 428 "WakeupReasons_692020" 427 "WakeupReasons_112035" 426 "WakeupReasons_112027" 425 "WakeupReasons_354672" 424 "WakeupReasons_168967" 423 "WakeupReasons_354674" 422 "WakeupReasons_168968" 421 "WakeupReasons_641483" 420 "WakeupReasons_641482" 419 "WakeupReasons_265698" 418 "WakeupReasons_265699" 417 "WakeupReasons_360491" 416 "WakeupReasons_357498" 415 "WakeupReasons_170290" 414 "WakeupReasons_690385" 413 "WakeupReasons_692021" 412 "WakeupReasons_91254" 411 "WakeupReasons_346654" 410 "WakeupReasons_200637" 409 "WakeupReasons_170285" 408 "WakeupReasons_265678" 407 "WakeupReasons_683934" 406 "WakeupReasons_680763" 405 "WakeupReasons_682074" 404 "WakeupReasons_682154" 403 "WakeupReasons_682152" 402 "WakeupReasons_682155" 401 "WakeupReasons_682153" 400 "WakeupReasons_682078" 399 "WakeupReasons_682076" 398 "WakeupReasons_682077" 397 "WakeupReasons_676285" 396 "WakeupReasons_681023" 395 "WakeupReasons_682023" 394 "WakeupReasons_681789" 393 "WakeupReasons_682688" 392 "WakeupReasons_682037" 391 "WakeupReasons_682032" 390 "WakeupReasons_681915" 389 "WakeupReasons_674839" 388 "WakeupReasons_682034" 387 "WakeupReasons_681711" 386 "WakeupReasons_681031" 385 "WakeupReasons_681134" 384 "WakeupReasons_670462" 383 "WakeupReasons_681028" 382 "WakeupReasons_680975" 381 "WakeupReasons_680974" 380 "WakeupReasons_668523" 379 "WakeupReasons_669822" 378 "WakeupReasons_680712" 377 "WakeupReasons_671005" 376 "WakeupReasons_177214" 375 "WakeupReasons_45655" 374 "WakeupReasons_667872" 373 "WakeupReasons_264964" 372 "WakeupReasons_262871" 371 "WakeupReasons_264691" 370 "WakeupReasons_297056" 369 "WakeupReasons_233755" 368 "WakeupReasons_145161" 367 "WakeupReasons_667842" 366 "WakeupReasons_46020" 365 "WakeupReasons_667874" 364 "WakeupReasons_667981" 363 "WakeupReasons_224211" 362 "WakeupReasons_45902" 361 "WakeupReasons_329457" 360 "WakeupReasons_88458" 359 "WakeupReasons_45900" 358 "WakeupReasons_83199" 357 "WakeupReasons_532933" 356 "WakeupReasons_532932" 355 "WakeupReasons_670942" 354 "WakeupReasons_305818" 353 "WakeupReasons_75103" 352 "WakeupReasons_667987" 351 "WakeupReasons_667983" 350 "WakeupReasons_675745" 349 "WakeupReasons_356598" 348 "WakeupReasons_128671" 347 "WakeupReasons_69216" 346 "WakeupReasons_264697" 345 "WakeupReasons_264943" 344 "WakeupReasons_197644" 343 "WakeupReasons_675564" 342 "WakeupReasons_657120" 341 "WakeupReasons_265745" 340 "WakeupReasons_657121" 339 "WakeupReasons_667982" 338 "WakeupReasons_674223" 337 "WakeupReasons_127926" 336 "WakeupReasons_127924" 335 "WakeupReasons_262872" 334 "WakeupReasons_45848" 333 "WakeupReasons_45847" 332 "WakeupReasons_45846" 331 "WakeupReasons_667869" 330 "WakeupReasons_45890" 329 "WakeupReasons_45888" 328 "WakeupReasons_670962" 327 "WakeupReasons_667973" 326 "WakeupReasons_45877" 325 "WakeupReasons_667980" 324 "WakeupReasons_45876" 323 "WakeupReasons_45871" 322 "WakeupReasons_45875" 321 "WakeupReasons_45872" 320 "WakeupReasons_45870" 319 "WakeupReasons_45869" 318 "WakeupReasons_80608" 317 "WakeupReasons_45898" 316 "WakeupReasons_45897" 315 "WakeupReasons_69679" 314 "WakeupReasons_69678" 313 "WakeupReasons_45887" 312 "WakeupReasons_263473" 311 "WakeupReasons_265131" 310 "WakeupReasons_268983" 309 "WakeupReasons_139075" 308 "WakeupReasons_200090" 307 "WakeupReasons_199714" 306 "WakeupReasons_80609" 305 "WakeupReasons_106669" 304 "WakeupReasons_675742" 303 "WakeupReasons_46017" 302 "WakeupReasons_670354" 301 "WakeupReasons_667985" 300 "WakeupReasons_670966" 299 "WakeupReasons_667871" 298 "WakeupReasons_193474" 297 "WakeupReasons_113348" 296 "WakeupReasons_532556" 295 "WakeupReasons_532555" 294 "WakeupReasons_667988" 293 "WakeupReasons_182918" 292 "WakeupReasons_311279" 291 "WakeupReasons_667848" 290 "WakeupReasons_667850" 289 "WakeupReasons_668393" 288 "WakeupReasons_668395" 287 "WakeupReasons_670753" 286 "WakeupReasons_667922" 285 "WakeupReasons_669447" 284 "WakeupReasons_670928" 283 "WakeupReasons_669465" 282 "WakeupReasons_676265" 281 "WakeupReasons_667947" 280 "WakeupReasons_667879" 279 "WakeupReasons_675837" 278 "WakeupReasons_675494" 277 "WakeupReasons_674958" 276 "WakeupReasons_675064" 275 "WakeupReasons_674953" 274 "WakeupReasons_658188" 273 "WakeupReasons_337991" 272 "WakeupReasons_197653" 271 "WakeupReasons_269140" 270 "WakeupReasons_312881" 269 "WakeupReasons_215560" 268 "WakeupReasons_269034" 267 "WakeupReasons_4471" 266 "WakeupReasons_185490" 265 "WakeupReasons_185457" 264 "WakeupReasons_198452" 263 "WakeupReasons_200683" 262 "WakeupReasons_358832" 261 "WakeupReasons_NMPDUReceived" 260 "WakeupReasons_670345" 259 "WakeupReasons_109467" 258 "WakeupReasons_109466" 257 "WakeupReasons_636801" 256 "WakeupReasons_45849" 255 "WakeupReasons_45850" 254 "WakeupReasons_45851" 253 "WakeupReasons_45852" 252 "WakeupReasons_45854" 251 "WakeupReasons_45853" 250 "WakeupReasons_45856" 249 "WakeupReasons_533872" 248 "WakeupReasons_516327" 247 "WakeupReasons_359559" 246 "WakeupReasons_241902" 245 "WakeupReasons_533372" 244 "WakeupReasons_533371" 243 "WakeupReasons_533370" 242 "WakeupReasons_315981" 241 "WakeupReasons_45858" 240 "WakeupReasons_668529" 239 "WakeupReasons_670087" 238 "WakeupReasons_668531" 237 "WakeupReasons_223920" 236 "WakeupReasons_176748" 235 "WakeupReasons_146470" 234 "WakeupReasons_112799" 233 "WakeupReasons_95949" 232 "WakeupReasons_156440" 231 "WakeupReasons_166267" 230 "WakeupReasons_101727" 229 "WakeupReasons_101728" 228 "WakeupReasons_101725" 227 "WakeupReasons_101706" 226 "WakeupReasons_659350" 225 "WakeupReasons_667820" 224 "WakeupReasons_331194" 223 "WakeupReasons_652546" 222 "WakeupReasons_224553" 221 "WakeupReasons_224552" 220 "WakeupReasons_110885" 219 "WakeupReasons_667953" 218 "WakeupReasons_667962" 217 "WakeupReasons_224550" 216 "WakeupReasons_197665" 215 "WakeupReasons_225961" 214 "WakeupReasons_198433" 213 "WakeupReasons_526438" 212 "WakeupReasons_316796" 211 "WakeupReasons_335068" 210 "WakeupReasons_535214" 209 "WakeupReasons_264726" 208 "WakeupReasons_360542" 207 "WakeupReasons_531743" 206 "WakeupReasons_226967" 205 "WakeupReasons_318382" 204 "WakeupReasons_199159" 203 "WakeupReasons_223715" 202 "WakeupReasons_643973" 201 "WakeupReasons_319401" 200 "WakeupReasons_264712" 199 "WakeupReasons_526426" 198 "WakeupReasons_533050" 197 "WakeupReasons_265937" 196 "WakeupReasons_108834" 195 "WakeupReasons_636556" 194 "WakeupReasons_655340" 193 "WakeupReasons_320895" 192 "WakeupReasons_321077" 191 "WakeupReasons_321323" 190 "WakeupReasons_321319" 189 "WakeupReasons_321057" 188 "WakeupReasons_359187" 187 "WakeupReasons_321317" 186 "WakeupReasons_355214" 185 "WakeupReasons_652361" 184 "WakeupReasons_192030" 183 "WakeupReasons_534145" 182 "WakeupReasons_526445" 181 "WakeupReasons_360299" 180 "WakeupReasons_525705" 179 "WakeupReasons_534077" 178 "WakeupReasons_359211" 177 "WakeupReasons_300681" 176 "WakeupReasons_198484" 175 "WakeupReasons_356549" 174 "WakeupReasons_360543" 173 "WakeupReasons_318342" 172 "WakeupReasons_299547" 171 "WakeupReasons_646109" 170 "WakeupReasons_645753" 169 "WakeupReasons_514502" 168 "WakeupReasons_515804" 167 "WakeupReasons_298808" 166 "WakeupReasons_265330" 165 "WakeupReasons_265328" 164 "WakeupReasons_265305" 163 "WakeupReasons_361279" 162 "WakeupReasons_361272" 161 "WakeupReasons_160596" 160 "WakeupReasons_197648" 159 "WakeupReasons_658603" 158 "WakeupReasons_322857" 157 "WakeupReasons_108810" 156 "WakeupReasons_179103" 155 "WakeupReasons_321845" 154 "WakeupReasons_340667" 153 "WakeupReasons_299117" 152 "WakeupReasons_514503" 151 "WakeupReasons_532007" 150 "WakeupReasons_337565" 149 "WakeupReasons_320631" 148 "WakeupReasons_354791" 147 "WakeupReasons_317616" 146 "WakeupReasons_644550" 145 "WakeupReasons_265232" 144 "WakeupReasons_514545" 143 "WakeupReasons_526429" 142 "WakeupReasons_265569" 141 "WakeupReasons_108841" 140 "WakeupReasons_160602" 139 "WakeupReasons_160597" 138 "WakeupReasons_264958" 137 "WakeupReasons_300682" 136 "WakeupReasons_224634" 135 "WakeupReasons_224617" 134 "WakeupReasons_220322" 133 "WakeupReasons_300427" 132 "WakeupReasons_269156" 131 "WakeupReasons_145462" 130 "WakeupReasons_145454" 129 "WakeupReasons_145419" 128 "WakeupReasons_145288" 127 "WakeupReasons_145373" 126 "WakeupReasons_145385" 125 "WakeupReasons_145362" 124 "WakeupReasons_145399" 123 "WakeupReasons_145388" 122 "WakeupReasons_145330" 121 "WakeupReasons_152774" 120 "WakeupReasons_145319" 119 "WakeupReasons_145311" 118 "WakeupReasons_106774" 117 "WakeupReasons_533044" 116 "WakeupReasons_636692" 115 "WakeupReasons_355409" 114 "WakeupReasons_133749" 113 "WakeupReasons_156412" 112 "WakeupReasons_320287" 111 "WakeupReasons_201348" 110 "WakeupReasons_264962" 109 "WakeupReasons_169884" 108 "WakeupReasons_45867" 107 "WakeupReasons_45866" 106 "WakeupReasons_659549" 105 "WakeupReasons_45864" 104 "WakeupReasons_201815" 103 "WakeupReasons_224831" 102 "WakeupReasons_222553" 101 "WakeupReasons_140678" 100 "WakeupReasons_169945" 99 "WakeupReasons_95444" 98 "WakeupReasons_145688" 97 "WakeupReasons_356190" 96 "WakeupReasons_264934" 95 "WakeupReasons_264932" 94 "WakeupReasons_152786" 93 "WakeupReasons_144970" 92 "WakeupReasons_186489" 91 "WakeupReasons_144897" 90 "WakeupReasons_199172" 89 "WakeupReasons_145707" 88 "WakeupReasons_152237" 87 "WakeupReasons_67182" 86 "WakeupReasons_338820" 85 "WakeupReasons_634710" 84 "WakeupReasons_109387" 83 "WakeupReasons_320126" 82 "WakeupReasons_109367" 81 "WakeupReasons_315364" 80 "WakeupReasons_297868" 79 "WakeupReasons_645810" 78 "WakeupReasons_634696" 77 "WakeupReasons_138997" 76 "WakeupReasons_360006" 75 "WakeupReasons_224061" 74 "WakeupReasons_68481" 73 "WakeupReasons_109364" 72 "WakeupReasons_68644" 71 "WakeupReasons_224065" 70 "WakeupReasons_119273" 69 "WakeupReasons_109382" 68 "WakeupReasons_360008" 67 "WakeupReasons_68676" 66 "WakeupReasons_645094" 65 "WakeupReasons_361509" 64 "WakeupReasons_361505" 63 "WakeupReasons_360904" 62 "WakeupReasons_355601" 61 "WakeupReasons_320277" 60 "WakeupReasons_319422" 59 "WakeupReasons_320282" 58 "WakeupReasons_169894" 57 "WakeupReasons_266860" 56 "WakeupReasons_45656" 55 "WakeupReasons_21997" 54 "WakeupReasons_225696" 53 "WakeupReasons_200156" 52 "WakeupReasons_161066" 51 "WakeupReasons_185670" 50 "WakeupReasons_197826" 49 "WakeupReasons_176921" 48 "WakeupReasons_108776" 47 "WakeupReasons_265333" 46 "WakeupReasons_100281" 45 "WakeupReasons_100278" 44 "WakeupReasons_100300" 43 "WakeupReasons_100275" 42 "WakeupReasons_100298" 41 "WakeupReasons_319139" 40 "WakeupReasons_170807" 39 "WakeupReasons_200937" 38 "WakeupReasons_182033" 37 "WakeupReasons_191050" 36 "WakeupReasons_264876" 35 "WakeupReasons_197642" 34 "WakeupReasons_170865" 33 "WakeupReasons_168966" 32 "WakeupReasons_667948" 31 "WakeupReasons_169655" 30 "WakeupReasons_667945" 29 "WakeupReasons_74188" 28 "WakeupReasons_321583" 27 "WakeupReasons_88125" 26 "WakeupReasons_88123" 25 "WakeupReasons_91253" 24 "WakeupReasons_21973" 23 "WakeupReasons_140084" 22 "WakeupReasons_45657" 21 "WakeupReasons_45659" 20 "WakeupReasons_22100" 19 "WakeupReasons_22013" 18 "WakeupReasons_22005" 17 "WakeupReasons_45794" 16 "WakeupReasons_45793" 15 "WakeupReasons_21901" 14 "WakeupReasons_658500" 13 "WakeupReasons_269739" 12 "WakeupReasons_269735" 11 "WakeupReasons_269740" 10 "WakeupReasons_22060" 9 "WakeupReasons_49446" 8 "WakeupReasons_22058" 7 "WakeupReasons_45654" 6 "WakeupReasons_264933" 5 "WakeupReasons_197643" 4 "WakeupReasons_168965" 3 "WakeupReasons_667951" 2 "WakeupReasons_169654" 1 "WakeupReasons_667950" 0 "WakeupReasons_0";
VAL_ 1346 VFCVectorZCUTVFCid0 1 "VFCOnOff_On" 0 "VFCOnOff_Off";
VAL_ 1346 VFCVectorZCUTVFCid1 1 "VFCOnOff_On" 0 "VFCOnOff_Off";
VAL_ 1346 VFCVectorZCUTVFCid10 1 "VFCOnOff_On" 0 "VFCOnOff_Off";
VAL_ 1346 VFCVectorZCUTVFCid11 1 "VFCOnOff_On" 0 "VFCOnOff_Off";
VAL_ 1346 VFCVectorZCUTVFCid12 1 "VFCOnOff_On" 0 "VFCOnOff_Off";
VAL_ 1346 VFCVectorZCUTVFCid13 1 "VFCOnOff_On" 0 "VFCOnOff_Off";
VAL_ 1346 VFCVectorZCUTVFCid14 1 "VFCOnOff_On" 0 "VFCOnOff_Off";
VAL_ 1346 VFCVectorZCUTVFCid15 1 "VFCOnOff_On" 0 "VFCOnOff_Off";
VAL_ 1346 VFCVectorZCUTVFCid16 1 "VFCOnOff_On" 0 "VFCOnOff_Off";
VAL_ 1346 VFCVectorZCUTVFCid17 1 "VFCOnOff_On" 0 "VFCOnOff_Off";
VAL_ 1346 VFCVectorZCUTVFCid18 1 "VFCOnOff_On" 0 "VFCOnOff_Off";
VAL_ 1346 VFCVectorZCUTVFCid19 1 "VFCOnOff_On" 0 "VFCOnOff_Off";
VAL_ 1346 VFCVectorZCUTVFCid2 1 "VFCOnOff_On" 0 "VFCOnOff_Off";
VAL_ 1346 VFCVectorZCUTVFCid20 1 "VFCOnOff_On" 0 "VFCOnOff_Off";
VAL_ 1346 VFCVectorZCUTVFCid21 1 "VFCOnOff_On" 0 "VFCOnOff_Off";
VAL_ 1346 VFCVectorZCUTVFCid22 1 "VFCOnOff_On" 0 "VFCOnOff_Off";
VAL_ 1346 VFCVectorZCUTVFCid23 1 "VFCOnOff_On" 0 "VFCOnOff_Off";
VAL_ 1346 VFCVectorZCUTVFCid24 1 "VFCOnOff_On" 0 "VFCOnOff_Off";
VAL_ 1346 VFCVectorZCUTVFCid25 1 "VFCOnOff_On" 0 "VFCOnOff_Off";
VAL_ 1346 VFCVectorZCUTVFCid26 1 "VFCOnOff_On" 0 "VFCOnOff_Off";
VAL_ 1346 VFCVectorZCUTVFCid27 1 "VFCOnOff_On" 0 "VFCOnOff_Off";
VAL_ 1346 VFCVectorZCUTVFCid28 1 "VFCOnOff_On" 0 "VFCOnOff_Off";
VAL_ 1346 VFCVectorZCUTVFCid29 1 "VFCOnOff_On" 0 "VFCOnOff_Off";
VAL_ 1346 VFCVectorZCUTVFCid3 1 "VFCOnOff_On" 0 "VFCOnOff_Off";
VAL_ 1346 VFCVectorZCUTVFCid30 1 "VFCOnOff_On" 0 "VFCOnOff_Off";
VAL_ 1346 VFCVectorZCUTVFCid31 1 "VFCOnOff_On" 0 "VFCOnOff_Off";
VAL_ 1346 VFCVectorZCUTVFCid32 1 "VFCOnOff_On" 0 "VFCOnOff_Off";
VAL_ 1346 VFCVectorZCUTVFCid33 1 "VFCOnOff_On" 0 "VFCOnOff_Off";
VAL_ 1346 VFCVectorZCUTVFCid34 1 "VFCOnOff_On" 0 "VFCOnOff_Off";
VAL_ 1346 VFCVectorZCUTVFCid35 1 "VFCOnOff_On" 0 "VFCOnOff_Off";
VAL_ 1346 VFCVectorZCUTVFCid36 1 "VFCOnOff_On" 0 "VFCOnOff_Off";
VAL_ 1346 VFCVectorZCUTVFCid37 1 "VFCOnOff_On" 0 "VFCOnOff_Off";
VAL_ 1346 VFCVectorZCUTVFCid38 1 "VFCOnOff_On" 0 "VFCOnOff_Off";
VAL_ 1346 VFCVectorZCUTVFCid39 1 "VFCOnOff_On" 0 "VFCOnOff_Off";
VAL_ 1346 VFCVectorZCUTVFCid4 1 "VFCOnOff_On" 0 "VFCOnOff_Off";
VAL_ 1346 VFCVectorZCUTVFCid40 1 "VFCOnOff_On" 0 "VFCOnOff_Off";
VAL_ 1346 VFCVectorZCUTVFCid41 1 "VFCOnOff_On" 0 "VFCOnOff_Off";
VAL_ 1346 VFCVectorZCUTVFCid42 1 "VFCOnOff_On" 0 "VFCOnOff_Off";
VAL_ 1346 VFCVectorZCUTVFCid43 1 "VFCOnOff_On" 0 "VFCOnOff_Off";
VAL_ 1346 VFCVectorZCUTVFCid44 1 "VFCOnOff_On" 0 "VFCOnOff_Off";
VAL_ 1346 VFCVectorZCUTVFCid45 1 "VFCOnOff_On" 0 "VFCOnOff_Off";
VAL_ 1346 VFCVectorZCUTVFCid46 1 "VFCOnOff_On" 0 "VFCOnOff_Off";
VAL_ 1346 VFCVectorZCUTVFCid47 1 "VFCOnOff_On" 0 "VFCOnOff_Off";
VAL_ 1346 VFCVectorZCUTVFCid48 1 "VFCOnOff_On" 0 "VFCOnOff_Off";
VAL_ 1346 VFCVectorZCUTVFCid49 1 "VFCOnOff_On" 0 "VFCOnOff_Off";
VAL_ 1346 VFCVectorZCUTVFCid5 1 "VFCOnOff_On" 0 "VFCOnOff_Off";
VAL_ 1346 VFCVectorZCUTVFCid50 1 "VFCOnOff_On" 0 "VFCOnOff_Off";
VAL_ 1346 VFCVectorZCUTVFCid51 1 "VFCOnOff_On" 0 "VFCOnOff_Off";
VAL_ 1346 VFCVectorZCUTVFCid52 1 "VFCOnOff_On" 0 "VFCOnOff_Off";
VAL_ 1346 VFCVectorZCUTVFCid53 1 "VFCOnOff_On" 0 "VFCOnOff_Off";
VAL_ 1346 VFCVectorZCUTVFCid54 1 "VFCOnOff_On" 0 "VFCOnOff_Off";
VAL_ 1346 VFCVectorZCUTVFCid55 1 "VFCOnOff_On" 0 "VFCOnOff_Off";
VAL_ 1346 VFCVectorZCUTVFCid56 1 "VFCOnOff_On" 0 "VFCOnOff_Off";
VAL_ 1346 VFCVectorZCUTVFCid57 1 "VFCOnOff_On" 0 "VFCOnOff_Off";
VAL_ 1346 VFCVectorZCUTVFCid58 1 "VFCOnOff_On" 0 "VFCOnOff_Off";
VAL_ 1346 VFCVectorZCUTVFCid59 1 "VFCOnOff_On" 0 "VFCOnOff_Off";
VAL_ 1346 VFCVectorZCUTVFCid6 1 "VFCOnOff_On" 0 "VFCOnOff_Off";
VAL_ 1346 VFCVectorZCUTVFCid60 1 "VFCOnOff_On" 0 "VFCOnOff_Off";
VAL_ 1346 VFCVectorZCUTVFCid61 1 "VFCOnOff_On" 0 "VFCOnOff_Off";
VAL_ 1346 VFCVectorZCUTVFCid7 1 "VFCOnOff_On" 0 "VFCOnOff_Off";
VAL_ 1346 VFCVectorZCUTVFCid8 1 "VFCOnOff_On" 0 "VFCOnOff_Off";
VAL_ 1346 VFCVectorZCUTVFCid9 1 "VFCOnOff_On" 0 "VFCOnOff_Off";
SIG_GROUP_ 85 GVMCVehVAct 1 : GVMCVehVActLatAct GVMCVehVActQf GVMCVehVActLgtAct;
SIG_GROUP_ 85 GVMCPrpsnTqDistReq 1 : GVMCPrpsnTqDistReqDistReq GVMCPrpsnTqDistReqCtrlMod GVMCPrpsnTqDistReqCntr GVMCPrpsnTqDistReqChks;
SIG_GROUP_ 85 WhlFastSpdSafe 1 : WhlFastSpdSafeA WhlFastSpdSafeQF WhlFastSpdSafeCntr WhlFastSpdSafeChks;
SIG_GROUP_ 85 GVMCSteerWhlAgReqFrnt 1 : GVMCSteerWhlAgReqFrntSteerWhlCtrlSts GVMCSteerWhlAgReqFrntSteerWhlTqCtrl GVMCSteerWhlAgReqFrntChks GVMCSteerWhlAgReqFrntSteerWhlAgCtrl GVMCSteerWhlAgReqFrntCntr;
SIG_GROUP_ 85 WhlRotToothCntr 1 : WhlRotToothCntrCntr WhlRotToothCntrReLe WhlRotToothCntrFrntRi WhlRotToothCntrFrntLe WhlRotToothCntrReRi WhlRotToothCntrChks;
SIG_GROUP_ 85 VehMtnSt 1 : VehMtnStChks VehMtnStCntr VehMtnStVehMtnSt;
SIG_GROUP_ 85 SteerWhlSnsr 1 : SteerWhlSnsrAgSpd SteerWhlSnsrChks SteerWhlSnsrAg SteerWhlSnsrQf SteerWhlSnsrCntr;
SIG_GROUP_ 85 LatCtrlReqSafe 1 : LatCtrlReqSafeSteerWhlHptcWarnReq LatCtrlReqSafeCntr LatCtrlReqSafeChks LatCtrlReqSafeLatCtrlModReq LatCtrlReqSafeSteerTqReq;
SIG_GROUP_ 85 VehModMngtGlbSafe1 1 : VehModMngtGlbSafe1Cntr VehModMngtGlbSafe1PwrLvlElecSubtyp VehModMngtGlbSafe1EgyLvlElecMai VehModMngtGlbSafe1PwrLvlElecMai VehModMngtGlbSafe1FltEgyCnsWdSts VehModMngtGlbSafe1Chks VehModMngtGlbSafe1EgyLvlElecSubtyp VehModMngtGlbSafe1CarModSts1 VehModMngtGlbSafe1CarModSubtypWdCarModSubtyp VehModMngtGlbSafe1UsgModSts;
SIG_GROUP_ 85 GVMCVehCtrlrSts 1 : GVMCVehCtrlrStsCntr GVMCVehCtrlrStsChks GVMCVehCtrlrStsCtrlrSts;
SIG_GROUP_ 85 EscSt 1 : EscStCntr EscStChks EscStEscSt;
SIG_GROUP_ 85 GVMCYawRateCOGAct 1 : GVMCYawRateCOGActQf GVMCYawRateCOGActAct;
SIG_GROUP_ 85 VehSpdLgt 1 : VehSpdLgtChks VehSpdLgtA VehSpdLgtCntr VehSpdLgtQf;
SIG_GROUP_ 339 DrvrGearShiftDirReq1 1 : DrvrGearShiftDirReq1UpUpTipAut DrvrGearShiftDirReq1PosnAut DrvrGearShiftDirReq1Chks DrvrGearShiftDirReq1DwnTipAut DrvrGearShiftDirReq1UpTipAut DrvrGearShiftDirReq1Cntr DrvrGearShiftDirReq1DwnDwnTipAut;
SIG_GROUP_ 339 SteerSetg 1 : SteerSetgSteerAsscLvl SteerSetgSteerMod SteerSetgPen;
SIG_GROUP_ 339 RWASteerLockReq 1 : RWASteerLockReqSteerLockDataReq3 RWASteerLockReqSteerLockDataReq1 RWASteerLockReqSteerLockDataReq2 RWASteerLockReqSteerLockDataReq0 RWASteerLockReqSteerLockDataReq6 RWASteerLockReqSteerLockDataReq4 RWASteerLockReqCommand RWASteerLockReqSteerLockDataReq5;
SIG_GROUP_ 339 ZCAirSuspCtrlSts 1 : ZCAirSuspCtrlStsZCAirSuspCtrlSts ZCAirSuspCtrlStsChks ZCAirSuspCtrlStsCntr;
SIG_GROUP_ 339 SuspStfnVlvCtrlSts 1 : SuspStfnVlvCtrlStsRR SuspStfnVlvCtrlStsFR SuspStfnVlvCtrlStsFL SuspStfnVlvCtrlStsRL;
SIG_GROUP_ 339 DrvrGearShiftDirReq2 1 : DrvrGearShiftDirReq2DwnDwnTipAut DrvrGearShiftDirReq2DwnTipAut DrvrGearShiftDirReq2UpUpTipAut DrvrGearShiftDirReq2UpTipAut DrvrGearShiftDirReq2Chks DrvrGearShiftDirReq2PosnAut DrvrGearShiftDirReq2Cntr;
SIG_GROUP_ 339 SuspDistbnVlvCtrlSts 1 : SuspDistbnVlvCtrlStsSuspDistbnVlvCtrlSts SuspDistbnVlvCtrlStsChks SuspDistbnVlvCtrlStsCntr;
SIG_GROUP_ 289 BrkPedlPsd 1 : BrkPedlPsdBrkPedlNotPsdSafe BrkPedlPsdChks BrkPedlPsdCntr BrkPedlPsdQf BrkPedlPsdBrkPedlPsd;
SIG_GROUP_ 1173 TiAndDateIndcn 1 : TiAndDateIndcnMins1 TiAndDateIndcnSec1 TiAndDateIndcnDataValid TiAndDateIndcnHr1 TiAndDateIndcnYr1 TiAndDateIndcnMth1 TiAndDateIndcnDay;
SIG_GROUP_ 1173 VehBattU 1 : VehBattUSysU VehBattUSysUQf;
SIG_GROUP_ 569 LockgCenSts 1 : LockgCenStsUpdEve LockgCenStsTrigSrc LockgCenStsLockSt;
SIG_GROUP_ 569 PtTqAtWhlFrntAct 1 : PtTqAtWhlFrntActPtTqAtWhlFrntLeAct PtTqAtWhlFrntActPtTqAtAxleFrntAct PtTqAtWhlFrntActCntr PtTqAtWhlFrntActPtTqAtWhlsFrntQly PtTqAtWhlFrntActChks PtTqAtWhlFrntActPtTqAtWhlFrntRiAct;
SIG_GROUP_ 625 AmbTRaw 1 : AmbTRawQly AmbTRawAmbTVal;
SIG_GROUP_ 131 DPAAgReqGroup 1 : DPAAgReqGroupCntr DPAAgReqGroupVehAtaRtonlAg DPAAgReqGroupChks DPAAgReqGroupRtonAgReq DPAAgReqGroupTrgtAg;
SIG_GROUP_ 131 DPAAgReqGroup1 1 : DPAAgReqGroup1Chks DPAAgReqGroup1RtonAgReq DPAAgReqGroup1TrgtAg DPAAgReqGroup1VehAtaRtonlAg DPAAgReqGroup1Cntr;
SIG_GROUP_ 102 GVMCPrpsnTqDistbnReqAtAxleRe 1 : GVMCPrpsnTqDistbnReqAtAxleReDistReq GVMCPrpsnTqDistbnReqAtAxleReChks GVMCPrpsnTqDistbnReqAtAxleReCtrlMod GVMCPrpsnTqDistbnReqAtAxleReCntr;
SIG_GROUP_ 102 PVMCVehCtrlSts2 1 : PVMCVehCtrlSts2DecelReqActrSts PVMCVehCtrlSts2FloatingDrvgFctSts PVMCVehCtrlSts2CrabMovgFctSts PVMCVehCtrlSts2BrkTqDeltaFctSts PVMCVehCtrlSts2SbWBackUpLgtFctSts PVMCVehCtrlSts2VDSWFctSts PVMCVehCtrlSts2BrkDiscClngFctSts PVMCVehCtrlSts2Cntr PVMCVehCtrlSts2TankTurnFctSts PVMCVehCtrlSts2ViolentModFctSts PVMCVehCtrlSts2SbWBackUpLatFctSts PVMCVehCtrlSts2Chks PVMCVehCtrlSts2BbWBackUpFctSts PVMCVehCtrlSts2LowSpdStrFctSts PVMCVehCtrlSts2ActrTarFctSts;
SIG_GROUP_ 102 WhlSpdCircumlFrnt 1 : WhlSpdCircumlFrntLe WhlSpdCircumlFrntLeQf WhlSpdCircumlFrntCntr WhlSpdCircumlFrntChks WhlSpdCircumlFrntRiQf WhlSpdCircumlFrntWhlSpdCircumlFrntRi;
SIG_GROUP_ 102 WhlSpdCircumlRe 1 : WhlSpdCircumlReRiQf WhlSpdCircumlReRi WhlSpdCircumlReLeQf WhlSpdCircumlReCntr WhlSpdCircumlReLe WhlSpdCircumlReChks;
SIG_GROUP_ 102 AbsCtrlActv 1 : AbsCtrlActvCtrlSts1 AbsCtrlActvChks AbsCtrlActvCntr;
SIG_GROUP_ 102 PVMCSuspHeiCtrlReq 1 : PVMCSuspHeiCtrlReqGVMCSuspPosnModReq PVMCSuspHeiCtrlReqGVMCSuspPosnFLReq PVMCSuspHeiCtrlReqGVMCSuspPosnRRReq PVMCSuspHeiCtrlReqGVMCSuspPosnRLReq PVMCSuspHeiCtrlReqGVMCSuspPosnCtrlMod PVMCSuspHeiCtrlReqGVMCSuspPosnFRReq;
SIG_GROUP_ 102 GVMCSuspDampgCtrlReq 1 : GVMCSuspDampgCtrlReqGVMCSuspDampgCtrlMod GVMCSuspDampgCtrlReqGVMCDampgCtrlReqRL GVMCSuspDampgCtrlReqGVMCDampgCtrlReqRR GVMCSuspDampgCtrlReqGVMCSuspDampgModReq GVMCSuspDampgCtrlReqGVMCDampgCtrlReqFL GVMCSuspDampgCtrlReqGVMCDampgCtrlReqFR;
SIG_GROUP_ 549 VehCfgPrmExt2 1 : VehCfgPrmExt2CCPBytePosn2 VehCfgPrmExt2CCPBytePosn3 VehCfgPrmExt2CCPBytePosn4 VehCfgPrmExt2BlkIDBytePosn1 VehCfgPrmExt2CCPBytePosn6 VehCfgPrmExt2CCPBytePosn8 VehCfgPrmExt2CCPBytePosn7 VehCfgPrmExt2CCPBytePosn5;
SIG_GROUP_ 549 VehCfgPrmExt 1 : VehCfgPrmExtCCPBytePosn6 VehCfgPrmExtBlkIDBytePosn1 VehCfgPrmExtCCPBytePosn8 VehCfgPrmExtCCPBytePosn4 VehCfgPrmExtCCPBytePosn2 VehCfgPrmExtCCPBytePosn7 VehCfgPrmExtCCPBytePosn5 VehCfgPrmExtCCPBytePosn3;
SIG_GROUP_ 549 VehCfgPrm 1 : VehCfgPrmCCPBytePosn6 VehCfgPrmCCPBytePosn5 VehCfgPrmCCPBytePosn7 VehCfgPrmCCPBytePosn8 VehCfgPrmBlkIDBytePosn1 VehCfgPrmCCPBytePosn4 VehCfgPrmCCPBytePosn2 VehCfgPrmCCPBytePosn3;
SIG_GROUP_ 752 ULoWarnLvPwrErr 1 : ULoWarnLvPwrErrULoWarn ULoWarnLvPwrErrChks ULoWarnLvPwrErrLVPwrSplyErrSts ULoWarnLvPwrErrCntr;
SIG_GROUP_ 752 CmptmtTFrnt 1 : CmptmtTFrntFanForCmptmtTRunng CmptmtTFrntQf CmptmtTFrntCmptmtTFrnt;
SIG_GROUP_ 1345 VFCVectorZCUDM 1 : VFCVectorZCUDMVFCid3 VFCVectorZCUDMVFCid34 VFCVectorZCUDMVFCid44 VFCVectorZCUDMVFCid53 VFCVectorZCUDMVFCid31 VFCVectorZCUDMVFCid12 VFCVectorZCUDMVFCid5 VFCVectorZCUDMVFCid6 VFCVectorZCUDMVFCid26 VFCVectorZCUDMVFCid17 VFCVectorZCUDMVFCid38 VFCVectorZCUDMVFCid0 VFCVectorZCUDMVFCid60 VFCVectorZCUDMVFCid8 VFCVectorZCUDMVFCid47 VFCVectorZCUDMVFCid9 VFCVectorZCUDMVFCid28 VFCVectorZCUDMVFCid59 VFCVectorZCUDMVFCid22 VFCVectorZCUDMVFCid27 VFCVectorZCUDMVFCid4 VFCVectorZCUDMVFCid14 VFCVectorZCUDMVFCid7 VFCVectorZCUDMVFCid2 VFCVectorZCUDMVFCid40 VFCVectorZCUDMVFCid58 VFCVectorZCUDMVFCid11 VFCVectorZCUDMVFCid55 VFCVectorZCUDMVFCid19 VFCVectorZCUDMVFCid46 VFCVectorZCUDMVFCid1 VFCVectorZCUDMVFCid21 VFCVectorZCUDMVFCid52 VFCVectorZCUDMVFCid61 VFCVectorZCUDMVFCid20 VFCVectorZCUDMVFCid13 VFCVectorZCUDMVFCid16 VFCVectorZCUDMVFCid39 VFCVectorZCUDMVFCid25 VFCVectorZCUDMVFCid54 VFCVectorZCUDMVFCid57 VFCVectorZCUDMVFCid48 VFCVectorZCUDMVFCid56 VFCVectorZCUDMVFCid36 VFCVectorZCUDMVFCid50 VFCVectorZCUDMVFCid15 VFCVectorZCUDMVFCid35 VFCVectorZCUDMVFCid29 VFCVectorZCUDMVFCid30 VFCVectorZCUDMVFCid45 VFCVectorZCUDMVFCid32 VFCVectorZCUDMVFCid41 VFCVectorZCUDMVFCid51 VFCVectorZCUDMVFCid42 VFCVectorZCUDMVFCid43 VFCVectorZCUDMVFCid37 VFCVectorZCUDMVFCid23 VFCVectorZCUDMVFCid33 VFCVectorZCUDMVFCid18 VFCVectorZCUDMVFCid49 VFCVectorZCUDMBlockID VFCVectorZCUDMVFCid24 VFCVectorZCUDMVFCid10;
SIG_GROUP_ 535 FASDrvModPrsnlAdjmt 1 : FASDrvModPrsnlAdjmtSuspLvlHL1Sts FASDrvModPrsnlAdjmtDamprHardSts FASDrvModPrsnlAdjmtDamprSts_Resv2 FASDrvModPrsnlAdjmtSuspLvlHL2Sts FASDrvModPrsnlAdjmtDamprMedSts FASDrvModPrsnlAdjmtDamprCmftSts FASDrvModPrsnlAdjmtSuspLvlLL2Sts FASDrvModPrsnlAdjmtSuspLvlLL1Sts FASDrvModPrsnlAdjmtDamprSts_Resv1 FASDrvModPrsnlAdjmtSuspLvlNRHSts;
SIG_GROUP_ 535 FASActFAry 1 : FASActFAryFR FASActFAryRL FASActFAryFL FASActFAryRR;
SIG_GROUP_ 535 FullActvSuspStabyCritFailrDetd 1 : FullActvSuspStabyCritFailrDetdSts FullActvSuspStabyCritFailrDetdCntr FullActvSuspStabyCritFailrDetdChks;
SIG_GROUP_ 535 FullActvSuspFailrSts 1 : FullActvSuspFailrStsSuspFailrStsCntr FullActvSuspFailrStsSuspFailrStsChks FullActvSuspFailrStsSuspFailrSts FullActvSuspFailrStsSuspFailrStsTypQf;
SIG_GROUP_ 101 FullActvSuspPosnVertLe 1 : FullActvSuspPosnVertLeChks FullActvSuspPosnVertLeReQf FullActvSuspPosnVertLeRe FullActvSuspPosnVertLeFrnt FullActvSuspPosnVertLeFrntQf;
SIG_GROUP_ 101 FullActvSuspPosnVertRi 1 : FullActvSuspPosnVertRiReQf FullActvSuspPosnVertRiRe FullActvSuspPosnVertRiFrnt FullActvSuspPosnVertRiChks FullActvSuspPosnVertRiFrntQf;
SIG_GROUP_ 1346 VFCVectorZCUT 1 : VFCVectorZCUTVFCid21 VFCVectorZCUTVFCid49 VFCVectorZCUTVFCid8 VFCVectorZCUTVFCid4 VFCVectorZCUTVFCid38 VFCVectorZCUTVFCid28 VFCVectorZCUTVFCid57 VFCVectorZCUTVFCid55 VFCVectorZCUTVFCid19 VFCVectorZCUTBlockID VFCVectorZCUTVFCid56 VFCVectorZCUTVFCid30 VFCVectorZCUTVFCid61 VFCVectorZCUTVFCid50 VFCVectorZCUTVFCid47 VFCVectorZCUTVFCid35 VFCVectorZCUTVFCid40 VFCVectorZCUTVFCid16 VFCVectorZCUTVFCid36 VFCVectorZCUTVFCid46 VFCVectorZCUTVFCid52 VFCVectorZCUTVFCid37 VFCVectorZCUTVFCid58 VFCVectorZCUTVFCid53 VFCVectorZCUTVFCid2 VFCVectorZCUTVFCid12 VFCVectorZCUTVFCid51 VFCVectorZCUTVFCid34 VFCVectorZCUTVFCid15 VFCVectorZCUTVFCid20 VFCVectorZCUTVFCid23 VFCVectorZCUTVFCid6 VFCVectorZCUTVFCid25 VFCVectorZCUTVFCid39 VFCVectorZCUTVFCid59 VFCVectorZCUTVFCid33 VFCVectorZCUTVFCid17 VFCVectorZCUTVFCid24 VFCVectorZCUTVFCid42 VFCVectorZCUTVFCid43 VFCVectorZCUTVFCid44 VFCVectorZCUTVFCid3 VFCVectorZCUTVFCid13 VFCVectorZCUTVFCid18 VFCVectorZCUTVFCid31 VFCVectorZCUTVFCid54 VFCVectorZCUTVFCid48 VFCVectorZCUTVFCid1 VFCVectorZCUTVFCid7 VFCVectorZCUTVFCid29 VFCVectorZCUTVFCid32 VFCVectorZCUTVFCid5 VFCVectorZCUTVFCid14 VFCVectorZCUTVFCid45 VFCVectorZCUTVFCid26 VFCVectorZCUTVFCid9 VFCVectorZCUTVFCid60 VFCVectorZCUTVFCid41 VFCVectorZCUTVFCid11 VFCVectorZCUTVFCid22 VFCVectorZCUTVFCid0 VFCVectorZCUTVFCid10 VFCVectorZCUTVFCid27;
